VERSION ""

NS_ :

BS_:

BU_: Dummy_PHS EBOOST_OBD_PHS EOCM2cp_IMX6_PHS EOCM2cp_K1_PHS EPSb_PHS EBCM_PHS EPSa_PHS CMMb_PHS CGM3a_PHS CMMa_PHS ADIMb_PHS

BO_ 355 RedPriDynCtrlStat_PHS: 8 EBCM_PHS
 SG_ RdRghnsStatRed : 44|1@0+ (1,0) [0|1] ""  ADIMb_PHS
 SG_ RdRghnsIndctnRed : 39|5@0+ (3.2258,0) [0|100] "%"  ADIMb_PHS
 SG_ PriTCSStatRed : 17|2@0+ (1,0) [0|3] ""  ADIMb_PHS
 SG_ PriGrsHydLkDtctdRed : 43|1@0+ (1,0) [0|1] ""  ADIMb_PHS
 SG_ PriGrsHydCmpDtctdRed : 42|1@0+ (1,0) [0|1] ""  ADIMb_PHS
 SG_ PriGrsBrkIneffDtctdRed : 41|1@0+ (1,0) [0|1] ""  ADIMb_PHS
 SG_ PriESCStatRed : 25|2@0+ (1,0) [0|3] ""  ADIMb_PHS
 SG_ PriDynCtrlStatRedChksm : 50|11@0+ (1,0) [0|2047] ""  ADIMb_PHS
 SG_ PriDynCtrlStatRedARC : 52|2@0+ (1,0) [0|3] ""  ADIMb_PHS
 SG_ PriDRPStatRed : 1|2@0+ (1,0) [0|3] ""  ADIMb_PHS
 SG_ PriABSStatRed : 9|2@0+ (1,0) [0|3] ""  ADIMb_PHS
 SG_ EstBrkRtrTempStatRed : 40|1@0+ (1,0) [0|1] ""  ADIMb_PHS
 SG_ EstBrkRtrTempRRRed : 31|6@0+ (8.5714,-40) [-40|500] "deg C"  ADIMb_PHS
 SG_ EstBrkRtrTempRFRed : 15|6@0+ (8.5714,-40) [-40|500] "deg C"  ADIMb_PHS
 SG_ EstBrkRtrTempLRRed : 23|6@0+ (8.5714,-40) [-40|500] "deg C"  ADIMb_PHS
 SG_ EstBrkRtrTempLFRed : 7|6@0+ (8.5714,-40) [-40|500] "deg C"  ADIMb_PHS
 SG_ EPBStatRed : 34|2@0+ (1,0) [0|3] ""  ADIMb_PHS
 SG_ EPBApplStRed : 47|2@0+ (1,0) [0|3] ""  ADIMb_PHS
 SG_ BrkFldLvlIndStatRed : 45|1@0+ (1,0) [0|1] ""  ADIMb_PHS
 SG_ BrkFldLvILwFldDtctdRed : 32|1@0+ (1,0) [0|1] ""  ADIMb_PHS

BO_ 341 AutoSteeringStatus_PHS: 8 EPSb_PHS
 SG_ StgCmndTgtAng : 18|11@0- (1,0) [-1024|1023] "deg"  CMMb_PHS,CMMa_PHS,ADIMb_PHS,EOCM2cp_K1_PHS
 SG_ StrgCmndMsgStatV : 35|1@0+ (1,0) [0|1] ""  CMMb_PHS,CMMa_PHS,ADIMb_PHS,EOCM2cp_K1_PHS
 SG_ StrgCmndMsgStat : 5|2@0+ (1,0) [0|3] ""  CMMb_PHS,CMMa_PHS,ADIMb_PHS,EOCM2cp_K1_PHS
 SG_ StrgCmndMsgUtlzdV : 19|1@0+ (1,0) [0|1] ""  CMMb_PHS,CMMa_PHS,ADIMb_PHS,EOCM2cp_K1_PHS
 SG_ StrgCmndMsgUtlzd : 20|1@0+ (1,0) [0|1] ""  CMMb_PHS,CMMa_PHS,ADIMb_PHS,EOCM2cp_K1_PHS
 SG_ AutoStrgCmndStatV : 6|1@0+ (1,0) [0|1] ""  CMMb_PHS,CMMa_PHS,ADIMb_PHS,EOCM2cp_K1_PHS
 SG_ StgTtlEffTrqDlvd : 33|10@0- (0.25,0) [-128|127.75] ""  CMMb_PHS,CMMa_PHS,EBOOST_OBD_PHS,EBCM_PHS,ADIMb_PHS,EOCM2cp_K1_PHS
 SG_ StgTrqSnsrVStat : 39|1@0+ (1,0) [0|1] ""  CMMb_PHS,CMMa_PHS,EBOOST_OBD_PHS,EBCM_PHS,ADIMb_PHS,EOCM2cp_K1_PHS
 SG_ StgSysOtptStatV : 7|1@0+ (1,0) [0|1] ""  CMMb_PHS,CMMa_PHS,ADIMb_PHS,EOCM2cp_K1_PHS
 SG_ StgSysOtptStat : 3|2@0+ (1,0) [0|3] ""  CMMb_PHS,CMMa_PHS,ADIMb_PHS,EOCM2cp_K1_PHS
 SG_ StgOtptTempLmtgSte : 23|3@0+ (1,0) [0|7] ""  CMMb_PHS,CMMa_PHS,ADIMb_PHS,EOCM2cp_K1_PHS
 SG_ StgAngRtLmtV : 55|1@0+ (1,0) [0|1] ""  CMMb_PHS,CMMa_PHS,ADIMb_PHS,EOCM2cp_K1_PHS
 SG_ StgAngRtLmt : 1|10@0+ (1,0) [0|1023] "deg"  CMMb_PHS,CMMa_PHS,ADIMb_PHS,EOCM2cp_K1_PHS
 SG_ AutoStrgCmndStat : 38|3@0+ (1,0) [0|7] ""  CMMb_PHS,CMMa_PHS,ADIMb_PHS,EOCM2cp_K1_PHS
 SG_ AutoStgStatChksm : 50|11@0+ (1,0) [0|2047] ""  CMMb_PHS,CMMa_PHS,ADIMb_PHS,EOCM2cp_K1_PHS
 SG_ AutoStgStatARC : 52|2@0+ (1,0) [0|3] ""  CMMb_PHS,CMMa_PHS,ADIMb_PHS,EOCM2cp_K1_PHS
 SG_ StgOvrdDetn : 54|2@0+ (1,0) [0|3] ""  CMMb_PHS,CMMa_PHS,EOCM2cp_K1_PHS,ADIMb_PHS,EBOOST_OBD_PHS,EBCM_PHS

BO_ 313 Body_Information_4_PHS: 8 CGM3a_PHS
 SG_ LnchCtrlRelLnLockReqd : 15|1@0+ (1,0) [0|1] ""  EBCM_PHS
 SG_ DrvrDrOpenSwVDA : 14|1@0+ (1,0) [0|1] "" Vector__XXX
 SG_ DrDoorOpenSwActV : 12|1@0+ (1,0) [0|1] ""  EOCM2cp_IMX6_PHS
 SG_ DrDoorOpenSwAct : 11|1@0+ (1,0) [0|1] ""  EOCM2cp_IMX6_PHS
 SG_ LnchCtrlWhlSlpReq : 55|5@0+ (1,0) [0|31] ""  EOCM2cp_IMX6_PHS,EBCM_PHS
 SG_ LnchCtrlMdReq : 57|2@0+ (1,0) [0|3] ""  EOCM2cp_IMX6_PHS,EBCM_PHS
 SG_ LnchCtrlEngRPMReq : 63|6@0+ (1,0) [0|63] ""  EOCM2cp_IMX6_PHS,EBCM_PHS
 SG_ ExtHlStrAssCsStRq : 50|3@0+ (1,0) [0|7] ""  EOCM2cp_IMX6_PHS,EBCM_PHS
 SG_ DrvStyPerfMdCsStReq : 45|3@0+ (1,0) [0|7] ""  EOCM2cp_IMX6_PHS,EBCM_PHS
 SG_ PsngStPerfMdCsStReq : 42|3@0+ (1,0) [0|7] ""  EOCM2cp_IMX6_PHS,EBCM_PHS
 SG_ DrvrStPerfMdCsStReq : 31|3@0+ (1,0) [0|7] ""  EOCM2cp_IMX6_PHS,EBCM_PHS
 SG_ ACCPerfMdCsStReq : 28|3@0+ (1,0) [0|7] ""  EOCM2cp_IMX6_PHS,EBCM_PHS
 SG_ PrkAstAdvSysAct : 8|1@0+ (1,0) [0|1] ""  EOCM2cp_IMX6_PHS
 SG_ SndPerfMdCsStRq : 18|3@0+ (1,0) [0|7] ""  EBCM_PHS,EOCM2cp_IMX6_PHS
 SG_ ACCSettingType : 10|2@0+ (1,0) [0|3] ""  EOCM2cp_IMX6_PHS
 SG_ FCABrkPrflReq : 13|1@0+ (1,0) [0|1] ""  EOCM2cp_IMX6_PHS,EBCM_PHS
 SG_ ISA2CCC_ScndCdChr : 36|5@0+ (1,0) [0|31] ""  EOCM2cp_IMX6_PHS
 SG_ ISA2CCC_FrstCdChr : 25|5@0+ (1,0) [0|31] ""  EOCM2cp_IMX6_PHS
 SG_ DispPerfMdCsStRq : 21|3@0+ (1,0) [0|7] ""  EOCM2cp_IMX6_PHS,EBCM_PHS
 SG_ FwdClnAlrtCustStngReq : 5|3@0+ (1,0) [0|7] ""  EOCM2cp_IMX6_PHS
 SG_ GNCustStngReq : 7|2@0+ (1,0) [0|3] ""  EOCM2cp_IMX6_PHS

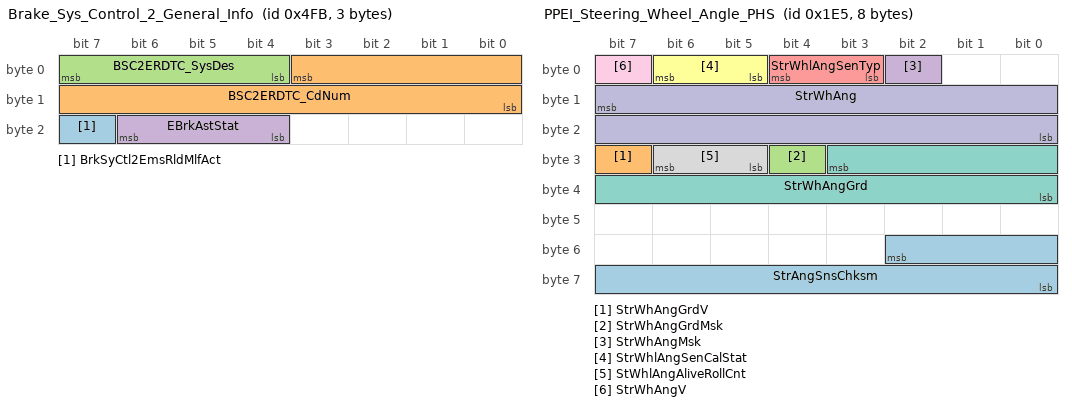
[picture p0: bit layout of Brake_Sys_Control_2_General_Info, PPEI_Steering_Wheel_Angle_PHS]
BO_ 1275 Brake_Sys_Control_2_General_Info: 3 EBOOST_OBD_PHS
 SG_ BrkSyCtl2EmsRldMlfAct : 23|1@0+ (1,0) [0|1] ""  CGM3a_PHS
 SG_ BSC2ERDTC_CdNum : 3|12@0+ (1,0) [0|4095] ""  CGM3a_PHS
 SG_ BSC2ERDTC_SysDes : 7|4@0+ (1,0) [0|15] ""  CGM3a_PHS
 SG_ EBrkAstStat : 22|3@0+ (1,0) [0|7] ""  EBCM_PHS,CGM3a_PHS

BO_ 381 Antilock_Brake_and_TC_Status_PHS: 8 EBCM_PHS
 SG_ HillDesCtrlRedVehSpIO : 39|1@0+ (1,0) [0|1] ""  CGM3a_PHS,EOCM2cp_IMX6_PHS
 SG_ EBDFailed : 23|1@0+ (1,0) [0|1] ""  CGM3a_PHS,EOCM2cp_IMX6_PHS
 SG_ StWhAnVDA : 17|1@0+ (1,0) [0|1] ""  CGM3a_PHS,EOCM2cp_IMX6_PHS
 SG_ TirePrsLowIO : 9|1@0+ (1,0) [0|1] ""  CGM3a_PHS,EOCM2cp_IMX6_PHS
 SG_ VaccBoostFailure : 16|1@0+ (1,0) [0|1] ""  CGM3a_PHS,EOCM2cp_IMX6_PHS
 SG_ VSESysPrs : 1|1@0+ (1,0) [0|1] ""  CGM3a_PHS,EOCM2cp_IMX6_PHS
 SG_ HalfSysFail : 18|1@0+ (1,0) [0|1] ""  CGM3a_PHS,EOCM2cp_IMX6_PHS
 SG_ ActVehAccel : 35|12@0- (0.01,0) [-20.48|20.47] "m/s^2"  CGM3a_PHS,EOCM2cp_IMX6_PHS
 SG_ ActVehAccelV : 20|1@0+ (1,0) [0|1] ""  CGM3a_PHS,EOCM2cp_IMX6_PHS
 SG_ BksOvht : 8|1@0+ (1,0) [0|1] ""  CGM3a_PHS,EOCM2cp_IMX6_PHS
 SG_ TCSysPr : 10|1@0+ (1,0) [0|1] ""  CGM3a_PHS,EOCM2cp_IMX6_PHS
 SG_ ABSPr : 22|1@0+ (1,0) [0|1] ""  CGM3a_PHS,EOCM2cp_IMX6_PHS
 SG_ TreInfMonSysRstPrfmd : 11|1@0+ (1,0) [0|1] ""  CGM3a_PHS,EOCM2cp_IMX6_PHS
 SG_ ABSIO : 12|1@0+ (1,0) [0|1] ""  CGM3a_PHS,EOCM2cp_IMX6_PHS
 SG_ BrkPadWrnIO : 0|1@0+ (1,0) [0|1] ""  CGM3a_PHS,EOCM2cp_IMX6_PHS
 SG_ VehStabEnhmntMd : 15|3@0+ (1,0) [0|7] ""  CGM3a_PHS,EOCM2cp_IMX6_PHS
 SG_ VehStabEnhmntStat : 4|3@0+ (1,0) [0|7] ""  CGM3a_PHS,EOCM2cp_IMX6_PHS
 SG_ TCSysOpMd : 7|3@0+ (1,0) [0|7] ""  CGM3a_PHS,EOCM2cp_IMX6_PHS
 SG_ TCSysOpStat : 38|3@0+ (1,0) [0|7] ""  CGM3a_PHS,EOCM2cp_IMX6_PHS
 SG_ BrkSysVTopSpdLimVal : 31|8@0+ (2,0) [0|510] "km / h"  CGM3a_PHS,EOCM2cp_IMX6_PHS
 SG_ BrkSysRedBrkTlltlReq : 19|1@0+ (1,0) [0|1] ""  CGM3a_PHS,EOCM2cp_IMX6_PHS
 SG_ BrkSysBrkLtsReqd : 21|1@0+ (1,0) [0|1] ""  CGM3a_PHS,EOCM2cp_IMX6_PHS

BO_ 485 PPEI_Steering_Wheel_Angle_PHS: 8 EPSb_PHS
 SG_ StrAngSnsChksm : 50|11@0+ (1,0) [0|2047] ""  CMMb_PHS,CMMa_PHS,ADIMb_PHS,EOCM2cp_K1_PHS,CGM3a_PHS
 SG_ StrWhAngGrdV : 31|1@0+ (1,0) [0|1] ""  CMMb_PHS,CMMa_PHS,ADIMb_PHS,EOCM2cp_K1_PHS,CGM3a_PHS
 SG_ StrWhAngGrdMsk : 28|1@0+ (1,0) [0|1] ""  CMMb_PHS,CMMa_PHS,ADIMb_PHS,EOCM2cp_K1_PHS,CGM3a_PHS
 SG_ StrWhAngMsk : 2|1@0+ (1,0) [0|1] ""  CMMb_PHS,CMMa_PHS,ADIMb_PHS,EOCM2cp_K1_PHS,CGM3a_PHS
 SG_ StrWhlAngSenTyp : 4|2@0+ (1,0) [0|3] ""  CMMb_PHS,CMMa_PHS,ADIMb_PHS,EOCM2cp_K1_PHS,CGM3a_PHS
 SG_ StrWhlAngSenCalStat : 6|2@0+ (1,0) [0|3] ""  CMMb_PHS,CMMa_PHS,ADIMb_PHS,EOCM2cp_K1_PHS,CGM3a_PHS
 SG_ StrWhAngGrd : 27|12@0- (1,0) [-2048|2047] "deg/sec"  CMMb_PHS,CMMa_PHS,ADIMb_PHS,EOCM2cp_K1_PHS,CGM3a_PHS
 SG_ StWhlAngAliveRollCnt : 30|2@0+ (1,0) [0|3] ""  CMMb_PHS,CMMa_PHS,ADIMb_PHS,EOCM2cp_K1_PHS,CGM3a_PHS
 SG_ StrWhAngV : 7|1@0+ (1,0) [0|1] ""  CMMb_PHS,CMMa_PHS,ADIMb_PHS,EOCM2cp_K1_PHS,CGM3a_PHS,EBCM_PHS
 SG_ StrWhAng : 15|16@0- (0.0625,0) [-2048|2047.9375] "deg"  CMMb_PHS,CMMa_PHS,ADIMb_PHS,EOCM2cp_K1_PHS,CGM3a_PHS,EBCM_PHS

BO_ 532 Brake_Pedal_Driver_Status_PHS: 6 EBCM_PHS
 SG_ RedntVSEActARC : 38|2@0+ (1,0) [0|3] ""  EOCM2cp_K1_PHS,CGM3a_PHS
 SG_ RedntVSEAct : 39|1@0+ (1,0) [0|1] ""  EOCM2cp_K1_PHS,CGM3a_PHS
 SG_ AutoBrkngActARC : 22|2@0+ (1,0) [0|3] ""  EOCM2cp_K1_PHS,CGM3a_PHS
 SG_ HilRlbkCtrlActIO : 19|1@0+ (1,0) [0|1] ""  EOCM2cp_K1_PHS,CGM3a_PHS
 SG_ VehHldDrvrDsblActvFlg : 36|1@0+ (1,0) [0|1] ""  EOCM2cp_K1_PHS,CGM3a_PHS
 SG_ ABSAutnmsBrkReqPVal : 41|2@0+ (1,0) [0|3] ""  EOCM2cp_K1_PHS,CGM3a_PHS
 SG_ AutoBrkngAvlbl : 17|1@0+ (1,0) [0|1] ""  EOCM2cp_K1_PHS,CGM3a_PHS
 SG_ ABSAutnmsBrkReqARC : 35|2@0+ (1,0) [0|3] ""  EOCM2cp_K1_PHS,CGM3a_PHS
 SG_ ABSAutnmsBrkReq : 33|1@0+ (1,0) [0|1] ""  EOCM2cp_K1_PHS,CGM3a_PHS
 SG_ ABSActvProtPVal : 43|2@0+ (1,0) [0|3] ""  EOCM2cp_K1_PHS,CGM3a_PHS
 SG_ ABSActvProtARC : 45|2@0+ (1,0) [0|3] ""  EOCM2cp_K1_PHS,CGM3a_PHS
 SG_ HlStrAssActIO : 20|1@0+ (1,0) [0|1] ""  EOCM2cp_K1_PHS,CGM3a_PHS
 SG_ BrkSysAutBrkFld : 5|1@0+ (1,0) [0|1] ""  EOCM2cp_K1_PHS,CGM3a_PHS
 SG_ IntBrkAssPreFilReq : 4|1@0+ (1,0) [0|1] "N/A"  EOCM2cp_K1_PHS,CGM3a_PHS
 SG_ BrkSysMalFuncIndOn : 3|1@0+ (1,0) [0|1] ""  EOCM2cp_K1_PHS,CGM3a_PHS
 SG_ BrkPdDrvAPrsStaPVal : 16|9@0+ (1,0) [0|511] ""  EOCM2cp_K1_PHS,CGM3a_PHS
 SG_ BPDAPS_BkPDrvApPV : 8|1@0+ (1,0) [0|1] ""  EOCM2cp_K1_PHS,CGM3a_PHS
 SG_ BPDAPS_BkPDrvApP : 0|8@0+ (75,0) [0|19125] "kPa"  EOCM2cp_K1_PHS,CGM3a_PHS
 SG_ BrkPdDrvAppPrsAlRC : 2|2@0+ (1,0) [0|3] ""  EOCM2cp_K1_PHS,CGM3a_PHS
 SG_ BrkFldLvlLwV : 7|1@0+ (1,0) [0|1] ""  EOCM2cp_K1_PHS,CGM3a_PHS
 SG_ AutoBrkngAct : 18|1@0+ (1,0) [0|1] ""  EOCM2cp_K1_PHS,CGM3a_PHS
 SG_ BrkFldLvlLw : 6|1@0+ (1,0) [0|1] ""  EOCM2cp_K1_PHS,CGM3a_PHS
 SG_ ABSActvProt : 46|1@0+ (1,0) [0|1] ""  CGM3a_PHS,EOCM2cp_K1_PHS

BO_ 489 PPEI_Chassis_Generl_Status_1_PHS: 8 EBCM_PHS
 SG_ EnhDrvMdSwChUseRq : 53|1@0+ (1,0) [0|1] ""  EOCM2cp_K1_PHS,CGM3a_PHS
 SG_ IMUDataMsk : 25|1@0+ (1,0) [0|1] ""  EOCM2cp_K1_PHS,CGM3a_PHS
 SG_ DrvIndpntBrkAppAct : 55|1@0+ (1,0) [0|1] ""  EOCM2cp_K1_PHS,CGM3a_PHS
 SG_ WhlSlpSt : 52|2@0+ (1,0) [0|3] ""  EOCM2cp_K1_PHS,CGM3a_PHS
 SG_ BSTGRReqdGear : 19|4@0+ (1,0) [0|15] ""  EOCM2cp_K1_PHS,CGM3a_PHS
 SG_ BSTGRReqType : 21|2@0+ (1,0) [0|3] ""  EOCM2cp_K1_PHS,CGM3a_PHS
 SG_ VehDynOvrUndrStr : 49|10@0- (0.5,0) [-256|255.5] "%"  EOCM2cp_K1_PHS,CGM3a_PHS
 SG_ VSELatAccV : 4|1@0+ (1,0) [0|1] ""  EPSb_PHS,EPSa_PHS,CGM3a_PHS,EOCM2cp_K1_PHS
 SG_ VSELatAcc : 3|12@0- (0.015625,0) [-32|31.984375] "m/s^2"  EPSb_PHS,EPSa_PHS,CGM3a_PHS,EOCM2cp_K1_PHS
 SG_ VSEAct : 24|1@0+ (1,0) [0|1] ""  EOCM2cp_K1_PHS,CGM3a_PHS
 SG_ VhDynCntlSysSt : 39|3@0+ (1,0) [0|7] ""  CGM3a_PHS,EOCM2cp_K1_PHS
 SG_ VehDynYawRateV : 36|1@0+ (1,0) [0|1] ""  CGM3a_PHS,EOCM2cp_K1_PHS
 SG_ VehDynYawRate : 35|12@0- (0.0625,0) [-128|127.9375] "deg/sec"  CGM3a_PHS,EOCM2cp_K1_PHS
 SG_ TrnsBrkSysCltchRelRqd : 5|1@0+ (1,0) [0|1] ""  EOCM2cp_K1_PHS,CGM3a_PHS
 SG_ TracCntrlSysDrIntnt : 26|1@0+ (1,0) [0|1] ""  EOCM2cp_K1_PHS,CGM3a_PHS
 SG_ VehDynOvrUndrStrV : 50|1@0+ (1,0) [0|1] ""  EOCM2cp_K1_PHS,CGM3a_PHS
 SG_ TCSysEnbld : 27|1@0+ (1,0) [0|1] ""  CGM3a_PHS,EOCM2cp_K1_PHS
 SG_ TCSysAtv : 28|1@0+ (1,0) [0|1] ""  CGM3a_PHS,EOCM2cp_K1_PHS
 SG_ BrkPdlDrvAppPrsDetcdV : 7|1@0+ (1,0) [0|1] ""  CGM3a_PHS,EOCM2cp_K1_PHS
 SG_ BrkPdlDrvAppPrsDetcd : 6|1@0+ (1,0) [0|1] ""  CGM3a_PHS,EOCM2cp_K1_PHS
 SG_ ACCBrkngAct : 31|1@0+ (1,0) [0|1] ""  EOCM2cp_K1_PHS,CGM3a_PHS
 SG_ ABSFld : 29|1@0+ (1,0) [0|1] ""  EOCM2cp_K1_PHS,CGM3a_PHS
 SG_ ABSAtv : 30|1@0+ (1,0) [0|1] ""  EOCM2cp_K1_PHS,CGM3a_PHS

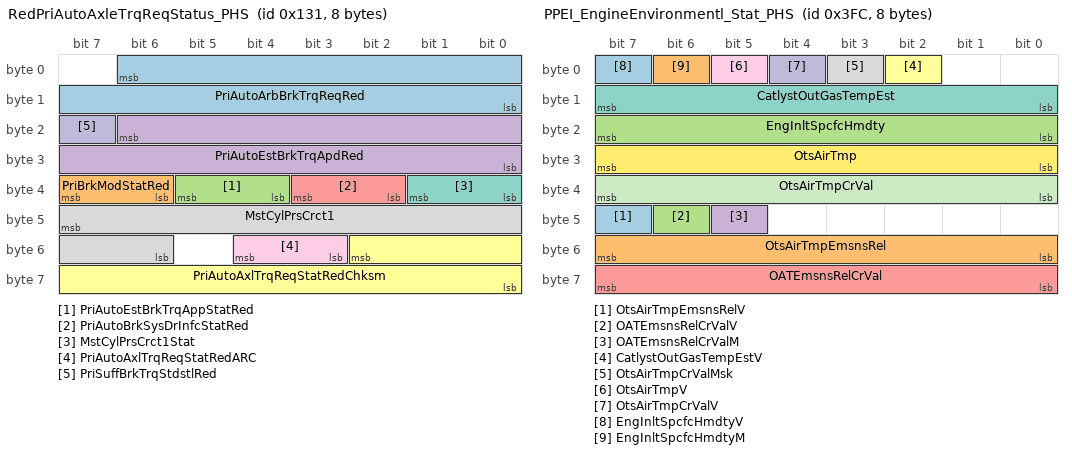
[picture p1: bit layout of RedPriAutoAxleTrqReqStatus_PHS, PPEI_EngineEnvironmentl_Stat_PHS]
BO_ 305 RedPriAutoAxleTrqReqStatus_PHS: 8 EBCM_PHS
 SG_ PriAutoArbBrkTrqReqRed : 6|15@0+ (2,-65534) [-65534|0] "Nm"  CGM3a_PHS,ADIMb_PHS
 SG_ PriBrkModStatRed : 39|2@0+ (1,0) [0|3] ""  CGM3a_PHS,ADIMb_PHS
 SG_ PriAutoEstBrkTrqAppStatRed : 37|2@0+ (1,0) [0|3] ""  CGM3a_PHS,ADIMb_PHS
 SG_ PriAutoEstBrkTrqApdRed : 22|15@0+ (2,-65534) [-65534|0] "Nm"  CGM3a_PHS,ADIMb_PHS
 SG_ PriAutoBrkSysDrInfcStatRed : 35|2@0+ (1,0) [0|3] ""  CGM3a_PHS,EBOOST_OBD_PHS,ADIMb_PHS
 SG_ PriAutoAxlTrqReqStatRedChksm : 50|11@0+ (1,0) [0|2047] ""  CGM3a_PHS,ADIMb_PHS
 SG_ MstCylPrsCrct1Stat : 33|2@0+ (1,0) [0|3] ""  CGM3a_PHS,ADIMb_PHS,EBOOST_OBD_PHS
 SG_ MstCylPrsCrct1 : 47|10@0+ (0.3,0) [0|276.6] "bar"  CGM3a_PHS,EBOOST_OBD_PHS,ADIMb_PHS
 SG_ PriAutoAxlTrqReqStatRedARC : 52|2@0+ (1,0) [0|3] ""  CGM3a_PHS,ADIMb_PHS
 SG_ PriSuffBrkTrqStdstlRed : 23|1@0+ (1,0) [0|1] ""  CGM3a_PHS,ADIMb_PHS

BO_ 1020 PPEI_EngineEnvironmentl_Stat_PHS: 8 CGM3a_PHS
 SG_ OtsAirTmpEmsnsRelV : 47|1@0+ (1,0) [0|1] "" Vector__XXX
 SG_ OtsAirTmpEmsnsRel : 55|8@0+ (0.5,-40) [-40|87.5] "deg C" Vector__XXX
 SG_ OATEmsnsRelCrValV : 46|1@0+ (1,0) [0|1] "" Vector__XXX
 SG_ OATEmsnsRelCrValM : 45|1@0+ (1,0) [0|1] "" Vector__XXX
 SG_ OATEmsnsRelCrVal : 63|8@0+ (0.5,-40) [-40|87.5] "deg C" Vector__XXX
 SG_ CatlystOutGasTempEstV : 2|1@0+ (1,0) [0|1] "" Vector__XXX
 SG_ CatlystOutGasTempEst : 15|8@0+ (5,-40) [-40|1235] "deg C" Vector__XXX
 SG_ OtsAirTmpCrValMsk : 3|1@0+ (1,0) [0|1] "" Vector__XXX
 SG_ OtsAirTmpV : 5|1@0+ (1,0) [0|1] "" Vector__XXX
 SG_ OtsAirTmpCrValV : 4|1@0+ (1,0) [0|1] "" Vector__XXX
 SG_ OtsAirTmpCrVal : 39|8@0+ (0.5,-40) [-40|87.5] "deg C" Vector__XXX
 SG_ OtsAirTmp : 31|8@0+ (0.5,-40) [-40|87.5] "deg C" Vector__XXX
 SG_ EngInltSpcfcHmdtyV : 7|1@0+ (1,0) [0|1] ""  EBCM_PHS
 SG_ EngInltSpcfcHmdtyM : 6|1@0+ (1,0) [0|1] ""  EBCM_PHS
 SG_ EngInltSpcfcHmdty : 23|8@0+ (0.0196078,0) [0|4.999989] "% water"  EBCM_PHS

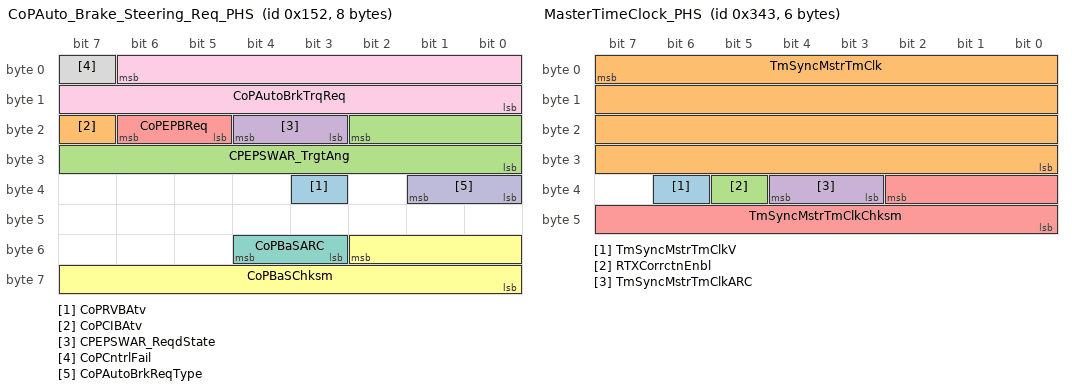
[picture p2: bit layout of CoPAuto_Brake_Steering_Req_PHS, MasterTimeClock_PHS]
BO_ 338 CoPAuto_Brake_Steering_Req_PHS: 8 EOCM2cp_K1_PHS
 SG_ CoPRVBAtv : 35|1@0+ (1,0) [0|1] ""  ADIMb_PHS,EBOOST_OBD_PHS,EBCM_PHS
 SG_ CoPCIBAtv : 23|1@0+ (1,0) [0|1] ""  ADIMb_PHS,EBOOST_OBD_PHS,EBCM_PHS
 SG_ CPEPSWAR_TrgtAng : 18|11@0- (1,0) [-1024|1023] "deg"  ADIMb_PHS,EBOOST_OBD_PHS,EBCM_PHS
 SG_ CPEPSWAR_ReqdState : 20|2@0+ (1,0) [0|3] ""  ADIMb_PHS,EBOOST_OBD_PHS,EBCM_PHS
 SG_ CoPEPBReq : 22|2@0+ (1,0) [0|3] ""  ADIMb_PHS,EBOOST_OBD_PHS,EBCM_PHS
 SG_ CoPBaSChksm : 50|11@0+ (1,0) [0|2047] ""  ADIMb_PHS,EBOOST_OBD_PHS,EBCM_PHS
 SG_ CoPBaSARC : 52|2@0+ (1,0) [0|3] ""  ADIMb_PHS,EBOOST_OBD_PHS,EBCM_PHS
 SG_ CoPCntrlFail : 7|1@0+ (1,0) [0|1] ""  ADIMb_PHS,EBOOST_OBD_PHS,EBCM_PHS
 SG_ CoPAutoBrkTrqReq : 6|15@0+ (2,-65534) [-65534|0] "Nm"  ADIMb_PHS,EBOOST_OBD_PHS,EBCM_PHS
 SG_ CoPAutoBrkReqType : 33|2@0+ (1,0) [0|3] ""  ADIMb_PHS,EBOOST_OBD_PHS,EBCM_PHS

BO_ 835 MasterTimeClock_PHS: 6 EOCM2cp_K1_PHS
 SG_ TmSyncMstrTmClkV : 38|1@0+ (1,0) [0|1] ""  CGM3a_PHS
 SG_ TmSyncMstrTmClk : 7|32@0+ (1,0) [0|4294967295] "ms"  CGM3a_PHS
 SG_ RTXCorrctnEnbl : 37|1@0+ (1,0) [0|1] ""  CGM3a_PHS
 SG_ TmSyncMstrTmClkARC : 36|2@0+ (1,0) [0|3] ""  CGM3a_PHS
 SG_ TmSyncMstrTmClkChksm : 34|11@0+ (1,0) [0|2047] ""  CGM3a_PHS

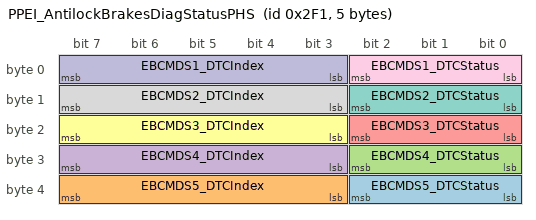
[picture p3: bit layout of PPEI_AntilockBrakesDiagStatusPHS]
BO_ 753 PPEI_AntilockBrakesDiagStatusPHS: 5 EBCM_PHS
 SG_ EBCMDS5_DTCStatus : 34|3@0+ (1,0) [0|7] ""  CGM3a_PHS
 SG_ EBCMDS5_DTCIndex : 39|5@0+ (1,0) [0|31] ""  CGM3a_PHS
 SG_ EBCMDS4_DTCStatus : 26|3@0+ (1,0) [0|7] ""  CGM3a_PHS
 SG_ EBCMDS4_DTCIndex : 31|5@0+ (1,0) [0|31] ""  CGM3a_PHS
 SG_ EBCMDS3_DTCStatus : 18|3@0+ (1,0) [0|7] ""  CGM3a_PHS
 SG_ EBCMDS3_DTCIndex : 23|5@0+ (1,0) [0|31] ""  CGM3a_PHS
 SG_ EBCMDS2_DTCStatus : 10|3@0+ (1,0) [0|7] ""  CGM3a_PHS
 SG_ EBCMDS2_DTCIndex : 15|5@0+ (1,0) [0|31] ""  CGM3a_PHS
 SG_ EBCMDS1_DTCStatus : 2|3@0+ (1,0) [0|7] ""  CGM3a_PHS
 SG_ EBCMDS1_DTCIndex : 7|5@0+ (1,0) [0|31] ""  CGM3a_PHS

BO_ 869 CPS_Collision_Preparation_IO_PHS: 4 EOCM2cp_K1_PHS
 SG_ TnDrvGapAdjUnbIO : 4|1@0+ (1,0) [0|1] ""  CGM3a_PHS
 SG_ CPSCA_Resrv3Avail : 25|1@0+ (1,0) [0|1] ""  CGM3a_PHS
 SG_ CPSCA_Resrv2Avail : 26|1@0+ (1,0) [0|1] ""  CGM3a_PHS
 SG_ CPSCA_Resrv1Avail : 27|1@0+ (1,0) [0|1] ""  CGM3a_PHS
 SG_ CPSCA_AlrtBrkStrAvail : 28|1@0+ (1,0) [0|1] ""  CGM3a_PHS
 SG_ CPSCA_AlrtBrkAvail : 29|1@0+ (1,0) [0|1] ""  CGM3a_PHS
 SG_ CPSCA_AlrtAvail : 30|1@0+ (1,0) [0|1] ""  CGM3a_PHS
 SG_ CPSCA_OffAvail : 31|1@0+ (1,0) [0|1] ""  CGM3a_PHS
 SG_ FwdClnMtgnBrkReqAct : 3|1@0+ (1,0) [0|1] ""  CGM3a_PHS
 SG_ FCACustStngAvlbl : 23|1@0+ (1,0) [0|1] ""  CGM3a_PHS
 SG_ FwdClnAlrtCustCrntSetngVal : 12|3@0+ (1,0) [0|7] ""  CGM3a_PHS
 SG_ GNCustSetngAvlbl : 9|1@0+ (1,0) [0|1] ""  CGM3a_PHS
 SG_ CPSUnblIO : 8|1@0+ (1,0) [0|1] ""  CGM3a_PHS
 SG_ ColPrSysStngAvl : 7|1@0+ (1,0) [0|1] ""  CGM3a_PHS
 SG_ CPSOffIO : 6|1@0+ (1,0) [0|1] ""  CGM3a_PHS
 SG_ CPSFldIO : 5|1@0+ (1,0) [0|1] ""  CGM3a_PHS
 SG_ ColPrSysCrntStng : 22|3@0+ (1,0) [0|7] ""  CGM3a_PHS
 SG_ CPSAlrtOnlIO : 2|1@0+ (1,0) [0|1] ""  CGM3a_PHS
 SG_ GNCustCrntStngVal : 15|3@0+ (1,0) [0|7] ""  CGM3a_PHS
 SG_ CoPilotWndShldWashReqAct : 24|1@0+ (1,0) [0|1] ""  CGM3a_PHS

BO_ 1217 PPEI_Engine_General_Status_4_PHS: 8 CGM3a_PHS
 SG_ LDMinEngCltTmpRchd : 43|1@0+ (1,0) [0|1] "" Vector__XXX
 SG_ LegPstDTCClrDrvCyCm : 40|1@0+ (1,0) [0|1] ""  EBCM_PHS,EBOOST_OBD_PHS
 SG_ LegDiagColdStCndMet : 47|1@0+ (1,0) [0|1] ""  EBCM_PHS
 SG_ LegDiagColdStCndFltPr : 46|1@0+ (1,0) [0|1] ""  EBCM_PHS
 SG_ EngEconMdCmnd : 44|1@0+ (1,0) [0|1] "" Vector__XXX
 SG_ DslExhFldRmngDstHRsV : 41|1@0+ (1,0) [0|1] "" Vector__XXX
 SG_ DslExhFldRmngDstHRs : 54|15@0+ (2,0) [0|65534] "km" Vector__XXX
 SG_ EngOilHotIO : 45|1@0+ (1,0) [0|1] "" Vector__XXX
 SG_ OAT_PT_EstV : 3|1@0+ (1,0) [0|1] ""  EBCM_PHS
 SG_ LegDiagStndCndMet : 2|1@0+ (1,0) [0|1] ""  EBCM_PHS
 SG_ LegDiagStndCndFltPr : 1|1@0+ (1,0) [0|1] ""  EBCM_PHS
 SG_ OAT_PT_EstM : 4|1@0+ (1,0) [0|1] ""  EBCM_PHS
 SG_ OAT_PT_Est : 39|8@0+ (0.5,-40) [-40|87.5] "deg C"  EBCM_PHS
 SG_ EngWrmUpAch : 0|1@0+ (1,0) [0|1] ""  EBOOST_OBD_PHS,EBCM_PHS
 SG_ EngIntAirTmpV : 5|1@0+ (1,0) [0|1] ""  EBCM_PHS
 SG_ EngIntAirTmp : 31|8@0+ (1,-40) [-40|215] "deg C"  EBCM_PHS
 SG_ EngCltTmpV : 6|1@0+ (1,0) [0|1] ""  EBCM_PHS,EPSb_PHS,EPSa_PHS
 SG_ EngCltTmp : 23|8@0+ (1,-40) [-40|215] "deg C"  EBCM_PHS,EPSb_PHS,EPSa_PHS
 SG_ BarPrsAbsV : 7|1@0+ (1,0) [0|1] ""  EBCM_PHS
 SG_ BarPrsAbs : 15|8@0+ (0.5,0) [0|127.5] "kPa"  EBCM_PHS

BO_ 328 Power_Steering_Information_PHS: 1 EPSa_PHS
 SG_ StrngAsstRdcdIO : 1|1@0+ (1,0) [0|1] ""  CGM3a_PHS
 SG_ PwrStrIO : 0|1@0+ (1,0) [0|1] ""  CGM3a_PHS

BO_ 309 Body_Information_2_PHS: 8 CGM3a_PHS
 SG_ PedFrndlyAlrtSndMnAct : 8|1@0+ (1,0) [0|1] "" Vector__XXX
 SG_ ColPrSysCustReq : 15|3@0+ (1,0) [0|7] ""  EOCM2cp_IMX6_PHS
 SG_ SecV : 62|1@0+ (1,0) [0|1] ""  EOCM2cp_IMX6_PHS
 SG_ Sec : 61|6@0+ (1,0) [0|63] "s"  EOCM2cp_IMX6_PHS
 SG_ CldrYr_154 : 55|8@0+ (1,2000) [2000|2255] "year"  EOCM2cp_IMX6_PHS
 SG_ CldrYr : 47|8@0+ (1,2000) [2000|2255] "year"  EBCM_PHS,EOCM2cp_IMX6_PHS
 SG_ CldrMth_154 : 39|4@0+ (1,0) [0|15] ""  EOCM2cp_IMX6_PHS
 SG_ CldrMth : 35|4@0+ (1,0) [0|15] ""  EBCM_PHS,EOCM2cp_IMX6_PHS
 SG_ CldrDay_154 : 30|5@0+ (1,0) [0|31] "days"  EOCM2cp_IMX6_PHS
 SG_ CldrDay : 20|5@0+ (1,0) [0|31] "days"  EBCM_PHS,EOCM2cp_IMX6_PHS
 SG_ AutoHiBmVDA : 25|1@0+ (1,0) [0|1] ""  EOCM2cp_IMX6_PHS
 SG_ CtLghtDet : 24|1@0+ (1,0) [0|1] ""  EOCM2cp_IMX6_PHS
 SG_ RrClosVDA : 11|1@0+ (1,0) [0|1] ""  EOCM2cp_IMX6_PHS
 SG_ TCSysDisSwAtv : 4|1@0+ (1,0) [0|1] ""  EBCM_PHS,EOCM2cp_IMX6_PHS
 SG_ VehMovState : 2|3@0+ (1,0) [0|7] ""  EOCM2cp_IMX6_PHS
 SG_ TCSysDisSwAtvV : 3|1@0+ (1,0) [0|1] ""  EBCM_PHS,EOCM2cp_IMX6_PHS
 SG_ HillDesCtrlMdSwActV : 10|1@0+ (1,0) [0|1] ""  EBCM_PHS,EOCM2cp_IMX6_PHS
 SG_ WSWshSwAtv : 5|1@0+ (1,0) [0|1] ""  EOCM2cp_IMX6_PHS
 SG_ HillDesCtrlMdSwAct : 9|1@0+ (1,0) [0|1] ""  EBCM_PHS,EOCM2cp_IMX6_PHS
 SG_ RrClosAjarSwAct : 12|1@0+ (1,0) [0|1] ""  EOCM2cp_IMX6_PHS
 SG_ WSWprAct : 6|1@0+ (1,0) [0|1] ""  EOCM2cp_IMX6_PHS,EBCM_PHS

BO_ 1622 USDT_Resp_From_CMMb_PHS: 8 CMMb_PHS
 SG_ DgnInf : 7|64@0+ (1,0) [0|1.84467440737096E+019] ""  CGM3a_PHS

BO_ 1905 DTC_Triggered_771_PHS: 7 EBOOST_OBD_PHS
 SG_ DTCI_DTCFaultType_771 : 55|8@0+ (1,0) [0|255] ""  CGM3a_PHS
 SG_ DTCI_CodeSupported_771 : 40|1@0+ (1,0) [0|1] ""  CGM3a_PHS
 SG_ DTCI_CurrentStatus_771 : 41|1@0+ (1,0) [0|1] ""  CGM3a_PHS
 SG_ DTCI_TstNPsdCdClrdSt_771 : 42|1@0+ (1,0) [0|1] ""  CGM3a_PHS
 SG_ DTCI_TstFldCdClrdStat_771 : 43|1@0+ (1,0) [0|1] ""  CGM3a_PHS
 SG_ DTCI_HistStat_771 : 44|1@0+ (1,0) [0|1] ""  CGM3a_PHS
 SG_ DTCI_TstNPsdPwrUpSt_771 : 45|1@0+ (1,0) [0|1] ""  CGM3a_PHS
 SG_ DTCI_TstFldPwrUpSt_771 : 46|1@0+ (1,0) [0|1] ""  CGM3a_PHS
 SG_ DTCI_WrnIndRqdSt_771 : 47|1@0+ (1,0) [0|1] ""  CGM3a_PHS
 SG_ DTCI_DTCFailType_771 : 39|8@0+ (1,0) [0|255] ""  CGM3a_PHS
 SG_ DTCI_DTCNumber_771 : 23|16@0+ (1,0) [0|65535] ""  CGM3a_PHS
 SG_ DTCI_DTCSource_771 : 15|8@0+ (1,0) [0|255] ""  CGM3a_PHS
 SG_ DTCI_DTCTriggered_771 : 0|1@0+ (1,0) [0|1] ""  CGM3a_PHS
 SG_ DTCIUnused7_771 : 1|1@0+ (1,0) [0|1] ""  CGM3a_PHS
 SG_ DTCIUnused6_771 : 2|1@0+ (1,0) [0|1] ""  CGM3a_PHS
 SG_ DTCIUnused5_771 : 3|1@0+ (1,0) [0|1] ""  CGM3a_PHS
 SG_ DTCIUnused4_771 : 4|1@0+ (1,0) [0|1] ""  CGM3a_PHS
 SG_ DTCIUnused3_771 : 5|1@0+ (1,0) [0|1] ""  CGM3a_PHS
 SG_ DTCIUnused2_771 : 6|1@0+ (1,0) [0|1] ""  CGM3a_PHS
 SG_ DTCIUnused1_771 : 7|1@0+ (1,0) [0|1] ""  CGM3a_PHS

BO_ 1930 DTC_Triggered_78A_PHS: 7 EOCM2cp_K1_PHS
 SG_ DTCI_CodeSupported_78A : 40|1@0+ (1,0) [0|1] ""  CGM3a_PHS
 SG_ DTCI_CurrentStatus_78A : 41|1@0+ (1,0) [0|1] ""  CGM3a_PHS
 SG_ DTCI_DTCFailType_78A : 39|8@0+ (1,0) [0|255] ""  CGM3a_PHS
 SG_ DTCI_DTCFaultType_78A : 55|8@0+ (1,0) [0|255] ""  CGM3a_PHS
 SG_ DTCI_DTCNumber_78A : 23|16@0+ (1,0) [0|65535] ""  CGM3a_PHS
 SG_ DTCI_DTCSource_78A : 15|8@0+ (1,0) [0|255] ""  CGM3a_PHS
 SG_ DTCI_DTCTriggered_78A : 0|1@0+ (1,0) [0|1] ""  CGM3a_PHS
 SG_ DTCI_HistStat_78A : 44|1@0+ (1,0) [0|1] ""  CGM3a_PHS
 SG_ DTCI_TstFldCdClrdStat_78A : 43|1@0+ (1,0) [0|1] ""  CGM3a_PHS
 SG_ DTCI_TstFldPwrUpSt_78A : 46|1@0+ (1,0) [0|1] ""  CGM3a_PHS
 SG_ DTCI_TstNPsdCdClrdSt_78A : 42|1@0+ (1,0) [0|1] ""  CGM3a_PHS
 SG_ DTCI_TstNPsdPwrUpSt_78A : 45|1@0+ (1,0) [0|1] ""  CGM3a_PHS
 SG_ DTCIUnused1_78A : 7|1@0+ (1,0) [0|1] ""  CGM3a_PHS
 SG_ DTCIUnused2_78A : 6|1@0+ (1,0) [0|1] ""  CGM3a_PHS
 SG_ DTCIUnused3_78A : 5|1@0+ (1,0) [0|1] ""  CGM3a_PHS
 SG_ DTCIUnused4_78A : 4|1@0+ (1,0) [0|1] ""  CGM3a_PHS
 SG_ DTCIUnused5_78A : 3|1@0+ (1,0) [0|1] ""  CGM3a_PHS
 SG_ DTCIUnused6_78A : 2|1@0+ (1,0) [0|1] ""  CGM3a_PHS
 SG_ DTCIUnused7_78A : 1|1@0+ (1,0) [0|1] ""  CGM3a_PHS
 SG_ DTCI_WrnIndRqdSt_78A : 47|1@0+ (1,0) [0|1] ""  CGM3a_PHS

CM_ SG_ 381 BrkSysRedBrkTlltlReq "Added acc to Björn 0410";
CM_ BO_ 485 "6443-Power Steering Indication On in this frame not used by GlobalA /JD";
CM_ SG_ 532 BrkSysAutBrkFld "BrakeSystemAutomaticBrakingFailed";
CM_ SG_ 532 IntBrkAssPreFilReq "IntelligentBrakeAssistPreFillRequest";
CM_ BO_ 489 "Changed for PPEI 3.6";
CM_ BO_ 869 "Note that the ACC and EBCM algorithm will transmit this message at a 50 ms periodic rate and the EOCM algorithm will transmit this message at a 40 ms periodic rate";
CM_ SG_ 1905 DTCI_DTCFaultType_771 "Based on Powertrain definition.  Not expected to be supported by all devices.";
CM_ SG_ 1905 DTCI_DTCFailType_771 "Assigned per GMW3110, Appendix E";
CM_ SG_ 1905 DTCI_DTCSource_771 "This shall be equal to the Diagnostic Address of the transmittting device.";
CM_ SG_ 1930 DTCI_DTCFailType_78A "Assigned per GMW3110, Appendix E";
CM_ SG_ 1930 DTCI_DTCFaultType_78A "Based on Powertrain definition.  Not expected to be supported by all devices.";
CM_ SG_ 1930 DTCI_DTCSource_78A "This shall be equal to the Diagnostic Address of the transmittting device.";
BA_DEF_ SG_  "VNSigSLHSSharedDiagnostic" ENUM  "No","Yes";
BA_DEF_ SG_  "SignalType" STRING ;
BA_DEF_ SG_  "PacketOrder" INT 0 65535;
BA_DEF_ SG_  "SignalLongName" STRING ;
BA_DEF_ SG_  "GenSigStartValue" INT 0 65535;
BA_DEF_ SG_  "VNSigAllNodes" ENUM  "No","Yes";
BA_DEF_ SG_  "GenSigSendType" ENUM  "not used","not used","not used","not used","not used","not used","not used","NoSigSendType","not used","not used","OnAnyChange","OnChangeIfActive","OnDelta";
BA_DEF_ SG_  "GenSigSendOnInit" ENUM  "Not Initialized","Application","Handler";
BA_DEF_ BO_  "AppGenMsgCycleTime" INT 0 0;
BA_DEF_ BO_  "GenMsgILSupport" ENUM  "No","Yes";
BA_DEF_ BO_  "TpApplType" STRING ;
BA_DEF_ BO_  "Prio" INT 0 7;
BA_DEF_ BO_  "MessageSubnet" ENUM  "LS","HS","CE","PE","HV","FO","LE","HE2","PHS","PCE","DLCLS","DLCHS","DLCCE","DLCFO";
BA_DEF_ BO_  "DiagState" ENUM  "No","Yes";
BA_DEF_ BO_  "GenMsgStartDelayTime" INT 0 100000;
BA_DEF_ BO_  "GenMsgDelayTime" INT 0 100000;
BA_DEF_ BO_  "GenMsgCycleTime" INT 0 100000;
BA_DEF_ BO_  "GenMsgSendType" ENUM  "cyclicX","spontanX","cyclicIfActiveX","spontanWithDelay","cyclicAndSpontanX","cyclicAndSpontanWithDelay","spontanWithRepitition","cyclicIfActiveAndSpontanWD";
BA_DEF_ BO_  "DiagResponse" ENUM  "No","Yes";
BA_DEF_ BO_  "DiagRequest" ENUM  "No","Yes";
BA_DEF_ BO_  "NmMessage" ENUM  "No","Yes";
BA_DEF_REL_ BU_SG_REL_  "GenSigSuprvRespComment" STRING ;
BA_DEF_REL_ BU_SG_REL_  "GenSigVBitResp" ENUM  "No","Yes";
BA_DEF_REL_ BU_SG_REL_  "GenSigVBitRespComment" STRING ;
BA_DEF_REL_ BU_SG_REL_  "GenSigVDAFailComment" STRING ;
BA_DEF_REL_ BU_SG_REL_  "GenSigVDAFailResp" ENUM  "No","Yes";
BA_DEF_REL_ BU_SG_REL_  "GenSigRxStartValue" STRING ;
BA_DEF_REL_ BU_SG_REL_  "GenSigSuprvResp" ENUM  "None","Notify App","Substitute Default";
BA_DEF_REL_ BU_SG_REL_  "GenSigTimeoutMsg" HEX 0 268435455;
BA_DEF_REL_ BU_SG_REL_  "GenSigTimeoutTime" INT 0 15000;
BA_DEF_DEF_  "VNSigSLHSSharedDiagnostic" "No";
BA_DEF_DEF_  "SignalType" "";
BA_DEF_DEF_  "PacketOrder" 0;
BA_DEF_DEF_  "SignalLongName" "";
BA_DEF_DEF_  "GenSigStartValue" 0;
BA_DEF_DEF_  "VNSigAllNodes" "No";
BA_DEF_DEF_  "GenSigSendType" "NoSigSendType";
BA_DEF_DEF_  "GenSigSendOnInit" "Not Initialized";
BA_DEF_DEF_  "AppGenMsgCycleTime" 0;
BA_DEF_DEF_  "GenMsgILSupport" "Yes";
BA_DEF_DEF_  "TpApplType" "";
BA_DEF_DEF_  "Prio" 4;
BA_DEF_DEF_  "MessageSubnet" "LS";
BA_DEF_DEF_  "DiagState" "No";
BA_DEF_DEF_  "GenMsgStartDelayTime" 0;
BA_DEF_DEF_  "GenMsgDelayTime" 0;
BA_DEF_DEF_  "GenMsgCycleTime" 0;
BA_DEF_DEF_  "GenMsgSendType" "spontanX";
BA_DEF_DEF_  "DiagResponse" "No";
BA_DEF_DEF_  "DiagRequest" "No";
BA_DEF_DEF_  "NmMessage" "No";
BA_DEF_DEF_REL_ "GenSigSuprvRespComment" "";
BA_DEF_DEF_REL_ "GenSigVBitResp" "No";
BA_DEF_DEF_REL_ "GenSigVBitRespComment" "";
BA_DEF_DEF_REL_ "GenSigVDAFailComment" "";
BA_DEF_DEF_REL_ "GenSigVDAFailResp" "No";
BA_DEF_DEF_REL_ "GenSigRxStartValue" "";
BA_DEF_DEF_REL_ "GenSigSuprvResp" "None";
BA_DEF_DEF_REL_ "GenSigTimeoutMsg" 0;
BA_DEF_DEF_REL_ "GenSigTimeoutTime" 0;
BA_ "MessageSubnet" BO_ 355 8;
BA_ "GenMsgCycleTime" BO_ 355 10;
BA_ "GenMsgSendType" BO_ 355 0;
BA_ "Prio" BO_ 341 0;
BA_ "MessageSubnet" BO_ 341 8;
BA_ "GenMsgCycleTime" BO_ 341 10;
BA_ "GenMsgSendType" BO_ 341 0;
BA_ "Prio" BO_ 313 0;
BA_ "MessageSubnet" BO_ 313 8;
BA_ "GenMsgStartDelayTime" BO_ 313 70;
BA_ "GenMsgCycleTime" BO_ 313 100;
BA_ "GenMsgSendType" BO_ 313 0;
BA_ "Prio" BO_ 1275 0;
BA_ "MessageSubnet" BO_ 1275 8;
BA_ "GenMsgCycleTime" BO_ 1275 500;
BA_ "GenMsgSendType" BO_ 1275 0;
BA_ "Prio" BO_ 381 0;
BA_ "MessageSubnet" BO_ 381 8;
BA_ "GenMsgCycleTime" BO_ 381 100;
BA_ "GenMsgSendType" BO_ 381 0;
BA_ "Prio" BO_ 485 0;
BA_ "MessageSubnet" BO_ 485 8;
BA_ "GenMsgCycleTime" BO_ 485 10;
BA_ "GenMsgSendType" BO_ 485 0;
BA_ "Prio" BO_ 532 0;
BA_ "MessageSubnet" BO_ 532 8;
BA_ "GenMsgCycleTime" BO_ 532 50;
BA_ "GenMsgSendType" BO_ 532 0;
BA_ "Prio" BO_ 489 0;
BA_ "MessageSubnet" BO_ 489 8;
BA_ "GenMsgCycleTime" BO_ 489 20;
BA_ "GenMsgSendType" BO_ 489 0;
BA_ "Prio" BO_ 305 0;
BA_ "MessageSubnet" BO_ 305 8;
BA_ "GenMsgCycleTime" BO_ 305 10;
BA_ "GenMsgSendType" BO_ 305 0;
BA_ "Prio" BO_ 1020 0;
BA_ "MessageSubnet" BO_ 1020 8;
BA_ "GenMsgCycleTime" BO_ 1020 250;
BA_ "GenMsgSendType" BO_ 1020 0;
BA_ "Prio" BO_ 338 0;
BA_ "MessageSubnet" BO_ 338 8;
BA_ "GenMsgCycleTime" BO_ 338 10;
BA_ "GenMsgSendType" BO_ 338 0;
BA_ "Prio" BO_ 835 0;
BA_ "MessageSubnet" BO_ 835 8;
BA_ "GenMsgCycleTime" BO_ 835 100;
BA_ "GenMsgSendType" BO_ 835 0;
BA_ "Prio" BO_ 753 0;
BA_ "MessageSubnet" BO_ 753 8;
BA_ "GenMsgCycleTime" BO_ 753 100;
BA_ "GenMsgSendType" BO_ 753 0;
BA_ "AppGenMsgCycleTime" BO_ 869 40;
BA_ "Prio" BO_ 869 0;
BA_ "MessageSubnet" BO_ 869 8;
BA_ "Prio" BO_ 1217 0;
BA_ "MessageSubnet" BO_ 1217 8;
BA_ "GenMsgCycleTime" BO_ 1217 500;
BA_ "GenMsgSendType" BO_ 1217 0;
BA_ "Prio" BO_ 328 0;
BA_ "MessageSubnet" BO_ 328 8;
BA_ "GenMsgDelayTime" BO_ 328 100;
BA_ "GenMsgCycleTime" BO_ 328 1000;
BA_ "GenMsgSendType" BO_ 328 0;
BA_ "Prio" BO_ 309 0;
BA_ "MessageSubnet" BO_ 309 8;
BA_ "GenMsgStartDelayTime" BO_ 309 50;
BA_ "GenMsgCycleTime" BO_ 309 100;
BA_ "GenMsgSendType" BO_ 309 0;
BA_ "Prio" BO_ 1622 0;
BA_ "MessageSubnet" BO_ 1622 8;
BA_ "DiagResponse" BO_ 1622 1;
BA_ "Prio" BO_ 1905 0;
BA_ "MessageSubnet" BO_ 1905 8;
BA_ "GenMsgCycleTime" BO_ 1905 1000;
BA_ "GenMsgSendType" BO_ 1905 0;
BA_ "Prio" BO_ 1930 0;
BA_ "MessageSubnet" BO_ 1930 8;
BA_ "GenMsgCycleTime" BO_ 1930 1000;
BA_ "GenMsgSendType" BO_ 1930 0;
BA_ "SignalType" SG_ 355 RdRghnsStatRed "ENM";
BA_ "SignalLongName" SG_ 355 RdRghnsStatRed "Road Roughness Status Redundant";
BA_ "VNSigAllNodes" SG_ 355 RdRghnsStatRed 1;
BA_ "SignalType" SG_ 355 RdRghnsIndctnRed "UNM";
BA_ "SignalLongName" SG_ 355 RdRghnsIndctnRed "Road Roughness Indication Redundant";
BA_ "VNSigAllNodes" SG_ 355 RdRghnsIndctnRed 1;
BA_ "SignalType" SG_ 355 PriTCSStatRed "ENM";
BA_ "SignalLongName" SG_ 355 PriTCSStatRed "Primary Traction Control System Status Redundant";
BA_ "VNSigAllNodes" SG_ 355 PriTCSStatRed 1;
BA_ "SignalType" SG_ 355 PriGrsHydLkDtctdRed "BLN";
BA_ "SignalLongName" SG_ 355 PriGrsHydLkDtctdRed "Primary Gross Hydraulic Leak Detected Redundant";
BA_ "VNSigAllNodes" SG_ 355 PriGrsHydLkDtctdRed 1;
BA_ "SignalType" SG_ 355 PriGrsHydCmpDtctdRed "BLN";
BA_ "SignalLongName" SG_ 355 PriGrsHydCmpDtctdRed "Primary Gross Hydraulic Compliance Detected Redundant";
BA_ "VNSigAllNodes" SG_ 355 PriGrsHydCmpDtctdRed 1;
BA_ "SignalType" SG_ 355 PriGrsBrkIneffDtctdRed "BLN";
BA_ "SignalLongName" SG_ 355 PriGrsBrkIneffDtctdRed "Primary Gross Brake Ineffectiveness Detected Redundant";
BA_ "VNSigAllNodes" SG_ 355 PriGrsBrkIneffDtctdRed 1;
BA_ "SignalType" SG_ 355 PriESCStatRed "ENM";
BA_ "SignalLongName" SG_ 355 PriESCStatRed "Primary Electronic Stability Control System Status Redundant";
BA_ "VNSigAllNodes" SG_ 355 PriESCStatRed 1;
BA_ "SignalType" SG_ 355 PriDynCtrlStatRedChksm "UNM";
BA_ "SignalLongName" SG_ 355 PriDynCtrlStatRedChksm "Primary Dynamic Control Status Redundant Checksum";
BA_ "VNSigAllNodes" SG_ 355 PriDynCtrlStatRedChksm 1;
BA_ "SignalType" SG_ 355 PriDynCtrlStatRedARC "UNM";
BA_ "SignalLongName" SG_ 355 PriDynCtrlStatRedARC "Primary Dynamic Control Status Redundant Alive Rolling Count";
BA_ "VNSigAllNodes" SG_ 355 PriDynCtrlStatRedARC 1;
BA_ "SignalType" SG_ 355 PriDRPStatRed "ENM";
BA_ "SignalLongName" SG_ 355 PriDRPStatRed "Primary Dynamic Rear Proportioning Status Redundant";
BA_ "VNSigAllNodes" SG_ 355 PriDRPStatRed 1;
BA_ "SignalType" SG_ 355 PriABSStatRed "ENM";
BA_ "SignalLongName" SG_ 355 PriABSStatRed "Primary Antilock Brake System Status Redundant";
BA_ "VNSigAllNodes" SG_ 355 PriABSStatRed 1;
BA_ "SignalType" SG_ 355 EstBrkRtrTempStatRed "ENM";
BA_ "SignalLongName" SG_ 355 EstBrkRtrTempStatRed "Estimated Brake Rotor Temperature Status Redundant";
BA_ "VNSigAllNodes" SG_ 355 EstBrkRtrTempStatRed 1;
BA_ "SignalType" SG_ 355 EstBrkRtrTempRRRed "UNM";
BA_ "SignalLongName" SG_ 355 EstBrkRtrTempRRRed "Estimated Brake Rotor Temperature Right Rear Redundant";
BA_ "GenSigStartValue" SG_ 355 EstBrkRtrTempRRRed 5;
BA_ "VNSigAllNodes" SG_ 355 EstBrkRtrTempRRRed 1;
BA_ "SignalType" SG_ 355 EstBrkRtrTempRFRed "UNM";
BA_ "SignalLongName" SG_ 355 EstBrkRtrTempRFRed "Estimated Brake Rotor Temperature Right Front Redundant";
BA_ "GenSigStartValue" SG_ 355 EstBrkRtrTempRFRed 5;
BA_ "VNSigAllNodes" SG_ 355 EstBrkRtrTempRFRed 1;
BA_ "SignalType" SG_ 355 EstBrkRtrTempLRRed "UNM";
BA_ "SignalLongName" SG_ 355 EstBrkRtrTempLRRed "Estimated Brake Rotor Temperature Left Rear Redundant";
BA_ "GenSigStartValue" SG_ 355 EstBrkRtrTempLRRed 5;
BA_ "VNSigAllNodes" SG_ 355 EstBrkRtrTempLRRed 1;
BA_ "SignalType" SG_ 355 EstBrkRtrTempLFRed "UNM";
BA_ "SignalLongName" SG_ 355 EstBrkRtrTempLFRed "Estimated Brake Rotor Temperature Left Front Redundant";
BA_ "GenSigStartValue" SG_ 355 EstBrkRtrTempLFRed 5;
BA_ "VNSigAllNodes" SG_ 355 EstBrkRtrTempLFRed 1;
BA_ "SignalType" SG_ 355 EPBStatRed "ENM";
BA_ "SignalLongName" SG_ 355 EPBStatRed "Electric Park Brake Status Redundant";
BA_ "VNSigAllNodes" SG_ 355 EPBStatRed 1;
BA_ "SignalType" SG_ 355 EPBApplStRed "ENM";
BA_ "SignalLongName" SG_ 355 EPBApplStRed "Electric Park Brake Application State Redundant";
BA_ "VNSigAllNodes" SG_ 355 EPBApplStRed 1;
BA_ "SignalType" SG_ 355 BrkFldLvlIndStatRed "ENM";
BA_ "SignalLongName" SG_ 355 BrkFldLvlIndStatRed "Brake Fluid Level Indicator Status Redundant";
BA_ "VNSigAllNodes" SG_ 355 BrkFldLvlIndStatRed 1;
BA_ "SignalType" SG_ 355 BrkFldLvILwFldDtctdRed "BLN";
BA_ "SignalLongName" SG_ 355 BrkFldLvILwFldDtctdRed "Brake Fluid Level Low Fluid Detected Redundant";
BA_ "VNSigAllNodes" SG_ 355 BrkFldLvILwFldDtctdRed 1;
BA_ "SignalType" SG_ 341 StgCmndTgtAng "SNM";
BA_ "SignalLongName" SG_ 341 StgCmndTgtAng "Steering Command Target Angle";
BA_ "VNSigAllNodes" SG_ 341 StgCmndTgtAng 1;
BA_ "SignalType" SG_ 341 StrgCmndMsgStatV "ENM";
BA_ "SignalLongName" SG_ 341 StrgCmndMsgStatV "Steering Command Message Status Validity";
BA_ "VNSigAllNodes" SG_ 341 StrgCmndMsgStatV 1;
BA_ "SignalType" SG_ 341 StrgCmndMsgStat "ENM";
BA_ "SignalLongName" SG_ 341 StrgCmndMsgStat "Steering Command Message Status";
BA_ "VNSigAllNodes" SG_ 341 StrgCmndMsgStat 1;
BA_ "SignalType" SG_ 341 StrgCmndMsgUtlzdV "ENM";
BA_ "SignalLongName" SG_ 341 StrgCmndMsgUtlzdV "Steering Command Message Utilized Validity";
BA_ "VNSigAllNodes" SG_ 341 StrgCmndMsgUtlzdV 1;
BA_ "SignalType" SG_ 341 StrgCmndMsgUtlzd "ENM";
BA_ "SignalLongName" SG_ 341 StrgCmndMsgUtlzd "Steering Command Message Utilized";
BA_ "VNSigAllNodes" SG_ 341 StrgCmndMsgUtlzd 1;
BA_ "SignalType" SG_ 341 AutoStrgCmndStatV "ENM";
BA_ "SignalLongName" SG_ 341 AutoStrgCmndStatV "Autonomous Steering Command Status Validity";
BA_ "VNSigAllNodes" SG_ 341 AutoStrgCmndStatV 1;
BA_ "SignalType" SG_ 341 StgTtlEffTrqDlvd "SNM";
BA_ "SignalLongName" SG_ 341 StgTtlEffTrqDlvd "Steering Total Effective Torque Delivered";
BA_ "VNSigAllNodes" SG_ 341 StgTtlEffTrqDlvd 1;
BA_ "SignalType" SG_ 341 StgTrqSnsrVStat "ENM";
BA_ "SignalLongName" SG_ 341 StgTrqSnsrVStat "Steering Torque Sensor Validity Status";
BA_ "VNSigAllNodes" SG_ 341 StgTrqSnsrVStat 1;
BA_ "SignalType" SG_ 341 StgSysOtptStatV "ENM";
BA_ "SignalLongName" SG_ 341 StgSysOtptStatV "Steering System Output Status Validity";
BA_ "VNSigAllNodes" SG_ 341 StgSysOtptStatV 1;
BA_ "SignalType" SG_ 341 StgSysOtptStat "ENM";
BA_ "SignalLongName" SG_ 341 StgSysOtptStat "Steering System Output Status";
BA_ "VNSigAllNodes" SG_ 341 StgSysOtptStat 1;
BA_ "SignalType" SG_ 341 StgOtptTempLmtgSte "ENM";
BA_ "SignalLongName" SG_ 341 StgOtptTempLmtgSte "Steering Output Temporarily Limiting State";
BA_ "VNSigAllNodes" SG_ 341 StgOtptTempLmtgSte 1;
BA_ "SignalType" SG_ 341 StgAngRtLmtV "ENM";
BA_ "SignalLongName" SG_ 341 StgAngRtLmtV "Steering Angle Rate Limit Validity";
BA_ "VNSigAllNodes" SG_ 341 StgAngRtLmtV 1;
BA_ "SignalType" SG_ 341 StgAngRtLmt "UNM";
BA_ "SignalLongName" SG_ 341 StgAngRtLmt "Steering Angle Rate Limit";
BA_ "VNSigAllNodes" SG_ 341 StgAngRtLmt 1;
BA_ "SignalType" SG_ 341 AutoStrgCmndStat "ENM";
BA_ "SignalLongName" SG_ 341 AutoStrgCmndStat "Autonomous Steering Command Status";
BA_ "VNSigAllNodes" SG_ 341 AutoStrgCmndStat 1;
BA_ "SignalType" SG_ 341 AutoStgStatChksm "UNM";
BA_ "SignalLongName" SG_ 341 AutoStgStatChksm "Autonomous Steering Status Checksum";
BA_ "VNSigAllNodes" SG_ 341 AutoStgStatChksm 1;
BA_ "SignalType" SG_ 341 AutoStgStatARC "UNM";
BA_ "SignalLongName" SG_ 341 AutoStgStatARC "Autonomous Steering Status Alive Rolling Count";
BA_ "VNSigAllNodes" SG_ 341 AutoStgStatARC 1;
BA_ "SignalType" SG_ 341 StgOvrdDetn "ENM";
BA_ "SignalLongName" SG_ 341 StgOvrdDetn "Steering Override Detection";
BA_ "VNSigAllNodes" SG_ 341 StgOvrdDetn 1;
BA_ "SignalType" SG_ 313 LnchCtrlRelLnLockReqd "BLN";
BA_ "SignalLongName" SG_ 313 LnchCtrlRelLnLockReqd "Launch Control Release Line Lock Requested";
BA_ "VNSigAllNodes" SG_ 313 LnchCtrlRelLnLockReqd 1;
BA_ "SignalType" SG_ 313 DrvrDrOpenSwVDA "ENM";
BA_ "SignalLongName" SG_ 313 DrvrDrOpenSwVDA "Driver Door Open Switch Virtual Device Availability";
BA_ "VNSigAllNodes" SG_ 313 DrvrDrOpenSwVDA 1;
BA_ "SignalType" SG_ 313 DrDoorOpenSwActV "ENM";
BA_ "SignalLongName" SG_ 313 DrDoorOpenSwActV "Driver Door Open Switch Active Validity";
BA_ "VNSigAllNodes" SG_ 313 DrDoorOpenSwActV 1;
BA_ "SignalType" SG_ 313 DrDoorOpenSwAct "BLN";
BA_ "SignalLongName" SG_ 313 DrDoorOpenSwAct "Driver Door Open Switch Active";
BA_ "VNSigAllNodes" SG_ 313 DrDoorOpenSwAct 1;
BA_ "SignalType" SG_ 313 LnchCtrlWhlSlpReq "ENM";
BA_ "SignalLongName" SG_ 313 LnchCtrlWhlSlpReq "Launch Control Wheel Slip Request";
BA_ "VNSigAllNodes" SG_ 313 LnchCtrlWhlSlpReq 1;
BA_ "SignalType" SG_ 313 LnchCtrlMdReq "ENM";
BA_ "SignalLongName" SG_ 313 LnchCtrlMdReq "Launch Control Mode Request";
BA_ "VNSigAllNodes" SG_ 313 LnchCtrlMdReq 1;
BA_ "SignalType" SG_ 313 LnchCtrlEngRPMReq "ENM";
BA_ "SignalLongName" SG_ 313 LnchCtrlEngRPMReq "Launch Control Engine RPM Request";
BA_ "VNSigAllNodes" SG_ 313 LnchCtrlEngRPMReq 1;
BA_ "SignalType" SG_ 313 ExtHlStrAssCsStRq "ENM";
BA_ "SignalLongName" SG_ 313 ExtHlStrAssCsStRq "Extended Hill Start Assist Customization Setting Request";
BA_ "VNSigAllNodes" SG_ 313 ExtHlStrAssCsStRq 1;
BA_ "SignalType" SG_ 313 DrvStyPerfMdCsStReq "ENM";
BA_ "SignalLongName" SG_ 313 DrvStyPerfMdCsStReq "Driving Style Performance Mode Customization Setting Request";
BA_ "VNSigAllNodes" SG_ 313 DrvStyPerfMdCsStReq 1;
BA_ "SignalType" SG_ 313 PsngStPerfMdCsStReq "ENM";
BA_ "SignalLongName" SG_ 313 PsngStPerfMdCsStReq "Passenger Seat Performance Mode Customization Setting Request";
BA_ "VNSigAllNodes" SG_ 313 PsngStPerfMdCsStReq 1;
BA_ "SignalType" SG_ 313 DrvrStPerfMdCsStReq "ENM";
BA_ "SignalLongName" SG_ 313 DrvrStPerfMdCsStReq "Driver Seat Performance Mode Customization Setting Request";
BA_ "VNSigAllNodes" SG_ 313 DrvrStPerfMdCsStReq 1;
BA_ "SignalType" SG_ 313 ACCPerfMdCsStReq "ENM";
BA_ "SignalLongName" SG_ 313 ACCPerfMdCsStReq "Adaptive Cruise Control Performance Mode Customization Setting Request";
BA_ "VNSigAllNodes" SG_ 313 ACCPerfMdCsStReq 1;
BA_ "SignalType" SG_ 313 PrkAstAdvSysAct "BLN";
BA_ "SignalLongName" SG_ 313 PrkAstAdvSysAct "Parking Assistance Advanced  System Active";
BA_ "VNSigAllNodes" SG_ 313 PrkAstAdvSysAct 1;
BA_ "SignalType" SG_ 313 SndPerfMdCsStRq "ENM";
BA_ "SignalLongName" SG_ 313 SndPerfMdCsStRq "Sound Performance Mode Customization Setting Request";
BA_ "VNSigAllNodes" SG_ 313 SndPerfMdCsStRq 1;
BA_ "SignalType" SG_ 313 ACCSettingType "ENM";
BA_ "SignalLongName" SG_ 313 ACCSettingType "Adaptive Cruise Control Setting Type";
BA_ "VNSigAllNodes" SG_ 313 ACCSettingType 1;
BA_ "SignalType" SG_ 313 FCABrkPrflReq "BLN";
BA_ "SignalLongName" SG_ 313 FCABrkPrflReq "Forward Collision Alert Brake Prefill Request";
BA_ "VNSigAllNodes" SG_ 313 FCABrkPrflReq 1;
BA_ "SignalType" SG_ 313 ISA2CCC_ScndCdChr "ENM";
BA_ "PacketOrder" SG_ 313 ISA2CCC_ScndCdChr 2;
BA_ "SignalLongName" SG_ 313 ISA2CCC_ScndCdChr "International Standard Alpha 2 Coded Country Code : Second Code Character";
BA_ "VNSigAllNodes" SG_ 313 ISA2CCC_ScndCdChr 1;
BA_ "SignalType" SG_ 313 ISA2CCC_FrstCdChr "ENM";
BA_ "PacketOrder" SG_ 313 ISA2CCC_FrstCdChr 1;
BA_ "SignalLongName" SG_ 313 ISA2CCC_FrstCdChr "International Standard Alpha 2 Coded Country Code : First Code Character";
BA_ "VNSigAllNodes" SG_ 313 ISA2CCC_FrstCdChr 1;
BA_ "SignalType" SG_ 313 DispPerfMdCsStRq "ENM";
BA_ "SignalLongName" SG_ 313 DispPerfMdCsStRq "Display Performance Mode Customization Setting Request";
BA_ "VNSigAllNodes" SG_ 313 DispPerfMdCsStRq 1;
BA_ "SignalType" SG_ 313 FwdClnAlrtCustStngReq "ENM";
BA_ "SignalLongName" SG_ 313 FwdClnAlrtCustStngReq "Forward Collision Alert Customization Setting Request";
BA_ "VNSigAllNodes" SG_ 313 FwdClnAlrtCustStngReq 1;
BA_ "SignalType" SG_ 313 GNCustStngReq "ENM";
BA_ "SignalLongName" SG_ 313 GNCustStngReq "Go Notifier Customization Setting Request";
BA_ "VNSigAllNodes" SG_ 313 GNCustStngReq 1;
BA_ "SignalType" SG_ 1275 BrkSyCtl2EmsRldMlfAct "BLN";
BA_ "SignalLongName" SG_ 1275 BrkSyCtl2EmsRldMlfAct "Brake System Control 2 Emissions Related Malfunction Active";
BA_ "VNSigAllNodes" SG_ 1275 BrkSyCtl2EmsRldMlfAct 1;
BA_ "PacketOrder" SG_ 1275 BSC2ERDTC_CdNum 2;
BA_ "SignalType" SG_ 1275 BSC2ERDTC_CdNum "UNM";
BA_ "SignalLongName" SG_ 1275 BSC2ERDTC_CdNum "Brake System Control 2 Emissions Related DTC : Code Number";
BA_ "VNSigAllNodes" SG_ 1275 BSC2ERDTC_CdNum 1;
BA_ "PacketOrder" SG_ 1275 BSC2ERDTC_SysDes 1;
BA_ "SignalType" SG_ 1275 BSC2ERDTC_SysDes "ENM";
BA_ "SignalLongName" SG_ 1275 BSC2ERDTC_SysDes "Brake System Control 2 Related DTC : System Designator";
BA_ "VNSigAllNodes" SG_ 1275 BSC2ERDTC_SysDes 1;
BA_ "SignalType" SG_ 1275 EBrkAstStat "ENM";
BA_ "SignalLongName" SG_ 1275 EBrkAstStat "EBrakeAssist Status";
BA_ "VNSigAllNodes" SG_ 1275 EBrkAstStat 1;
BA_ "SignalType" SG_ 381 HillDesCtrlRedVehSpIO "BLN";
BA_ "SignalLongName" SG_ 381 HillDesCtrlRedVehSpIO "Hill Descent Control Reduce Vehicle Speed Indication On";
BA_ "VNSigAllNodes" SG_ 381 HillDesCtrlRedVehSpIO 1;
BA_ "SignalType" SG_ 381 EBDFailed "BLN";
BA_ "SignalLongName" SG_ 381 EBDFailed "Electronic Brake Distribution Failed";
BA_ "VNSigAllNodes" SG_ 381 EBDFailed 1;
BA_ "SignalType" SG_ 381 StWhAnVDA "ENM";
BA_ "SignalLongName" SG_ 381 StWhAnVDA "Steering Wheel Angle Virtual Device Availability";
BA_ "GenSigStartValue" SG_ 381 StWhAnVDA 1;
BA_ "VNSigAllNodes" SG_ 381 StWhAnVDA 1;
BA_ "SignalType" SG_ 381 TirePrsLowIO "BLN";
BA_ "SignalLongName" SG_ 381 TirePrsLowIO "Tire Pressure Low Indication On";
BA_ "VNSigAllNodes" SG_ 381 TirePrsLowIO 1;
BA_ "SignalType" SG_ 381 VaccBoostFailure "BLN";
BA_ "SignalLongName" SG_ 381 VaccBoostFailure "Vaccum Boost Failure";
BA_ "VNSigAllNodes" SG_ 381 VaccBoostFailure 1;
BA_ "SignalType" SG_ 381 VSESysPrs "BLN";
BA_ "SignalLongName" SG_ 381 VSESysPrs "Vehicle Stability Enhancement System Present";
BA_ "VNSigAllNodes" SG_ 381 VSESysPrs 1;
BA_ "SignalType" SG_ 381 HalfSysFail "BLN";
BA_ "SignalLongName" SG_ 381 HalfSysFail "Half System Failure";
BA_ "VNSigAllNodes" SG_ 381 HalfSysFail 1;
BA_ "SignalType" SG_ 381 ActVehAccel "SNM";
BA_ "SignalLongName" SG_ 381 ActVehAccel "Actual Vehicle Acceleration";
BA_ "VNSigAllNodes" SG_ 381 ActVehAccel 1;
BA_ "SignalType" SG_ 381 ActVehAccelV "ENM";
BA_ "SignalLongName" SG_ 381 ActVehAccelV "Actual Vehicle Acceleration Validity";
BA_ "VNSigAllNodes" SG_ 381 ActVehAccelV 1;
BA_ "SignalType" SG_ 381 BksOvht "BLN";
BA_ "SignalLongName" SG_ 381 BksOvht "Brakes Overheated";
BA_ "VNSigAllNodes" SG_ 381 BksOvht 1;
BA_ "SignalType" SG_ 381 TCSysPr "BLN";
BA_ "SignalLongName" SG_ 381 TCSysPr "Traction Control System Present";
BA_ "VNSigAllNodes" SG_ 381 TCSysPr 1;
BA_ "SignalType" SG_ 381 ABSPr "BLN";
BA_ "SignalLongName" SG_ 381 ABSPr "Antilock Brake System Present";
BA_ "VNSigAllNodes" SG_ 381 ABSPr 1;
BA_ "SignalType" SG_ 381 TreInfMonSysRstPrfmd "BLN";
BA_ "SignalLongName" SG_ 381 TreInfMonSysRstPrfmd "Tire Inflation Monitoring System Reset Performed";
BA_ "VNSigAllNodes" SG_ 381 TreInfMonSysRstPrfmd 1;
BA_ "SignalType" SG_ 381 ABSIO "BLN";
BA_ "SignalLongName" SG_ 381 ABSIO "Antilock Brake System Indication On";
BA_ "VNSigAllNodes" SG_ 381 ABSIO 1;
BA_ "SignalType" SG_ 381 BrkPadWrnIO "BLN";
BA_ "SignalLongName" SG_ 381 BrkPadWrnIO "Brake Pad Worn Indication On";
BA_ "VNSigAllNodes" SG_ 381 BrkPadWrnIO 1;
BA_ "SignalType" SG_ 381 VehStabEnhmntMd "ENM";
BA_ "SignalLongName" SG_ 381 VehStabEnhmntMd "Vehicle Stability Enhancement Mode";
BA_ "VNSigAllNodes" SG_ 381 VehStabEnhmntMd 1;
BA_ "SignalType" SG_ 381 VehStabEnhmntStat "ENM";
BA_ "SignalLongName" SG_ 381 VehStabEnhmntStat "Vehicle Stability Enhancement Status";
BA_ "VNSigAllNodes" SG_ 381 VehStabEnhmntStat 1;
BA_ "SignalType" SG_ 381 TCSysOpMd "ENM";
BA_ "SignalLongName" SG_ 381 TCSysOpMd "Traction Control System Operating Mode";
BA_ "VNSigAllNodes" SG_ 381 TCSysOpMd 1;
BA_ "SignalType" SG_ 381 TCSysOpStat "ENM";
BA_ "SignalLongName" SG_ 381 TCSysOpStat "Traction Control System Operating Status";
BA_ "VNSigAllNodes" SG_ 381 TCSysOpStat 1;
BA_ "SignalType" SG_ 381 BrkSysVTopSpdLimVal "UNM";
BA_ "SignalLongName" SG_ 381 BrkSysVTopSpdLimVal "Braking System Vehicle Top Speed Limit Value";
BA_ "GenSigStartValue" SG_ 381 BrkSysVTopSpdLimVal 255;
BA_ "VNSigAllNodes" SG_ 381 BrkSysVTopSpdLimVal 1;
BA_ "SignalType" SG_ 381 BrkSysRedBrkTlltlReq "BLN";
BA_ "SignalLongName" SG_ 381 BrkSysRedBrkTlltlReq "Brake System Red Brake Telltale Request";
BA_ "VNSigAllNodes" SG_ 381 BrkSysRedBrkTlltlReq 1;
BA_ "SignalType" SG_ 381 BrkSysBrkLtsReqd "BLN";
BA_ "SignalLongName" SG_ 381 BrkSysBrkLtsReqd "Brake System Brake Lights Requested";
BA_ "VNSigAllNodes" SG_ 381 BrkSysBrkLtsReqd 1;
BA_ "SignalType" SG_ 485 StrAngSnsChksm "UNM";
BA_ "SignalLongName" SG_ 485 StrAngSnsChksm "Steering Angle Sensor Checksum";
BA_ "VNSigAllNodes" SG_ 485 StrAngSnsChksm 1;
BA_ "SignalType" SG_ 485 StrWhAngGrdV "ENM";
BA_ "SignalLongName" SG_ 485 StrWhAngGrdV "Steering Wheel Angle Gradient Validity";
BA_ "VNSigAllNodes" SG_ 485 StrWhAngGrdV 1;
BA_ "SignalType" SG_ 485 StrWhAngGrdMsk "ENM";
BA_ "SignalLongName" SG_ 485 StrWhAngGrdMsk "Steering Wheel Angle Gradient Mask";
BA_ "VNSigAllNodes" SG_ 485 StrWhAngGrdMsk 1;
BA_ "SignalType" SG_ 485 StrWhAngMsk "ENM";
BA_ "SignalLongName" SG_ 485 StrWhAngMsk "Steering Wheel Angle Mask";
BA_ "VNSigAllNodes" SG_ 485 StrWhAngMsk 1;
BA_ "SignalType" SG_ 485 StrWhlAngSenTyp "ENM";
BA_ "SignalLongName" SG_ 485 StrWhlAngSenTyp "Steering Wheel Angle Sensor Type";
BA_ "VNSigAllNodes" SG_ 485 StrWhlAngSenTyp 1;
BA_ "SignalType" SG_ 485 StrWhlAngSenCalStat "ENM";
BA_ "SignalLongName" SG_ 485 StrWhlAngSenCalStat "Steering Wheel Angle Sensor Calibration Status";
BA_ "VNSigAllNodes" SG_ 485 StrWhlAngSenCalStat 1;
BA_ "SignalType" SG_ 485 StrWhAngGrd "SNM";
BA_ "SignalLongName" SG_ 485 StrWhAngGrd "Steering Wheel Angle Gradient";
BA_ "VNSigAllNodes" SG_ 485 StrWhAngGrd 1;
BA_ "SignalType" SG_ 485 StWhlAngAliveRollCnt "UNM";
BA_ "SignalLongName" SG_ 485 StWhlAngAliveRollCnt "Steering Wheel Angle Alive Rolling Count";
BA_ "VNSigAllNodes" SG_ 485 StWhlAngAliveRollCnt 1;
BA_ "SignalType" SG_ 485 StrWhAngV "ENM";
BA_ "SignalLongName" SG_ 485 StrWhAngV "Steering Wheel Angle Validity";
BA_ "VNSigAllNodes" SG_ 485 StrWhAngV 1;
BA_ "SignalType" SG_ 485 StrWhAng "SNM";
BA_ "SignalLongName" SG_ 485 StrWhAng "Steering Wheel Angle";
BA_ "VNSigAllNodes" SG_ 485 StrWhAng 1;
BA_ "SignalType" SG_ 532 RedntVSEActARC "UNM";
BA_ "SignalLongName" SG_ 532 RedntVSEActARC "Redundant Vehicle Stability Enhancement System Active Alive Rolling Count";
BA_ "VNSigAllNodes" SG_ 532 RedntVSEActARC 1;
BA_ "SignalType" SG_ 532 RedntVSEAct "BLN";
BA_ "SignalLongName" SG_ 532 RedntVSEAct "Redundant Vehicle Stability Enhancement System Active";
BA_ "VNSigAllNodes" SG_ 532 RedntVSEAct 1;
BA_ "SignalType" SG_ 532 AutoBrkngActARC "UNM";
BA_ "SignalLongName" SG_ 532 AutoBrkngActARC "Automatic Braking Active Alive Rolling Count";
BA_ "VNSigAllNodes" SG_ 532 AutoBrkngActARC 1;
BA_ "SignalType" SG_ 532 HilRlbkCtrlActIO "BLN";
BA_ "SignalLongName" SG_ 532 HilRlbkCtrlActIO "Hill Rollback Control Active Indiction On";
BA_ "VNSigAllNodes" SG_ 532 HilRlbkCtrlActIO 1;
BA_ "SignalType" SG_ 532 VehHldDrvrDsblActvFlg "BLN";
BA_ "SignalLongName" SG_ 532 VehHldDrvrDsblActvFlg "Vehicle Hold Driver Disable Active Flag";
BA_ "VNSigAllNodes" SG_ 532 VehHldDrvrDsblActvFlg 1;
BA_ "SignalType" SG_ 532 ABSAutnmsBrkReqPVal "UNM";
BA_ "SignalLongName" SG_ 532 ABSAutnmsBrkReqPVal "Antilock Brake System Autonomous Braking Request Protection Value";
BA_ "VNSigAllNodes" SG_ 532 ABSAutnmsBrkReqPVal 1;
BA_ "SignalType" SG_ 532 AutoBrkngAvlbl "BLN";
BA_ "SignalLongName" SG_ 532 AutoBrkngAvlbl "Automatic Braking Available";
BA_ "VNSigAllNodes" SG_ 532 AutoBrkngAvlbl 1;
BA_ "SignalType" SG_ 532 ABSAutnmsBrkReqARC "UNM";
BA_ "SignalLongName" SG_ 532 ABSAutnmsBrkReqARC "Antilock Brake System Autonomous Braking Request Alive Rolling Count";
BA_ "VNSigAllNodes" SG_ 532 ABSAutnmsBrkReqARC 1;
BA_ "SignalType" SG_ 532 ABSAutnmsBrkReq "BLN";
BA_ "SignalLongName" SG_ 532 ABSAutnmsBrkReq "Antilock Brake System Autonomous Braking Request";
BA_ "VNSigAllNodes" SG_ 532 ABSAutnmsBrkReq 1;
BA_ "SignalType" SG_ 532 ABSActvProtPVal "UNM";
BA_ "SignalLongName" SG_ 532 ABSActvProtPVal "Antilock Brake System Active Protected Protection Value";
BA_ "VNSigAllNodes" SG_ 532 ABSActvProtPVal 1;
BA_ "SignalType" SG_ 532 ABSActvProtARC "UNM";
BA_ "SignalLongName" SG_ 532 ABSActvProtARC "Antilock Brake System Active Protected Alive Rolling Count";
BA_ "VNSigAllNodes" SG_ 532 ABSActvProtARC 1;
BA_ "SignalType" SG_ 532 HlStrAssActIO "BLN";
BA_ "SignalLongName" SG_ 532 HlStrAssActIO "Hill Start Assist Active Indication On";
BA_ "VNSigAllNodes" SG_ 532 HlStrAssActIO 1;
BA_ "SignalType" SG_ 532 BrkSysAutBrkFld "BLN";
BA_ "SignalLongName" SG_ 532 BrkSysAutBrkFld "Brake System Automatic Braking Failed";
BA_ "VNSigAllNodes" SG_ 532 BrkSysAutBrkFld 1;
BA_ "SignalType" SG_ 532 IntBrkAssPreFilReq "BLN";
BA_ "SignalLongName" SG_ 532 IntBrkAssPreFilReq "Inteligent Brake Assist Pre-Fil Request";
BA_ "VNSigAllNodes" SG_ 532 IntBrkAssPreFilReq 1;
BA_ "SignalType" SG_ 532 BrkSysMalFuncIndOn "BLN";
BA_ "SignalLongName" SG_ 532 BrkSysMalFuncIndOn "Brake System Malfunction Indication On";
BA_ "VNSigAllNodes" SG_ 532 BrkSysMalFuncIndOn 1;
BA_ "SignalType" SG_ 532 BrkPdDrvAPrsStaPVal "UNM";
BA_ "SignalLongName" SG_ 532 BrkPdDrvAPrsStaPVal "Brake Pedal Driver Applied Pressure Status Protection Value";
BA_ "VNSigAllNodes" SG_ 532 BrkPdDrvAPrsStaPVal 1;
BA_ "SignalType" SG_ 532 BPDAPS_BkPDrvApPV "ENM";
BA_ "PacketOrder" SG_ 532 BPDAPS_BkPDrvApPV 2;
BA_ "SignalLongName" SG_ 532 BPDAPS_BkPDrvApPV "Brake Pedal Driver Applied Pressure Status : Brake Pedal Driver Applied Pressure Validity";
BA_ "VNSigAllNodes" SG_ 532 BPDAPS_BkPDrvApPV 1;
BA_ "SignalType" SG_ 532 BPDAPS_BkPDrvApP "UNM";
BA_ "PacketOrder" SG_ 532 BPDAPS_BkPDrvApP 1;
BA_ "SignalLongName" SG_ 532 BPDAPS_BkPDrvApP "Brake Pedal Driver Applied Pressure Status : Brake Pedal Driver Applied Pressure";
BA_ "VNSigAllNodes" SG_ 532 BPDAPS_BkPDrvApP 1;
BA_ "SignalType" SG_ 532 BrkPdDrvAppPrsAlRC "UNM";
BA_ "SignalLongName" SG_ 532 BrkPdDrvAppPrsAlRC "Brake Pedal Driver Applied Pressure Alive Rolling Count";
BA_ "VNSigAllNodes" SG_ 532 BrkPdDrvAppPrsAlRC 1;
BA_ "SignalType" SG_ 532 BrkFldLvlLwV "ENM";
BA_ "SignalLongName" SG_ 532 BrkFldLvlLwV "Brake Fluid Level Low Validity";
BA_ "VNSigAllNodes" SG_ 532 BrkFldLvlLwV 1;
BA_ "SignalType" SG_ 532 AutoBrkngAct "BLN";
BA_ "SignalLongName" SG_ 532 AutoBrkngAct "Automatic Braking Active";
BA_ "VNSigAllNodes" SG_ 532 AutoBrkngAct 1;
BA_ "SignalType" SG_ 532 BrkFldLvlLw "BLN";
BA_ "SignalLongName" SG_ 532 BrkFldLvlLw "Brake Fluid Level Low";
BA_ "VNSigAllNodes" SG_ 532 BrkFldLvlLw 1;
BA_ "SignalType" SG_ 532 ABSActvProt "BLN";
BA_ "SignalLongName" SG_ 532 ABSActvProt "Antilock Brake System Active Protected";
BA_ "VNSigAllNodes" SG_ 532 ABSActvProt 1;
BA_ "SignalType" SG_ 489 EnhDrvMdSwChUseRq "BLN";
BA_ "SignalLongName" SG_ 489 EnhDrvMdSwChUseRq "Enhanced Driver Selected Mode Switch Chassis Use Requested";
BA_ "VNSigAllNodes" SG_ 489 EnhDrvMdSwChUseRq 1;
BA_ "SignalType" SG_ 489 IMUDataMsk "BLN";
BA_ "SignalLongName" SG_ 489 IMUDataMsk "Inertial Measurement Unit Data Mask";
BA_ "VNSigAllNodes" SG_ 489 IMUDataMsk 1;
BA_ "SignalType" SG_ 489 DrvIndpntBrkAppAct "BLN";
BA_ "SignalLongName" SG_ 489 DrvIndpntBrkAppAct "Driver Independent Brake Apply Active";
BA_ "VNSigAllNodes" SG_ 489 DrvIndpntBrkAppAct 1;
BA_ "SignalType" SG_ 489 WhlSlpSt "ENM";
BA_ "SignalLongName" SG_ 489 WhlSlpSt "Wheel Slip Status";
BA_ "VNSigAllNodes" SG_ 489 WhlSlpSt 1;
BA_ "SignalType" SG_ 489 BSTGRReqdGear "ENM";
BA_ "PacketOrder" SG_ 489 BSTGRReqdGear 2;
BA_ "SignalLongName" SG_ 489 BSTGRReqdGear "Brake System Transmission Gear Request : Requested Gear";
BA_ "VNSigAllNodes" SG_ 489 BSTGRReqdGear 1;
BA_ "SignalType" SG_ 489 BSTGRReqType "ENM";
BA_ "PacketOrder" SG_ 489 BSTGRReqType 1;
BA_ "SignalLongName" SG_ 489 BSTGRReqType "Brake System Transmission Gear Request : Request Type";
BA_ "VNSigAllNodes" SG_ 489 BSTGRReqType 1;
BA_ "SignalType" SG_ 489 VehDynOvrUndrStr "SNM";
BA_ "SignalLongName" SG_ 489 VehDynOvrUndrStr "Vehicle Dynamics Over Under Steer";
BA_ "VNSigAllNodes" SG_ 489 VehDynOvrUndrStr 1;
BA_ "SignalType" SG_ 489 VSELatAccV "ENM";
BA_ "SignalLongName" SG_ 489 VSELatAccV "Vehicle Stability Enhancement Lateral Acceleration Validity";
BA_ "VNSigAllNodes" SG_ 489 VSELatAccV 1;
BA_ "SignalType" SG_ 489 VSELatAcc "SNM";
BA_ "SignalLongName" SG_ 489 VSELatAcc "Vehicle Stability Enhancement Lateral Acceleration";
BA_ "VNSigAllNodes" SG_ 489 VSELatAcc 1;
BA_ "SignalType" SG_ 489 VSEAct "BLN";
BA_ "SignalLongName" SG_ 489 VSEAct "Vehicle Stability Enhancement System Active";
BA_ "VNSigAllNodes" SG_ 489 VSEAct 1;
BA_ "SignalType" SG_ 489 VhDynCntlSysSt "ENM";
BA_ "SignalLongName" SG_ 489 VhDynCntlSysSt "Vehicle Dynamics Control System Status";
BA_ "VNSigAllNodes" SG_ 489 VhDynCntlSysSt 1;
BA_ "SignalType" SG_ 489 VehDynYawRateV "ENM";
BA_ "SignalLongName" SG_ 489 VehDynYawRateV "Vehicle Dynamics Yaw Rate Validity";
BA_ "VNSigAllNodes" SG_ 489 VehDynYawRateV 1;
BA_ "SignalType" SG_ 489 VehDynYawRate "SNM";
BA_ "SignalLongName" SG_ 489 VehDynYawRate "Vehicle Dynamics Yaw Rate";
BA_ "VNSigAllNodes" SG_ 489 VehDynYawRate 1;
BA_ "SignalType" SG_ 489 TrnsBrkSysCltchRelRqd "BLN";
BA_ "SignalLongName" SG_ 489 TrnsBrkSysCltchRelRqd "Transmission Brake System Clutch Release Requested";
BA_ "VNSigAllNodes" SG_ 489 TrnsBrkSysCltchRelRqd 1;
BA_ "SignalType" SG_ 489 TracCntrlSysDrIntnt "ENM";
BA_ "SignalLongName" SG_ 489 TracCntrlSysDrIntnt "Traction Control System Driver Intent";
BA_ "VNSigAllNodes" SG_ 489 TracCntrlSysDrIntnt 1;
BA_ "SignalType" SG_ 489 VehDynOvrUndrStrV "ENM";
BA_ "SignalLongName" SG_ 489 VehDynOvrUndrStrV "Vehicle Dynamics Over Under Steer Validity";
BA_ "VNSigAllNodes" SG_ 489 VehDynOvrUndrStrV 1;
BA_ "SignalType" SG_ 489 TCSysEnbld "BLN";
BA_ "SignalLongName" SG_ 489 TCSysEnbld "Traction Control System Enabled";
BA_ "VNSigAllNodes" SG_ 489 TCSysEnbld 1;
BA_ "SignalType" SG_ 489 TCSysAtv "BLN";
BA_ "SignalLongName" SG_ 489 TCSysAtv "Traction Control System Active";
BA_ "VNSigAllNodes" SG_ 489 TCSysAtv 1;
BA_ "SignalType" SG_ 489 BrkPdlDrvAppPrsDetcdV "ENM";
BA_ "SignalLongName" SG_ 489 BrkPdlDrvAppPrsDetcdV "Brake Pedal Driver Applied Pressure Detected Validity";
BA_ "VNSigAllNodes" SG_ 489 BrkPdlDrvAppPrsDetcdV 1;
BA_ "SignalType" SG_ 489 BrkPdlDrvAppPrsDetcd "BLN";
BA_ "SignalLongName" SG_ 489 BrkPdlDrvAppPrsDetcd "Brake Pedal Driver Applied Pressure Detected";
BA_ "GenSigStartValue" SG_ 489 BrkPdlDrvAppPrsDetcd 1;
BA_ "VNSigAllNodes" SG_ 489 BrkPdlDrvAppPrsDetcd 1;
BA_ "SignalType" SG_ 489 ACCBrkngAct "BLN";
BA_ "SignalLongName" SG_ 489 ACCBrkngAct "Adaptive Cruise Control Braking Active";
BA_ "VNSigAllNodes" SG_ 489 ACCBrkngAct 1;
BA_ "SignalType" SG_ 489 ABSFld "BLN";
BA_ "SignalLongName" SG_ 489 ABSFld "Antilock Brake System Failed";
BA_ "VNSigAllNodes" SG_ 489 ABSFld 1;
BA_ "SignalType" SG_ 489 ABSAtv "BLN";
BA_ "SignalLongName" SG_ 489 ABSAtv "Antilock Brake System Active";
BA_ "VNSigAllNodes" SG_ 489 ABSAtv 1;
BA_ "SignalType" SG_ 305 PriAutoArbBrkTrqReqRed "UNM";
BA_ "SignalLongName" SG_ 305 PriAutoArbBrkTrqReqRed "Primary Autonomous Arbitrated Brake Torque Request Redundant";
BA_ "GenSigStartValue" SG_ 305 PriAutoArbBrkTrqReqRed 32767;
BA_ "VNSigAllNodes" SG_ 305 PriAutoArbBrkTrqReqRed 1;
BA_ "SignalType" SG_ 305 PriBrkModStatRed "ENM";
BA_ "SignalLongName" SG_ 305 PriBrkModStatRed "Primary Brake Module Status Redundant";
BA_ "VNSigAllNodes" SG_ 305 PriBrkModStatRed 1;
BA_ "SignalType" SG_ 305 PriAutoEstBrkTrqAppStatRed "ENM";
BA_ "SignalLongName" SG_ 305 PriAutoEstBrkTrqAppStatRed "Primary Autonomous Estimated Brake Torque Applied Status Redundant";
BA_ "VNSigAllNodes" SG_ 305 PriAutoEstBrkTrqAppStatRed 1;
BA_ "SignalType" SG_ 305 PriAutoEstBrkTrqApdRed "UNM";
BA_ "SignalLongName" SG_ 305 PriAutoEstBrkTrqApdRed "Primary Autonomous Estimated Brake Torque Applied Redundant";
BA_ "GenSigStartValue" SG_ 305 PriAutoEstBrkTrqApdRed 32767;
BA_ "VNSigAllNodes" SG_ 305 PriAutoEstBrkTrqApdRed 1;
BA_ "SignalType" SG_ 305 PriAutoBrkSysDrInfcStatRed "ENM";
BA_ "SignalLongName" SG_ 305 PriAutoBrkSysDrInfcStatRed "Primary Autonomous Brake System Driver Interference Detected Status Redundant";
BA_ "VNSigAllNodes" SG_ 305 PriAutoBrkSysDrInfcStatRed 1;
BA_ "SignalType" SG_ 305 PriAutoAxlTrqReqStatRedChksm "UNM";
BA_ "SignalLongName" SG_ 305 PriAutoAxlTrqReqStatRedChksm "Primary Autonomous Axle Torque Request Status Redundant Checksum";
BA_ "VNSigAllNodes" SG_ 305 PriAutoAxlTrqReqStatRedChksm 1;
BA_ "SignalType" SG_ 305 MstCylPrsCrct1Stat "ENM";
BA_ "SignalLongName" SG_ 305 MstCylPrsCrct1Stat "Master Cylinder Pressure Circuit 1 Status";
BA_ "VNSigAllNodes" SG_ 305 MstCylPrsCrct1Stat 1;
BA_ "SignalType" SG_ 305 MstCylPrsCrct1 "UNM";
BA_ "SignalLongName" SG_ 305 MstCylPrsCrct1 "Master Cylinder Pressure Circuit 1";
BA_ "VNSigAllNodes" SG_ 305 MstCylPrsCrct1 1;
BA_ "SignalType" SG_ 305 PriAutoAxlTrqReqStatRedARC "UNM";
BA_ "SignalLongName" SG_ 305 PriAutoAxlTrqReqStatRedARC "Primary Autonomous Axle Torque Request Status Redundant Alive Rolling Count";
BA_ "VNSigAllNodes" SG_ 305 PriAutoAxlTrqReqStatRedARC 1;
BA_ "SignalType" SG_ 305 PriSuffBrkTrqStdstlRed "BLN";
BA_ "SignalLongName" SG_ 305 PriSuffBrkTrqStdstlRed "Primary Sufficient Brake Torque for Standstill Redundant";
BA_ "VNSigAllNodes" SG_ 305 PriSuffBrkTrqStdstlRed 1;
BA_ "SignalType" SG_ 1020 OtsAirTmpEmsnsRelV "ENM";
BA_ "SignalLongName" SG_ 1020 OtsAirTmpEmsnsRelV "Outside Air Temperature Emissions Related Validity";
BA_ "VNSigAllNodes" SG_ 1020 OtsAirTmpEmsnsRelV 1;
BA_ "SignalType" SG_ 1020 OtsAirTmpEmsnsRel "UNM";
BA_ "SignalLongName" SG_ 1020 OtsAirTmpEmsnsRel "Outside Air Temperature Emissions Related";
BA_ "VNSigAllNodes" SG_ 1020 OtsAirTmpEmsnsRel 1;
BA_ "SignalType" SG_ 1020 OATEmsnsRelCrValV "ENM";
BA_ "SignalLongName" SG_ 1020 OATEmsnsRelCrValV "Outside Air Temperature Emissions Related Corrected Value Validity";
BA_ "VNSigAllNodes" SG_ 1020 OATEmsnsRelCrValV 1;
BA_ "SignalType" SG_ 1020 OATEmsnsRelCrValM "ENM";
BA_ "SignalLongName" SG_ 1020 OATEmsnsRelCrValM "Outside Air Temperature Emissions Related Corrected Value Mask";
BA_ "VNSigAllNodes" SG_ 1020 OATEmsnsRelCrValM 1;
BA_ "SignalType" SG_ 1020 OATEmsnsRelCrVal "UNM";
BA_ "SignalLongName" SG_ 1020 OATEmsnsRelCrVal "Outside Air Temperature Emissions Related Corrected Value";
BA_ "VNSigAllNodes" SG_ 1020 OATEmsnsRelCrVal 1;
BA_ "SignalType" SG_ 1020 CatlystOutGasTempEstV "ENM";
BA_ "SignalLongName" SG_ 1020 CatlystOutGasTempEstV "Catalyst Outlet Gas Temperature Estimate Validity";
BA_ "VNSigAllNodes" SG_ 1020 CatlystOutGasTempEstV 1;
BA_ "SignalType" SG_ 1020 CatlystOutGasTempEst "UNM";
BA_ "SignalLongName" SG_ 1020 CatlystOutGasTempEst "Catalyst Outlet Gas Temperature Estimate";
BA_ "VNSigAllNodes" SG_ 1020 CatlystOutGasTempEst 1;
BA_ "SignalType" SG_ 1020 OtsAirTmpCrValMsk "ENM";
BA_ "SignalLongName" SG_ 1020 OtsAirTmpCrValMsk "Outside Air Temperature Corrected Value Mask";
BA_ "VNSigAllNodes" SG_ 1020 OtsAirTmpCrValMsk 1;
BA_ "SignalType" SG_ 1020 OtsAirTmpV "ENM";
BA_ "SignalLongName" SG_ 1020 OtsAirTmpV "Outside Air Temperature Validity";
BA_ "VNSigAllNodes" SG_ 1020 OtsAirTmpV 1;
BA_ "SignalType" SG_ 1020 OtsAirTmpCrValV "ENM";
BA_ "SignalLongName" SG_ 1020 OtsAirTmpCrValV "Outside Air Temperature Corrected Value Validity";
BA_ "VNSigAllNodes" SG_ 1020 OtsAirTmpCrValV 1;
BA_ "SignalType" SG_ 1020 OtsAirTmpCrVal "UNM";
BA_ "SignalLongName" SG_ 1020 OtsAirTmpCrVal "Outside Air Temperature Corrected Value";
BA_ "VNSigAllNodes" SG_ 1020 OtsAirTmpCrVal 1;
BA_ "SignalType" SG_ 1020 OtsAirTmp "UNM";
BA_ "SignalLongName" SG_ 1020 OtsAirTmp "Outside Air Temperature";
BA_ "VNSigAllNodes" SG_ 1020 OtsAirTmp 1;
BA_ "SignalType" SG_ 1020 EngInltSpcfcHmdtyV "ENM";
BA_ "SignalLongName" SG_ 1020 EngInltSpcfcHmdtyV "Engine Inlet Specific Humidity Validity";
BA_ "VNSigAllNodes" SG_ 1020 EngInltSpcfcHmdtyV 1;
BA_ "SignalType" SG_ 1020 EngInltSpcfcHmdtyM "ENM";
BA_ "SignalLongName" SG_ 1020 EngInltSpcfcHmdtyM "Engine Inlet Specific Humidity Mask";
BA_ "VNSigAllNodes" SG_ 1020 EngInltSpcfcHmdtyM 1;
BA_ "SignalType" SG_ 1020 EngInltSpcfcHmdty "UNM";
BA_ "SignalLongName" SG_ 1020 EngInltSpcfcHmdty "Engine Inlet Specific Humidity";
BA_ "VNSigAllNodes" SG_ 1020 EngInltSpcfcHmdty 1;
BA_ "SignalType" SG_ 338 CoPRVBAtv "BLN";
BA_ "SignalLongName" SG_ 338 CoPRVBAtv "CoPilot Rear Virtual Bumper Active";
BA_ "VNSigAllNodes" SG_ 338 CoPRVBAtv 1;
BA_ "SignalType" SG_ 338 CoPCIBAtv "BLN";
BA_ "SignalLongName" SG_ 338 CoPCIBAtv "CoPilot Collision Imminent Braking Active";
BA_ "VNSigAllNodes" SG_ 338 CoPCIBAtv 1;
BA_ "SignalType" SG_ 338 CPEPSWAR_TrgtAng "SNM";
BA_ "SignalLongName" SG_ 338 CPEPSWAR_TrgtAng "CoPilot Electric Power Steering Wheel Angle Request: Target Angle";
BA_ "VNSigAllNodes" SG_ 338 CPEPSWAR_TrgtAng 1;
BA_ "SignalType" SG_ 338 CPEPSWAR_ReqdState "ENM";
BA_ "SignalLongName" SG_ 338 CPEPSWAR_ReqdState "CoPilot Electric Power Steering Wheel Angle Request: Requested State";
BA_ "VNSigAllNodes" SG_ 338 CPEPSWAR_ReqdState 1;
BA_ "SignalType" SG_ 338 CoPEPBReq "ENM";
BA_ "SignalLongName" SG_ 338 CoPEPBReq "CoPilot Electric Park Brake Request";
BA_ "VNSigAllNodes" SG_ 338 CoPEPBReq 1;
BA_ "SignalType" SG_ 338 CoPBaSChksm "UNM";
BA_ "SignalLongName" SG_ 338 CoPBaSChksm "CoPilot Brake and Steering Checksum";
BA_ "VNSigAllNodes" SG_ 338 CoPBaSChksm 1;
BA_ "SignalType" SG_ 338 CoPBaSARC "UNM";
BA_ "SignalLongName" SG_ 338 CoPBaSARC "CoPilot Brake and Steering Alive Rolling Count";
BA_ "VNSigAllNodes" SG_ 338 CoPBaSARC 1;
BA_ "SignalType" SG_ 338 CoPCntrlFail "BLN";
BA_ "SignalLongName" SG_ 338 CoPCntrlFail "CoPilot Controller Failure";
BA_ "VNSigAllNodes" SG_ 338 CoPCntrlFail 1;
BA_ "SignalType" SG_ 338 CoPAutoBrkTrqReq "UNM";
BA_ "SignalLongName" SG_ 338 CoPAutoBrkTrqReq "CoPilot Autonomous Brake Torque Request";
BA_ "GenSigStartValue" SG_ 338 CoPAutoBrkTrqReq 32767;
BA_ "VNSigAllNodes" SG_ 338 CoPAutoBrkTrqReq 1;
BA_ "SignalType" SG_ 338 CoPAutoBrkReqType "ENM";
BA_ "SignalLongName" SG_ 338 CoPAutoBrkReqType "CoPilot Autonomous Brake Request Type";
BA_ "VNSigAllNodes" SG_ 338 CoPAutoBrkReqType 1;
BA_ "SignalType" SG_ 835 TmSyncMstrTmClkV "ENM";
BA_ "SignalLongName" SG_ 835 TmSyncMstrTmClkV "Time Sync Master Time Clock Validity";
BA_ "VNSigAllNodes" SG_ 835 TmSyncMstrTmClkV 1;
BA_ "SignalType" SG_ 835 TmSyncMstrTmClk "UNM";
BA_ "SignalLongName" SG_ 835 TmSyncMstrTmClk "Time Sync Master Time Clock";
BA_ "VNSigAllNodes" SG_ 835 TmSyncMstrTmClk 1;
BA_ "SignalType" SG_ 835 RTXCorrctnEnbl "ENM";
BA_ "SignalLongName" SG_ 835 RTXCorrctnEnbl "RTX Corrections Enable";
BA_ "VNSigAllNodes" SG_ 835 RTXCorrctnEnbl 1;
BA_ "SignalType" SG_ 835 TmSyncMstrTmClkARC "UNM";
BA_ "SignalLongName" SG_ 835 TmSyncMstrTmClkARC "Time Sync Master Time Clock Alive Rolling Count";
BA_ "VNSigAllNodes" SG_ 835 TmSyncMstrTmClkARC 1;
BA_ "SignalType" SG_ 835 TmSyncMstrTmClkChksm "UNM";
BA_ "SignalLongName" SG_ 835 TmSyncMstrTmClkChksm "Time Sync Master Time Clock Checksum";
BA_ "VNSigAllNodes" SG_ 835 TmSyncMstrTmClkChksm 1;
BA_ "SignalType" SG_ 753 EBCMDS5_DTCStatus "ENM";
BA_ "PacketOrder" SG_ 753 EBCMDS5_DTCStatus 2;
BA_ "SignalLongName" SG_ 753 EBCMDS5_DTCStatus "Electronic Brake Control Module Diagnostic Status 5 : Diagnostic Trouble Code Status";
BA_ "VNSigAllNodes" SG_ 753 EBCMDS5_DTCStatus 1;
BA_ "SignalType" SG_ 753 EBCMDS5_DTCIndex "UNM";
BA_ "PacketOrder" SG_ 753 EBCMDS5_DTCIndex 1;
BA_ "SignalLongName" SG_ 753 EBCMDS5_DTCIndex "Electronic Brake Control Module Diagnostic Status 5 : Diagnostic Trouble Code Index";
BA_ "VNSigAllNodes" SG_ 753 EBCMDS5_DTCIndex 1;
BA_ "SignalType" SG_ 753 EBCMDS4_DTCStatus "ENM";
BA_ "PacketOrder" SG_ 753 EBCMDS4_DTCStatus 2;
BA_ "SignalLongName" SG_ 753 EBCMDS4_DTCStatus "Electronic Brake Control Module Diagnostic Status 4 : Diagnostic Trouble Code Status";
BA_ "VNSigAllNodes" SG_ 753 EBCMDS4_DTCStatus 1;
BA_ "SignalType" SG_ 753 EBCMDS4_DTCIndex "UNM";
BA_ "PacketOrder" SG_ 753 EBCMDS4_DTCIndex 1;
BA_ "SignalLongName" SG_ 753 EBCMDS4_DTCIndex "Electronic Brake Control Module Diagnostic Status 4 : Diagnostic Trouble Code Index";
BA_ "VNSigAllNodes" SG_ 753 EBCMDS4_DTCIndex 1;
BA_ "SignalType" SG_ 753 EBCMDS3_DTCStatus "ENM";
BA_ "PacketOrder" SG_ 753 EBCMDS3_DTCStatus 2;
BA_ "SignalLongName" SG_ 753 EBCMDS3_DTCStatus "Electronic Brake Control Module Diagnostic Status 3 : Diagnostic Trouble Code Status";
BA_ "VNSigAllNodes" SG_ 753 EBCMDS3_DTCStatus 1;
BA_ "SignalType" SG_ 753 EBCMDS3_DTCIndex "UNM";
BA_ "PacketOrder" SG_ 753 EBCMDS3_DTCIndex 1;
BA_ "SignalLongName" SG_ 753 EBCMDS3_DTCIndex "Electronic Brake Control Module Diagnostic Status 3 : Diagnostic Trouble Code Index";
BA_ "VNSigAllNodes" SG_ 753 EBCMDS3_DTCIndex 1;
BA_ "SignalType" SG_ 753 EBCMDS2_DTCStatus "ENM";
BA_ "PacketOrder" SG_ 753 EBCMDS2_DTCStatus 2;
BA_ "SignalLongName" SG_ 753 EBCMDS2_DTCStatus "Electronic Brake Control Module Diagnostic Status 2 : Diagnostic Trouble Code Status";
BA_ "VNSigAllNodes" SG_ 753 EBCMDS2_DTCStatus 1;
BA_ "SignalType" SG_ 753 EBCMDS2_DTCIndex "UNM";
BA_ "PacketOrder" SG_ 753 EBCMDS2_DTCIndex 1;
BA_ "SignalLongName" SG_ 753 EBCMDS2_DTCIndex "Electronic Brake Control Module Diagnostic Status 2 : Diagnostic Trouble Code Index";
BA_ "VNSigAllNodes" SG_ 753 EBCMDS2_DTCIndex 1;
BA_ "SignalType" SG_ 753 EBCMDS1_DTCStatus "ENM";
BA_ "PacketOrder" SG_ 753 EBCMDS1_DTCStatus 2;
BA_ "SignalLongName" SG_ 753 EBCMDS1_DTCStatus "Electronic Brake Control Module Diagnostic Status 1 : Diagnostic Trouble Code Status";
BA_ "VNSigAllNodes" SG_ 753 EBCMDS1_DTCStatus 1;
BA_ "SignalType" SG_ 753 EBCMDS1_DTCIndex "UNM";
BA_ "PacketOrder" SG_ 753 EBCMDS1_DTCIndex 1;
BA_ "SignalLongName" SG_ 753 EBCMDS1_DTCIndex "Electronic Brake Control Module Diagnostic Status 1 : Diagnostic Trouble Code Index";
BA_ "VNSigAllNodes" SG_ 753 EBCMDS1_DTCIndex 1;
BA_ "SignalType" SG_ 869 TnDrvGapAdjUnbIO "BLN";
BA_ "SignalLongName" SG_ 869 TnDrvGapAdjUnbIO "Teen Driver Gap Adjust Unavailable Indication On";
BA_ "VNSigAllNodes" SG_ 869 TnDrvGapAdjUnbIO 1;
BA_ "PacketOrder" SG_ 869 CPSCA_Resrv3Avail 7;
BA_ "SignalType" SG_ 869 CPSCA_Resrv3Avail "BLN";
BA_ "SignalLongName" SG_ 869 CPSCA_Resrv3Avail "Collision Preparation System Customization Available : Reserved3 Available";
BA_ "VNSigAllNodes" SG_ 869 CPSCA_Resrv3Avail 1;
BA_ "PacketOrder" SG_ 869 CPSCA_Resrv2Avail 6;
BA_ "SignalType" SG_ 869 CPSCA_Resrv2Avail "BLN";
BA_ "SignalLongName" SG_ 869 CPSCA_Resrv2Avail "Collision Preparation System Customization Available : Reserved2 Available";
BA_ "VNSigAllNodes" SG_ 869 CPSCA_Resrv2Avail 1;
BA_ "PacketOrder" SG_ 869 CPSCA_Resrv1Avail 5;
BA_ "SignalType" SG_ 869 CPSCA_Resrv1Avail "BLN";
BA_ "SignalLongName" SG_ 869 CPSCA_Resrv1Avail "Collision Preparation System Customization Available : Reserved1 Available";
BA_ "VNSigAllNodes" SG_ 869 CPSCA_Resrv1Avail 1;
BA_ "PacketOrder" SG_ 869 CPSCA_AlrtBrkStrAvail 4;
BA_ "SignalType" SG_ 869 CPSCA_AlrtBrkStrAvail "BLN";
BA_ "SignalLongName" SG_ 869 CPSCA_AlrtBrkStrAvail "Collision Preparation System Customization Available : Alert and Brake and Steer Available";
BA_ "VNSigAllNodes" SG_ 869 CPSCA_AlrtBrkStrAvail 1;
BA_ "PacketOrder" SG_ 869 CPSCA_AlrtBrkAvail 3;
BA_ "GenSigStartValue" SG_ 869 CPSCA_AlrtBrkAvail 1;
BA_ "SignalType" SG_ 869 CPSCA_AlrtBrkAvail "BLN";
BA_ "SignalLongName" SG_ 869 CPSCA_AlrtBrkAvail "Collision Preparation System Customization Available : Alert and Brake Available";
BA_ "VNSigAllNodes" SG_ 869 CPSCA_AlrtBrkAvail 1;
BA_ "PacketOrder" SG_ 869 CPSCA_AlrtAvail 2;
BA_ "GenSigStartValue" SG_ 869 CPSCA_AlrtAvail 1;
BA_ "SignalType" SG_ 869 CPSCA_AlrtAvail "BLN";
BA_ "SignalLongName" SG_ 869 CPSCA_AlrtAvail "Collision Preparation System Customization Available : Alert Available";
BA_ "VNSigAllNodes" SG_ 869 CPSCA_AlrtAvail 1;
BA_ "PacketOrder" SG_ 869 CPSCA_OffAvail 1;
BA_ "GenSigStartValue" SG_ 869 CPSCA_OffAvail 1;
BA_ "SignalType" SG_ 869 CPSCA_OffAvail "BLN";
BA_ "SignalLongName" SG_ 869 CPSCA_OffAvail "Collision Preparation System Customization Available : Off Available";
BA_ "VNSigAllNodes" SG_ 869 CPSCA_OffAvail 1;
BA_ "SignalType" SG_ 869 FwdClnMtgnBrkReqAct "BLN";
BA_ "SignalLongName" SG_ 869 FwdClnMtgnBrkReqAct "Forward Collision Mitigation Braking Request Active";
BA_ "VNSigAllNodes" SG_ 869 FwdClnMtgnBrkReqAct 1;
BA_ "SignalType" SG_ 869 FCACustStngAvlbl "BLN";
BA_ "SignalLongName" SG_ 869 FCACustStngAvlbl "Forward Collision Alert Customization Setting Available";
BA_ "VNSigAllNodes" SG_ 869 FCACustStngAvlbl 1;
BA_ "SignalType" SG_ 869 FwdClnAlrtCustCrntSetngVal "ENM";
BA_ "SignalLongName" SG_ 869 FwdClnAlrtCustCrntSetngVal "Forward Collision Alert Customization Current Setting Value";
BA_ "VNSigAllNodes" SG_ 869 FwdClnAlrtCustCrntSetngVal 1;
BA_ "SignalType" SG_ 869 GNCustSetngAvlbl "BLN";
BA_ "SignalLongName" SG_ 869 GNCustSetngAvlbl "Go Notifier Customization Setting Available";
BA_ "VNSigAllNodes" SG_ 869 GNCustSetngAvlbl 1;
BA_ "SignalType" SG_ 869 CPSUnblIO "BLN";
BA_ "SignalLongName" SG_ 869 CPSUnblIO "Collision Preparation System Unavailable Indication On";
BA_ "VNSigAllNodes" SG_ 869 CPSUnblIO 1;
BA_ "SignalType" SG_ 869 ColPrSysStngAvl "BLN";
BA_ "SignalLongName" SG_ 869 ColPrSysStngAvl "Collision Preparation System Setting Available";
BA_ "VNSigAllNodes" SG_ 869 ColPrSysStngAvl 1;
BA_ "SignalType" SG_ 869 CPSOffIO "BLN";
BA_ "SignalLongName" SG_ 869 CPSOffIO "Collision Preparation System Off Indication On";
BA_ "VNSigAllNodes" SG_ 869 CPSOffIO 1;
BA_ "SignalType" SG_ 869 CPSFldIO "BLN";
BA_ "SignalLongName" SG_ 869 CPSFldIO "Collision Preparation System Failed Indication On";
BA_ "VNSigAllNodes" SG_ 869 CPSFldIO 1;
BA_ "SignalType" SG_ 869 ColPrSysCrntStng "ENM";
BA_ "SignalLongName" SG_ 869 ColPrSysCrntStng "Collision Preparation System Current Setting Value";
BA_ "VNSigAllNodes" SG_ 869 ColPrSysCrntStng 1;
BA_ "SignalType" SG_ 869 CPSAlrtOnlIO "BLN";
BA_ "SignalLongName" SG_ 869 CPSAlrtOnlIO "Collision Preparation System Alert Only Indication On";
BA_ "VNSigAllNodes" SG_ 869 CPSAlrtOnlIO 1;
BA_ "SignalType" SG_ 869 GNCustCrntStngVal "ENM";
BA_ "SignalLongName" SG_ 869 GNCustCrntStngVal "Go Notifier Customization Current Setting Value";
BA_ "VNSigAllNodes" SG_ 869 GNCustCrntStngVal 1;
BA_ "SignalType" SG_ 869 CoPilotWndShldWashReqAct "BLN";
BA_ "SignalLongName" SG_ 869 CoPilotWndShldWashReqAct "Safety Co-Pilot windshield Wash Request Active";
BA_ "VNSigAllNodes" SG_ 869 CoPilotWndShldWashReqAct 1;
BA_ "SignalType" SG_ 1217 LDMinEngCltTmpRchd "BLN";
BA_ "SignalLongName" SG_ 1217 LDMinEngCltTmpRchd "Legislated Diagnostics Minimum Engine Coolant Temperature Reached";
BA_ "VNSigAllNodes" SG_ 1217 LDMinEngCltTmpRchd 1;
BA_ "SignalType" SG_ 1217 LegPstDTCClrDrvCyCm "BLN";
BA_ "SignalLongName" SG_ 1217 LegPstDTCClrDrvCyCm "Legislated Post DTC Clear Drive Cycle Complete";
BA_ "VNSigAllNodes" SG_ 1217 LegPstDTCClrDrvCyCm 1;
BA_ "SignalType" SG_ 1217 LegDiagColdStCndMet "BLN";
BA_ "SignalLongName" SG_ 1217 LegDiagColdStCndMet "Legislated Diagnostics Cold Start Conditions Met";
BA_ "VNSigAllNodes" SG_ 1217 LegDiagColdStCndMet 1;
BA_ "SignalType" SG_ 1217 LegDiagColdStCndFltPr "BLN";
BA_ "SignalLongName" SG_ 1217 LegDiagColdStCndFltPr "Legislated Diagnostics Cold Start Conditions Fault Present";
BA_ "VNSigAllNodes" SG_ 1217 LegDiagColdStCndFltPr 1;
BA_ "SignalType" SG_ 1217 EngEconMdCmnd "BLN";
BA_ "SignalLongName" SG_ 1217 EngEconMdCmnd "Engine Economy Mode Commanded";
BA_ "VNSigAllNodes" SG_ 1217 EngEconMdCmnd 1;
BA_ "SignalType" SG_ 1217 DslExhFldRmngDstHRsV "ENM";
BA_ "SignalLongName" SG_ 1217 DslExhFldRmngDstHRsV "Diesel Exhaust Fluid Remaining Distance High Resolution Validity";
BA_ "VNSigAllNodes" SG_ 1217 DslExhFldRmngDstHRsV 1;
BA_ "SignalType" SG_ 1217 DslExhFldRmngDstHRs "UNM";
BA_ "SignalLongName" SG_ 1217 DslExhFldRmngDstHRs "Diesel Exhaust Fluid Remaining Distance High Resolution";
BA_ "VNSigAllNodes" SG_ 1217 DslExhFldRmngDstHRs 1;
BA_ "SignalType" SG_ 1217 EngOilHotIO "BLN";
BA_ "SignalLongName" SG_ 1217 EngOilHotIO "Engine Oil Hot Indication On";
BA_ "VNSigAllNodes" SG_ 1217 EngOilHotIO 1;
BA_ "SignalType" SG_ 1217 OAT_PT_EstV "ENM";
BA_ "SignalLongName" SG_ 1217 OAT_PT_EstV "Outside Air Temperature Powertrain Estimated Validity";
BA_ "VNSigAllNodes" SG_ 1217 OAT_PT_EstV 1;
BA_ "SignalType" SG_ 1217 LegDiagStndCndMet "BLN";
BA_ "SignalLongName" SG_ 1217 LegDiagStndCndMet "Legislated Diagnostics Standard Conditions Met";
BA_ "VNSigAllNodes" SG_ 1217 LegDiagStndCndMet 1;
BA_ "SignalType" SG_ 1217 LegDiagStndCndFltPr "BLN";
BA_ "SignalLongName" SG_ 1217 LegDiagStndCndFltPr "Legislated Diagnostics Standard Conditions Fault Present";
BA_ "VNSigAllNodes" SG_ 1217 LegDiagStndCndFltPr 1;
BA_ "SignalType" SG_ 1217 OAT_PT_EstM "ENM";
BA_ "SignalLongName" SG_ 1217 OAT_PT_EstM "Outside Air Temperature Powertrain Estimated Mask";
BA_ "VNSigAllNodes" SG_ 1217 OAT_PT_EstM 1;
BA_ "SignalType" SG_ 1217 OAT_PT_Est "UNM";
BA_ "SignalLongName" SG_ 1217 OAT_PT_Est "Outside Air Temperature Powertrain Estimated";
BA_ "VNSigAllNodes" SG_ 1217 OAT_PT_Est 1;
BA_ "SignalType" SG_ 1217 EngWrmUpAch "BLN";
BA_ "SignalLongName" SG_ 1217 EngWrmUpAch "Engine Warm Up Cycle Achieved";
BA_ "VNSigAllNodes" SG_ 1217 EngWrmUpAch 1;
BA_ "SignalType" SG_ 1217 EngIntAirTmpV "ENM";
BA_ "SignalLongName" SG_ 1217 EngIntAirTmpV "Engine Intake Air Temperature Validity";
BA_ "VNSigAllNodes" SG_ 1217 EngIntAirTmpV 1;
BA_ "SignalType" SG_ 1217 EngIntAirTmp "UNM";
BA_ "SignalLongName" SG_ 1217 EngIntAirTmp "Engine Intake Air Temperature";
BA_ "VNSigAllNodes" SG_ 1217 EngIntAirTmp 1;
BA_ "SignalType" SG_ 1217 EngCltTmpV "ENM";
BA_ "SignalLongName" SG_ 1217 EngCltTmpV "Engine Coolant Temperature Validity";
BA_ "VNSigAllNodes" SG_ 1217 EngCltTmpV 1;
BA_ "SignalType" SG_ 1217 EngCltTmp "UNM";
BA_ "SignalLongName" SG_ 1217 EngCltTmp "Engine Coolant Temperature";
BA_ "VNSigAllNodes" SG_ 1217 EngCltTmp 1;
BA_ "SignalType" SG_ 1217 BarPrsAbsV "ENM";
BA_ "SignalLongName" SG_ 1217 BarPrsAbsV "Barometric Pressure Absolute Validity";
BA_ "VNSigAllNodes" SG_ 1217 BarPrsAbsV 1;
BA_ "SignalType" SG_ 1217 BarPrsAbs "UNM";
BA_ "SignalLongName" SG_ 1217 BarPrsAbs "Barometric Pressure Absolute";
BA_ "VNSigAllNodes" SG_ 1217 BarPrsAbs 1;
BA_ "SignalType" SG_ 328 StrngAsstRdcdIO "BLN";
BA_ "SignalLongName" SG_ 328 StrngAsstRdcdIO "Steering Assist Reduced Indication On";
BA_ "VNSigAllNodes" SG_ 328 StrngAsstRdcdIO 1;
BA_ "SignalType" SG_ 328 PwrStrIO "BLN";
BA_ "SignalLongName" SG_ 328 PwrStrIO "Power Steering Indication On";
BA_ "VNSigAllNodes" SG_ 328 PwrStrIO 1;
BA_ "SignalType" SG_ 309 PedFrndlyAlrtSndMnAct "BLN";
BA_ "SignalLongName" SG_ 309 PedFrndlyAlrtSndMnAct "Pedestrian Friendly Alert Sound Manual Activation";
BA_ "VNSigAllNodes" SG_ 309 PedFrndlyAlrtSndMnAct 1;
BA_ "SignalType" SG_ 309 ColPrSysCustReq "ENM";
BA_ "SignalLongName" SG_ 309 ColPrSysCustReq "Collision Preparation System Customization Setting Request";
BA_ "VNSigAllNodes" SG_ 309 ColPrSysCustReq 1;
BA_ "SignalType" SG_ 309 SecV "ENM";
BA_ "SignalLongName" SG_ 309 SecV "Seconds Validity";
BA_ "VNSigAllNodes" SG_ 309 SecV 1;
BA_ "SignalType" SG_ 309 Sec "UNM";
BA_ "SignalLongName" SG_ 309 Sec "Seconds";
BA_ "VNSigAllNodes" SG_ 309 Sec 1;
BA_ "SignalType" SG_ 309 CldrYr_154 "UNM";
BA_ "SignalLongName" SG_ 309 CldrYr_154 "Calendar Year";
BA_ "VNSigAllNodes" SG_ 309 CldrYr_154 1;
BA_ "SignalType" SG_ 309 CldrYr "UNM";
BA_ "SignalLongName" SG_ 309 CldrYr "Calendar Year";
BA_ "VNSigAllNodes" SG_ 309 CldrYr 1;
BA_ "SignalType" SG_ 309 CldrMth_154 "ENM";
BA_ "SignalLongName" SG_ 309 CldrMth_154 "Calendar Month";
BA_ "VNSigAllNodes" SG_ 309 CldrMth_154 1;
BA_ "SignalType" SG_ 309 CldrMth "ENM";
BA_ "SignalLongName" SG_ 309 CldrMth "Calendar Month";
BA_ "VNSigAllNodes" SG_ 309 CldrMth 1;
BA_ "SignalType" SG_ 309 CldrDay_154 "UNM";
BA_ "SignalLongName" SG_ 309 CldrDay_154 "Calendar Day";
BA_ "VNSigAllNodes" SG_ 309 CldrDay_154 1;
BA_ "SignalType" SG_ 309 CldrDay "UNM";
BA_ "SignalLongName" SG_ 309 CldrDay "Calendar Day";
BA_ "VNSigAllNodes" SG_ 309 CldrDay 1;
BA_ "SignalType" SG_ 309 AutoHiBmVDA "ENM";
BA_ "SignalLongName" SG_ 309 AutoHiBmVDA "Automatic High Beam Virtual Device Availability";
BA_ "GenSigStartValue" SG_ 309 AutoHiBmVDA 1;
BA_ "VNSigAllNodes" SG_ 309 AutoHiBmVDA 1;
BA_ "SignalType" SG_ 309 CtLghtDet "BLN";
BA_ "SignalLongName" SG_ 309 CtLghtDet "City Light Detected";
BA_ "VNSigAllNodes" SG_ 309 CtLghtDet 1;
BA_ "SignalType" SG_ 309 RrClosVDA "ENM";
BA_ "SignalLongName" SG_ 309 RrClosVDA "Rear Closure Virtual Device Availability";
BA_ "GenSigStartValue" SG_ 309 RrClosVDA 1;
BA_ "VNSigAllNodes" SG_ 309 RrClosVDA 1;
BA_ "SignalType" SG_ 309 TCSysDisSwAtv "BLN";
BA_ "SignalLongName" SG_ 309 TCSysDisSwAtv "Traction Control System Disable Switch Active";
BA_ "VNSigAllNodes" SG_ 309 TCSysDisSwAtv 1;
BA_ "SignalType" SG_ 309 VehMovState "ENM";
BA_ "SignalLongName" SG_ 309 VehMovState "Vehicle Movement State";
BA_ "VNSigAllNodes" SG_ 309 VehMovState 1;
BA_ "SignalType" SG_ 309 TCSysDisSwAtvV "ENM";
BA_ "SignalLongName" SG_ 309 TCSysDisSwAtvV "Traction Control System Disable Switch Active Validity";
BA_ "VNSigAllNodes" SG_ 309 TCSysDisSwAtvV 1;
BA_ "SignalType" SG_ 309 HillDesCtrlMdSwActV "ENM";
BA_ "SignalLongName" SG_ 309 HillDesCtrlMdSwActV "Hill Descent Control Mode Switch Active Validity";
BA_ "VNSigAllNodes" SG_ 309 HillDesCtrlMdSwActV 1;
BA_ "SignalType" SG_ 309 WSWshSwAtv "BLN";
BA_ "SignalLongName" SG_ 309 WSWshSwAtv "Windshield Washer Switch Active";
BA_ "VNSigAllNodes" SG_ 309 WSWshSwAtv 1;
BA_ "SignalType" SG_ 309 HillDesCtrlMdSwAct "BLN";
BA_ "SignalLongName" SG_ 309 HillDesCtrlMdSwAct "Hill Descent Control Mode Switch Active";
BA_ "VNSigAllNodes" SG_ 309 HillDesCtrlMdSwAct 1;
BA_ "SignalType" SG_ 309 RrClosAjarSwAct "BLN";
BA_ "SignalLongName" SG_ 309 RrClosAjarSwAct "Rear Closure Ajar Switch Active";
BA_ "VNSigAllNodes" SG_ 309 RrClosAjarSwAct 1;
BA_ "SignalType" SG_ 309 WSWprAct "BLN";
BA_ "SignalLongName" SG_ 309 WSWprAct "Windshield Wiper Active";
BA_ "VNSigAllNodes" SG_ 309 WSWprAct 1;
BA_ "VNSigSLHSSharedDiagnostic" SG_ 1622 DgnInf 1;
BA_ "SignalType" SG_ 1622 DgnInf "UNM";
BA_ "SignalLongName" SG_ 1622 DgnInf "Diagnostic Information";
BA_ "VNSigAllNodes" SG_ 1622 DgnInf 1;
BA_ "SignalType" SG_ 1905 DTCI_DTCFaultType_771 "ENM";
BA_ "PacketOrder" SG_ 1905 DTCI_DTCFaultType_771 20;
BA_ "SignalLongName" SG_ 1905 DTCI_DTCFaultType_771 "Diagnostic Trouble Code Information Extended : Diagnostic Trouble Code Fault Type";
BA_ "VNSigAllNodes" SG_ 1905 DTCI_DTCFaultType_771 1;
BA_ "SignalType" SG_ 1905 DTCI_CodeSupported_771 "BLN";
BA_ "PacketOrder" SG_ 1905 DTCI_CodeSupported_771 19;
BA_ "SignalLongName" SG_ 1905 DTCI_CodeSupported_771 "Diagnostic Trouble Code Information Extended : Code Supported";
BA_ "VNSigAllNodes" SG_ 1905 DTCI_CodeSupported_771 1;
BA_ "SignalType" SG_ 1905 DTCI_CurrentStatus_771 "BLN";
BA_ "PacketOrder" SG_ 1905 DTCI_CurrentStatus_771 18;
BA_ "SignalLongName" SG_ 1905 DTCI_CurrentStatus_771 "Diagnostic Trouble Code Information Extended : Current Status";
BA_ "VNSigAllNodes" SG_ 1905 DTCI_CurrentStatus_771 1;
BA_ "SignalType" SG_ 1905 DTCI_TstNPsdCdClrdSt_771 "BLN";
BA_ "PacketOrder" SG_ 1905 DTCI_TstNPsdCdClrdSt_771 17;
BA_ "SignalLongName" SG_ 1905 DTCI_TstNPsdCdClrdSt_771 "Diagnostic Trouble Code Information Extended : Test Not Passed Since Code Cleared Status";
BA_ "VNSigAllNodes" SG_ 1905 DTCI_TstNPsdCdClrdSt_771 1;
BA_ "SignalType" SG_ 1905 DTCI_TstFldCdClrdStat_771 "BLN";
BA_ "PacketOrder" SG_ 1905 DTCI_TstFldCdClrdStat_771 16;
BA_ "SignalLongName" SG_ 1905 DTCI_TstFldCdClrdStat_771 "Diagnostic Trouble Code Information Extended : Test Failed Since Code Cleared Status";
BA_ "VNSigAllNodes" SG_ 1905 DTCI_TstFldCdClrdStat_771 1;
BA_ "SignalType" SG_ 1905 DTCI_HistStat_771 "BLN";
BA_ "PacketOrder" SG_ 1905 DTCI_HistStat_771 15;
BA_ "SignalLongName" SG_ 1905 DTCI_HistStat_771 "Diagnostic Trouble Code Information Extended : History Status";
BA_ "VNSigAllNodes" SG_ 1905 DTCI_HistStat_771 1;
BA_ "SignalType" SG_ 1905 DTCI_TstNPsdPwrUpSt_771 "BLN";
BA_ "PacketOrder" SG_ 1905 DTCI_TstNPsdPwrUpSt_771 14;
BA_ "SignalLongName" SG_ 1905 DTCI_TstNPsdPwrUpSt_771 "Diagnostic Trouble Code Information Extended : Test Not Passed Since Power Up Status";
BA_ "VNSigAllNodes" SG_ 1905 DTCI_TstNPsdPwrUpSt_771 1;
BA_ "SignalType" SG_ 1905 DTCI_TstFldPwrUpSt_771 "BLN";
BA_ "PacketOrder" SG_ 1905 DTCI_TstFldPwrUpSt_771 13;
BA_ "SignalLongName" SG_ 1905 DTCI_TstFldPwrUpSt_771 "Diagnostic Trouble Code Information Extended : Test Failed Since Power Up Status";
BA_ "VNSigAllNodes" SG_ 1905 DTCI_TstFldPwrUpSt_771 1;
BA_ "SignalType" SG_ 1905 DTCI_WrnIndRqdSt_771 "BLN";
BA_ "PacketOrder" SG_ 1905 DTCI_WrnIndRqdSt_771 12;
BA_ "SignalLongName" SG_ 1905 DTCI_WrnIndRqdSt_771 "Diagnostic Trouble Code Information Extended : Warning Indicator Requested Status";
BA_ "VNSigAllNodes" SG_ 1905 DTCI_WrnIndRqdSt_771 1;
BA_ "SignalType" SG_ 1905 DTCI_DTCFailType_771 "UNM";
BA_ "PacketOrder" SG_ 1905 DTCI_DTCFailType_771 11;
BA_ "SignalLongName" SG_ 1905 DTCI_DTCFailType_771 "Diagnostic Trouble Code Information Extended : Diagnostic Trouble Code Failure Type";
BA_ "VNSigAllNodes" SG_ 1905 DTCI_DTCFailType_771 1;
BA_ "SignalType" SG_ 1905 DTCI_DTCNumber_771 "UNM";
BA_ "PacketOrder" SG_ 1905 DTCI_DTCNumber_771 10;
BA_ "SignalLongName" SG_ 1905 DTCI_DTCNumber_771 "Diagnostic Trouble Code Information Extended : Diagnostic Trouble Code Number";
BA_ "VNSigAllNodes" SG_ 1905 DTCI_DTCNumber_771 1;
BA_ "SignalType" SG_ 1905 DTCI_DTCSource_771 "UNM";
BA_ "PacketOrder" SG_ 1905 DTCI_DTCSource_771 9;
BA_ "SignalLongName" SG_ 1905 DTCI_DTCSource_771 "Diagnostic Trouble Code Information Extended : Diagnostic Trouble Code Source";
BA_ "VNSigAllNodes" SG_ 1905 DTCI_DTCSource_771 1;
BA_ "SignalType" SG_ 1905 DTCI_DTCTriggered_771 "BLN";
BA_ "PacketOrder" SG_ 1905 DTCI_DTCTriggered_771 8;
BA_ "SignalLongName" SG_ 1905 DTCI_DTCTriggered_771 "Diagnostic Trouble Code Information Extended : Diagnostic Trouble Code Triggered";
BA_ "VNSigAllNodes" SG_ 1905 DTCI_DTCTriggered_771 1;
BA_ "SignalType" SG_ 1905 DTCIUnused7_771 "BLN";
BA_ "PacketOrder" SG_ 1905 DTCIUnused7_771 7;
BA_ "SignalLongName" SG_ 1905 DTCIUnused7_771 "Diagnostic Trouble Code Information Extended : Unused 7";
BA_ "VNSigAllNodes" SG_ 1905 DTCIUnused7_771 1;
BA_ "SignalType" SG_ 1905 DTCIUnused6_771 "BLN";
BA_ "PacketOrder" SG_ 1905 DTCIUnused6_771 6;
BA_ "SignalLongName" SG_ 1905 DTCIUnused6_771 "Diagnostic Trouble Code Information Extended : Unused 6";
BA_ "VNSigAllNodes" SG_ 1905 DTCIUnused6_771 1;
BA_ "SignalType" SG_ 1905 DTCIUnused5_771 "BLN";
BA_ "PacketOrder" SG_ 1905 DTCIUnused5_771 5;
BA_ "SignalLongName" SG_ 1905 DTCIUnused5_771 "Diagnostic Trouble Code Information Extended : Unused 5";
BA_ "VNSigAllNodes" SG_ 1905 DTCIUnused5_771 1;
BA_ "SignalType" SG_ 1905 DTCIUnused4_771 "BLN";
BA_ "PacketOrder" SG_ 1905 DTCIUnused4_771 4;
BA_ "SignalLongName" SG_ 1905 DTCIUnused4_771 "Diagnostic Trouble Code Information Extended : Unused 4";
BA_ "VNSigAllNodes" SG_ 1905 DTCIUnused4_771 1;
BA_ "SignalType" SG_ 1905 DTCIUnused3_771 "BLN";
BA_ "PacketOrder" SG_ 1905 DTCIUnused3_771 3;
BA_ "SignalLongName" SG_ 1905 DTCIUnused3_771 "Diagnostic Trouble Code Information Extended : Unused 3";
BA_ "VNSigAllNodes" SG_ 1905 DTCIUnused3_771 1;
BA_ "SignalType" SG_ 1905 DTCIUnused2_771 "BLN";
BA_ "PacketOrder" SG_ 1905 DTCIUnused2_771 2;
BA_ "SignalLongName" SG_ 1905 DTCIUnused2_771 "Diagnostic Trouble Code Information Extended : Unused 2";
BA_ "VNSigAllNodes" SG_ 1905 DTCIUnused2_771 1;
BA_ "SignalType" SG_ 1905 DTCIUnused1_771 "BLN";
BA_ "PacketOrder" SG_ 1905 DTCIUnused1_771 1;
BA_ "SignalLongName" SG_ 1905 DTCIUnused1_771 "Diagnostic Trouble Code Information Extended : Unused 1";
BA_ "VNSigAllNodes" SG_ 1905 DTCIUnused1_771 1;
BA_ "SignalType" SG_ 1930 DTCI_CodeSupported_78A "BLN";
BA_ "PacketOrder" SG_ 1930 DTCI_CodeSupported_78A 19;
BA_ "SignalLongName" SG_ 1930 DTCI_CodeSupported_78A "Diagnostic Trouble Code Information Extended 78A : Code Supported";
BA_ "VNSigAllNodes" SG_ 1930 DTCI_CodeSupported_78A 1;
BA_ "SignalType" SG_ 1930 DTCI_CurrentStatus_78A "BLN";
BA_ "PacketOrder" SG_ 1930 DTCI_CurrentStatus_78A 18;
BA_ "SignalLongName" SG_ 1930 DTCI_CurrentStatus_78A "Diagnostic Trouble Code Information Extended 78A : Current Status";
BA_ "VNSigAllNodes" SG_ 1930 DTCI_CurrentStatus_78A 1;
BA_ "SignalType" SG_ 1930 DTCI_DTCFailType_78A "UNM";
BA_ "PacketOrder" SG_ 1930 DTCI_DTCFailType_78A 11;
BA_ "SignalLongName" SG_ 1930 DTCI_DTCFailType_78A "Diagnostic Trouble Code Information Extended 78A : Diagnostic Trouble Code Failure Type";
BA_ "VNSigAllNodes" SG_ 1930 DTCI_DTCFailType_78A 1;
BA_ "SignalType" SG_ 1930 DTCI_DTCFaultType_78A "ENM";
BA_ "PacketOrder" SG_ 1930 DTCI_DTCFaultType_78A 20;
BA_ "SignalLongName" SG_ 1930 DTCI_DTCFaultType_78A "Diagnostic Trouble Code Information Extended 78A : Diagnostic Trouble Code Fault Type";
BA_ "VNSigAllNodes" SG_ 1930 DTCI_DTCFaultType_78A 1;
BA_ "SignalType" SG_ 1930 DTCI_DTCNumber_78A "UNM";
BA_ "PacketOrder" SG_ 1930 DTCI_DTCNumber_78A 10;
BA_ "SignalLongName" SG_ 1930 DTCI_DTCNumber_78A "Diagnostic Trouble Code Information Extended 78A : Diagnostic Trouble Code Number";
BA_ "VNSigAllNodes" SG_ 1930 DTCI_DTCNumber_78A 1;
BA_ "SignalType" SG_ 1930 DTCI_DTCSource_78A "UNM";
BA_ "PacketOrder" SG_ 1930 DTCI_DTCSource_78A 9;
BA_ "SignalLongName" SG_ 1930 DTCI_DTCSource_78A "Diagnostic Trouble Code Information Extended 78A : Diagnostic Trouble Code Source";
BA_ "VNSigAllNodes" SG_ 1930 DTCI_DTCSource_78A 1;
BA_ "SignalType" SG_ 1930 DTCI_DTCTriggered_78A "BLN";
BA_ "PacketOrder" SG_ 1930 DTCI_DTCTriggered_78A 8;
BA_ "SignalLongName" SG_ 1930 DTCI_DTCTriggered_78A "Diagnostic Trouble Code Information Extended 78A : Diagnostic Trouble Code Triggered";
BA_ "VNSigAllNodes" SG_ 1930 DTCI_DTCTriggered_78A 1;
BA_ "SignalType" SG_ 1930 DTCI_HistStat_78A "BLN";
BA_ "PacketOrder" SG_ 1930 DTCI_HistStat_78A 15;
BA_ "SignalLongName" SG_ 1930 DTCI_HistStat_78A "Diagnostic Trouble Code Information Extended 78A : History Status";
BA_ "VNSigAllNodes" SG_ 1930 DTCI_HistStat_78A 1;
BA_ "SignalType" SG_ 1930 DTCI_TstFldCdClrdStat_78A "BLN";
BA_ "PacketOrder" SG_ 1930 DTCI_TstFldCdClrdStat_78A 16;
BA_ "SignalLongName" SG_ 1930 DTCI_TstFldCdClrdStat_78A "Diagnostic Trouble Code Information Extended 78A : Test Failed Since Code Cleared Status";
BA_ "VNSigAllNodes" SG_ 1930 DTCI_TstFldCdClrdStat_78A 1;
BA_ "SignalType" SG_ 1930 DTCI_TstFldPwrUpSt_78A "BLN";
BA_ "PacketOrder" SG_ 1930 DTCI_TstFldPwrUpSt_78A 13;
BA_ "SignalLongName" SG_ 1930 DTCI_TstFldPwrUpSt_78A "Diagnostic Trouble Code Information Extended 78A : Test Failed Since Power Up Status";
BA_ "VNSigAllNodes" SG_ 1930 DTCI_TstFldPwrUpSt_78A 1;
BA_ "SignalType" SG_ 1930 DTCI_TstNPsdCdClrdSt_78A "BLN";
BA_ "PacketOrder" SG_ 1930 DTCI_TstNPsdCdClrdSt_78A 17;
BA_ "SignalLongName" SG_ 1930 DTCI_TstNPsdCdClrdSt_78A "Diagnostic Trouble Code Information Extended 78A : Test Not Passed Since Code Cleared Status";
BA_ "VNSigAllNodes" SG_ 1930 DTCI_TstNPsdCdClrdSt_78A 1;
BA_ "SignalType" SG_ 1930 DTCI_TstNPsdPwrUpSt_78A "BLN";
BA_ "PacketOrder" SG_ 1930 DTCI_TstNPsdPwrUpSt_78A 14;
BA_ "SignalLongName" SG_ 1930 DTCI_TstNPsdPwrUpSt_78A "Diagnostic Trouble Code Information Extended 78A : Test Not Passed Since Power Up Status";
BA_ "VNSigAllNodes" SG_ 1930 DTCI_TstNPsdPwrUpSt_78A 1;
BA_ "SignalType" SG_ 1930 DTCIUnused1_78A "BLN";
BA_ "PacketOrder" SG_ 1930 DTCIUnused1_78A 1;
BA_ "SignalLongName" SG_ 1930 DTCIUnused1_78A "Diagnostic Trouble Code Information Extended 78A : Unused 1";
BA_ "VNSigAllNodes" SG_ 1930 DTCIUnused1_78A 1;
BA_ "SignalType" SG_ 1930 DTCIUnused2_78A "BLN";
BA_ "PacketOrder" SG_ 1930 DTCIUnused2_78A 2;
BA_ "SignalLongName" SG_ 1930 DTCIUnused2_78A "Diagnostic Trouble Code Information Extended 78A : Unused 2";
BA_ "VNSigAllNodes" SG_ 1930 DTCIUnused2_78A 1;
BA_ "SignalType" SG_ 1930 DTCIUnused3_78A "BLN";
BA_ "PacketOrder" SG_ 1930 DTCIUnused3_78A 3;
BA_ "SignalLongName" SG_ 1930 DTCIUnused3_78A "Diagnostic Trouble Code Information Extended 78A : Unused 3";
BA_ "VNSigAllNodes" SG_ 1930 DTCIUnused3_78A 1;
BA_ "SignalType" SG_ 1930 DTCIUnused4_78A "BLN";
BA_ "PacketOrder" SG_ 1930 DTCIUnused4_78A 4;
BA_ "SignalLongName" SG_ 1930 DTCIUnused4_78A "Diagnostic Trouble Code Information Extended 78A : Unused 4";
BA_ "VNSigAllNodes" SG_ 1930 DTCIUnused4_78A 1;
BA_ "SignalType" SG_ 1930 DTCIUnused5_78A "BLN";
BA_ "PacketOrder" SG_ 1930 DTCIUnused5_78A 5;
BA_ "SignalLongName" SG_ 1930 DTCIUnused5_78A "Diagnostic Trouble Code Information Extended 78A : Unused 5";
BA_ "VNSigAllNodes" SG_ 1930 DTCIUnused5_78A 1;
BA_ "SignalType" SG_ 1930 DTCIUnused6_78A "BLN";
BA_ "PacketOrder" SG_ 1930 DTCIUnused6_78A 6;
BA_ "SignalLongName" SG_ 1930 DTCIUnused6_78A "Diagnostic Trouble Code Information Extended 78A : Unused 6";
BA_ "VNSigAllNodes" SG_ 1930 DTCIUnused6_78A 1;
BA_ "SignalType" SG_ 1930 DTCIUnused7_78A "BLN";
BA_ "PacketOrder" SG_ 1930 DTCIUnused7_78A 7;
BA_ "SignalLongName" SG_ 1930 DTCIUnused7_78A "Diagnostic Trouble Code Information Extended 78A : Unused 7";
BA_ "VNSigAllNodes" SG_ 1930 DTCIUnused7_78A 1;
BA_ "SignalType" SG_ 1930 DTCI_WrnIndRqdSt_78A "BLN";
BA_ "PacketOrder" SG_ 1930 DTCI_WrnIndRqdSt_78A 12;
BA_ "SignalLongName" SG_ 1930 DTCI_WrnIndRqdSt_78A "Diagnostic Trouble Code Information Extended 78A : Warning Indicator Requested Status";
BA_ "VNSigAllNodes" SG_ 1930 DTCI_WrnIndRqdSt_78A 1;
BA_REL_ "GenSigRxStartValue" BU_SG_REL_ ADIMb_PHS SG_ 355 RdRghnsStatRed "Normal";
BA_REL_ "GenSigSuprvResp" BU_SG_REL_ ADIMb_PHS SG_ 355 RdRghnsStatRed 1;
BA_REL_ "GenSigTimeoutMsg" BU_SG_REL_ ADIMb_PHS SG_ 355 RdRghnsStatRed 355;
BA_REL_ "GenSigTimeoutTime" BU_SG_REL_ ADIMb_PHS SG_ 355 RdRghnsStatRed 50;
BA_REL_ "GenSigRxStartValue" BU_SG_REL_ ADIMb_PHS SG_ 355 RdRghnsIndctnRed "0";
BA_REL_ "GenSigSuprvResp" BU_SG_REL_ ADIMb_PHS SG_ 355 RdRghnsIndctnRed 1;
BA_REL_ "GenSigTimeoutMsg" BU_SG_REL_ ADIMb_PHS SG_ 355 RdRghnsIndctnRed 355;
BA_REL_ "GenSigTimeoutTime" BU_SG_REL_ ADIMb_PHS SG_ 355 RdRghnsIndctnRed 50;
BA_REL_ "GenSigRxStartValue" BU_SG_REL_ ADIMb_PHS SG_ 355 PriTCSStatRed "Unknown";
BA_REL_ "GenSigSuprvResp" BU_SG_REL_ ADIMb_PHS SG_ 355 PriTCSStatRed 1;
BA_REL_ "GenSigTimeoutMsg" BU_SG_REL_ ADIMb_PHS SG_ 355 PriTCSStatRed 355;
BA_REL_ "GenSigTimeoutTime" BU_SG_REL_ ADIMb_PHS SG_ 355 PriTCSStatRed 50;
BA_REL_ "GenSigRxStartValue" BU_SG_REL_ ADIMb_PHS SG_ 355 PriGrsHydLkDtctdRed "False";
BA_REL_ "GenSigSuprvResp" BU_SG_REL_ ADIMb_PHS SG_ 355 PriGrsHydLkDtctdRed 1;
BA_REL_ "GenSigTimeoutMsg" BU_SG_REL_ ADIMb_PHS SG_ 355 PriGrsHydLkDtctdRed 355;
BA_REL_ "GenSigTimeoutTime" BU_SG_REL_ ADIMb_PHS SG_ 355 PriGrsHydLkDtctdRed 50;
BA_REL_ "GenSigRxStartValue" BU_SG_REL_ ADIMb_PHS SG_ 355 PriGrsHydCmpDtctdRed "False";
BA_REL_ "GenSigSuprvResp" BU_SG_REL_ ADIMb_PHS SG_ 355 PriGrsHydCmpDtctdRed 1;
BA_REL_ "GenSigTimeoutMsg" BU_SG_REL_ ADIMb_PHS SG_ 355 PriGrsHydCmpDtctdRed 355;
BA_REL_ "GenSigTimeoutTime" BU_SG_REL_ ADIMb_PHS SG_ 355 PriGrsHydCmpDtctdRed 50;
BA_REL_ "GenSigRxStartValue" BU_SG_REL_ ADIMb_PHS SG_ 355 PriGrsBrkIneffDtctdRed "False";
BA_REL_ "GenSigSuprvResp" BU_SG_REL_ ADIMb_PHS SG_ 355 PriGrsBrkIneffDtctdRed 1;
BA_REL_ "GenSigTimeoutMsg" BU_SG_REL_ ADIMb_PHS SG_ 355 PriGrsBrkIneffDtctdRed 355;
BA_REL_ "GenSigTimeoutTime" BU_SG_REL_ ADIMb_PHS SG_ 355 PriGrsBrkIneffDtctdRed 50;
BA_REL_ "GenSigRxStartValue" BU_SG_REL_ ADIMb_PHS SG_ 355 PriESCStatRed "Unknown";
BA_REL_ "GenSigSuprvResp" BU_SG_REL_ ADIMb_PHS SG_ 355 PriESCStatRed 1;
BA_REL_ "GenSigTimeoutMsg" BU_SG_REL_ ADIMb_PHS SG_ 355 PriESCStatRed 355;
BA_REL_ "GenSigTimeoutTime" BU_SG_REL_ ADIMb_PHS SG_ 355 PriESCStatRed 50;
BA_REL_ "GenSigRxStartValue" BU_SG_REL_ ADIMb_PHS SG_ 355 PriDynCtrlStatRedChksm "0";
BA_REL_ "GenSigRxStartValue" BU_SG_REL_ ADIMb_PHS SG_ 355 PriDynCtrlStatRedARC "0";
BA_REL_ "GenSigRxStartValue" BU_SG_REL_ ADIMb_PHS SG_ 355 PriDRPStatRed "Unknown";
BA_REL_ "GenSigSuprvResp" BU_SG_REL_ ADIMb_PHS SG_ 355 PriDRPStatRed 1;
BA_REL_ "GenSigTimeoutMsg" BU_SG_REL_ ADIMb_PHS SG_ 355 PriDRPStatRed 355;
BA_REL_ "GenSigTimeoutTime" BU_SG_REL_ ADIMb_PHS SG_ 355 PriDRPStatRed 50;
BA_REL_ "GenSigRxStartValue" BU_SG_REL_ ADIMb_PHS SG_ 355 PriABSStatRed "Unknown";
BA_REL_ "GenSigSuprvResp" BU_SG_REL_ ADIMb_PHS SG_ 355 PriABSStatRed 1;
BA_REL_ "GenSigTimeoutMsg" BU_SG_REL_ ADIMb_PHS SG_ 355 PriABSStatRed 355;
BA_REL_ "GenSigTimeoutTime" BU_SG_REL_ ADIMb_PHS SG_ 355 PriABSStatRed 50;
BA_REL_ "GenSigRxStartValue" BU_SG_REL_ ADIMb_PHS SG_ 355 EstBrkRtrTempStatRed "Normal";
BA_REL_ "GenSigSuprvResp" BU_SG_REL_ ADIMb_PHS SG_ 355 EstBrkRtrTempStatRed 1;
BA_REL_ "GenSigTimeoutMsg" BU_SG_REL_ ADIMb_PHS SG_ 355 EstBrkRtrTempStatRed 355;
BA_REL_ "GenSigTimeoutTime" BU_SG_REL_ ADIMb_PHS SG_ 355 EstBrkRtrTempStatRed 50;
BA_REL_ "GenSigRxStartValue" BU_SG_REL_ ADIMb_PHS SG_ 355 EstBrkRtrTempRRRed "2.857";
BA_REL_ "GenSigSuprvResp" BU_SG_REL_ ADIMb_PHS SG_ 355 EstBrkRtrTempRRRed 1;
BA_REL_ "GenSigTimeoutMsg" BU_SG_REL_ ADIMb_PHS SG_ 355 EstBrkRtrTempRRRed 355;
BA_REL_ "GenSigTimeoutTime" BU_SG_REL_ ADIMb_PHS SG_ 355 EstBrkRtrTempRRRed 50;
BA_REL_ "GenSigRxStartValue" BU_SG_REL_ ADIMb_PHS SG_ 355 EstBrkRtrTempRFRed "2.857";
BA_REL_ "GenSigSuprvResp" BU_SG_REL_ ADIMb_PHS SG_ 355 EstBrkRtrTempRFRed 1;
BA_REL_ "GenSigTimeoutMsg" BU_SG_REL_ ADIMb_PHS SG_ 355 EstBrkRtrTempRFRed 355;
BA_REL_ "GenSigTimeoutTime" BU_SG_REL_ ADIMb_PHS SG_ 355 EstBrkRtrTempRFRed 50;
BA_REL_ "GenSigRxStartValue" BU_SG_REL_ ADIMb_PHS SG_ 355 EstBrkRtrTempLRRed "2.857";
BA_REL_ "GenSigSuprvResp" BU_SG_REL_ ADIMb_PHS SG_ 355 EstBrkRtrTempLRRed 1;
BA_REL_ "GenSigTimeoutMsg" BU_SG_REL_ ADIMb_PHS SG_ 355 EstBrkRtrTempLRRed 355;
BA_REL_ "GenSigTimeoutTime" BU_SG_REL_ ADIMb_PHS SG_ 355 EstBrkRtrTempLRRed 50;
BA_REL_ "GenSigRxStartValue" BU_SG_REL_ ADIMb_PHS SG_ 355 EstBrkRtrTempLFRed "2.857";
BA_REL_ "GenSigSuprvResp" BU_SG_REL_ ADIMb_PHS SG_ 355 EstBrkRtrTempLFRed 1;
BA_REL_ "GenSigTimeoutMsg" BU_SG_REL_ ADIMb_PHS SG_ 355 EstBrkRtrTempLFRed 355;
BA_REL_ "GenSigTimeoutTime" BU_SG_REL_ ADIMb_PHS SG_ 355 EstBrkRtrTempLFRed 50;
BA_REL_ "GenSigRxStartValue" BU_SG_REL_ ADIMb_PHS SG_ 355 EPBStatRed "Unknown";
BA_REL_ "GenSigSuprvResp" BU_SG_REL_ ADIMb_PHS SG_ 355 EPBStatRed 1;
BA_REL_ "GenSigTimeoutMsg" BU_SG_REL_ ADIMb_PHS SG_ 355 EPBStatRed 355;
BA_REL_ "GenSigTimeoutTime" BU_SG_REL_ ADIMb_PHS SG_ 355 EPBStatRed 50;
BA_REL_ "GenSigRxStartValue" BU_SG_REL_ ADIMb_PHS SG_ 355 EPBApplStRed "Unknown";
BA_REL_ "GenSigSuprvResp" BU_SG_REL_ ADIMb_PHS SG_ 355 EPBApplStRed 1;
BA_REL_ "GenSigTimeoutMsg" BU_SG_REL_ ADIMb_PHS SG_ 355 EPBApplStRed 355;
BA_REL_ "GenSigTimeoutTime" BU_SG_REL_ ADIMb_PHS SG_ 355 EPBApplStRed 50;
BA_REL_ "GenSigRxStartValue" BU_SG_REL_ ADIMb_PHS SG_ 355 BrkFldLvlIndStatRed "Normal";
BA_REL_ "GenSigSuprvResp" BU_SG_REL_ ADIMb_PHS SG_ 355 BrkFldLvlIndStatRed 1;
BA_REL_ "GenSigTimeoutMsg" BU_SG_REL_ ADIMb_PHS SG_ 355 BrkFldLvlIndStatRed 355;
BA_REL_ "GenSigTimeoutTime" BU_SG_REL_ ADIMb_PHS SG_ 355 BrkFldLvlIndStatRed 50;
BA_REL_ "GenSigRxStartValue" BU_SG_REL_ ADIMb_PHS SG_ 355 BrkFldLvILwFldDtctdRed "False";
BA_REL_ "GenSigSuprvResp" BU_SG_REL_ ADIMb_PHS SG_ 355 BrkFldLvILwFldDtctdRed 1;
BA_REL_ "GenSigTimeoutMsg" BU_SG_REL_ ADIMb_PHS SG_ 355 BrkFldLvILwFldDtctdRed 355;
BA_REL_ "GenSigTimeoutTime" BU_SG_REL_ ADIMb_PHS SG_ 355 BrkFldLvILwFldDtctdRed 50;
BA_REL_ "GenSigRxStartValue" BU_SG_REL_ CMMb_PHS SG_ 341 StgCmndTgtAng "0";
BA_REL_ "GenSigSuprvResp" BU_SG_REL_ CMMb_PHS SG_ 341 StgCmndTgtAng 1;
BA_REL_ "GenSigTimeoutMsg" BU_SG_REL_ CMMb_PHS SG_ 341 StgCmndTgtAng 341;
BA_REL_ "GenSigTimeoutTime" BU_SG_REL_ CMMb_PHS SG_ 341 StgCmndTgtAng 30;
BA_REL_ "GenSigRxStartValue" BU_SG_REL_ CMMa_PHS SG_ 341 StgCmndTgtAng "0";
BA_REL_ "GenSigSuprvResp" BU_SG_REL_ CMMa_PHS SG_ 341 StgCmndTgtAng 1;
BA_REL_ "GenSigTimeoutMsg" BU_SG_REL_ CMMa_PHS SG_ 341 StgCmndTgtAng 341;
BA_REL_ "GenSigTimeoutTime" BU_SG_REL_ CMMa_PHS SG_ 341 StgCmndTgtAng 30;
BA_REL_ "GenSigRxStartValue" BU_SG_REL_ ADIMb_PHS SG_ 341 StgCmndTgtAng "0";
BA_REL_ "GenSigSuprvResp" BU_SG_REL_ ADIMb_PHS SG_ 341 StgCmndTgtAng 1;
BA_REL_ "GenSigTimeoutMsg" BU_SG_REL_ ADIMb_PHS SG_ 341 StgCmndTgtAng 341;
BA_REL_ "GenSigTimeoutTime" BU_SG_REL_ ADIMb_PHS SG_ 341 StgCmndTgtAng 25;
BA_REL_ "GenSigRxStartValue" BU_SG_REL_ EOCM2cp_K1_PHS SG_ 341 StgCmndTgtAng "0";
BA_REL_ "GenSigSuprvResp" BU_SG_REL_ EOCM2cp_K1_PHS SG_ 341 StgCmndTgtAng 1;
BA_REL_ "GenSigTimeoutMsg" BU_SG_REL_ EOCM2cp_K1_PHS SG_ 341 StgCmndTgtAng 341;
BA_REL_ "GenSigTimeoutTime" BU_SG_REL_ EOCM2cp_K1_PHS SG_ 341 StgCmndTgtAng 25;
BA_REL_ "GenSigRxStartValue" BU_SG_REL_ CMMb_PHS SG_ 341 StrgCmndMsgStatV "Valid";
BA_REL_ "GenSigRxStartValue" BU_SG_REL_ CMMa_PHS SG_ 341 StrgCmndMsgStatV "Valid";
BA_REL_ "GenSigRxStartValue" BU_SG_REL_ ADIMb_PHS SG_ 341 StrgCmndMsgStatV "Valid";
BA_REL_ "GenSigSuprvResp" BU_SG_REL_ ADIMb_PHS SG_ 341 StrgCmndMsgStatV 1;
BA_REL_ "GenSigTimeoutMsg" BU_SG_REL_ ADIMb_PHS SG_ 341 StrgCmndMsgStatV 341;
BA_REL_ "GenSigTimeoutTime" BU_SG_REL_ ADIMb_PHS SG_ 341 StrgCmndMsgStatV 25;
BA_REL_ "GenSigRxStartValue" BU_SG_REL_ EOCM2cp_K1_PHS SG_ 341 StrgCmndMsgStatV "Valid";
BA_REL_ "GenSigSuprvResp" BU_SG_REL_ EOCM2cp_K1_PHS SG_ 341 StrgCmndMsgStatV 1;
BA_REL_ "GenSigTimeoutMsg" BU_SG_REL_ EOCM2cp_K1_PHS SG_ 341 StrgCmndMsgStatV 341;
BA_REL_ "GenSigTimeoutTime" BU_SG_REL_ EOCM2cp_K1_PHS SG_ 341 StrgCmndMsgStatV 25;
BA_REL_ "GenSigRxStartValue" BU_SG_REL_ CMMb_PHS SG_ 341 StrgCmndMsgStat "Communication Normal";
BA_REL_ "GenSigSuprvResp" BU_SG_REL_ CMMb_PHS SG_ 341 StrgCmndMsgStat 1;
BA_REL_ "GenSigTimeoutMsg" BU_SG_REL_ CMMb_PHS SG_ 341 StrgCmndMsgStat 341;
BA_REL_ "GenSigTimeoutTime" BU_SG_REL_ CMMb_PHS SG_ 341 StrgCmndMsgStat 30;
BA_REL_ "GenSigRxStartValue" BU_SG_REL_ CMMa_PHS SG_ 341 StrgCmndMsgStat "Communication Normal";
BA_REL_ "GenSigSuprvResp" BU_SG_REL_ CMMa_PHS SG_ 341 StrgCmndMsgStat 1;
BA_REL_ "GenSigTimeoutMsg" BU_SG_REL_ CMMa_PHS SG_ 341 StrgCmndMsgStat 341;
BA_REL_ "GenSigTimeoutTime" BU_SG_REL_ CMMa_PHS SG_ 341 StrgCmndMsgStat 30;
BA_REL_ "GenSigRxStartValue" BU_SG_REL_ ADIMb_PHS SG_ 341 StrgCmndMsgStat "0";
BA_REL_ "GenSigSuprvResp" BU_SG_REL_ ADIMb_PHS SG_ 341 StrgCmndMsgStat 1;
BA_REL_ "GenSigTimeoutMsg" BU_SG_REL_ ADIMb_PHS SG_ 341 StrgCmndMsgStat 341;
BA_REL_ "GenSigTimeoutTime" BU_SG_REL_ ADIMb_PHS SG_ 341 StrgCmndMsgStat 25;
BA_REL_ "GenSigVBitResp" BU_SG_REL_ EOCM2cp_K1_PHS SG_ 341 StrgCmndMsgStat 1;
BA_REL_ "GenSigRxStartValue" BU_SG_REL_ EOCM2cp_K1_PHS SG_ 341 StrgCmndMsgStat "0";
BA_REL_ "GenSigSuprvResp" BU_SG_REL_ EOCM2cp_K1_PHS SG_ 341 StrgCmndMsgStat 1;
BA_REL_ "GenSigTimeoutMsg" BU_SG_REL_ EOCM2cp_K1_PHS SG_ 341 StrgCmndMsgStat 341;
BA_REL_ "GenSigTimeoutTime" BU_SG_REL_ EOCM2cp_K1_PHS SG_ 341 StrgCmndMsgStat 25;
BA_REL_ "GenSigRxStartValue" BU_SG_REL_ CMMb_PHS SG_ 341 StrgCmndMsgUtlzdV "Valid";
BA_REL_ "GenSigRxStartValue" BU_SG_REL_ CMMa_PHS SG_ 341 StrgCmndMsgUtlzdV "Valid";
BA_REL_ "GenSigRxStartValue" BU_SG_REL_ ADIMb_PHS SG_ 341 StrgCmndMsgUtlzdV "Valid";
BA_REL_ "GenSigSuprvResp" BU_SG_REL_ ADIMb_PHS SG_ 341 StrgCmndMsgUtlzdV 1;
BA_REL_ "GenSigTimeoutMsg" BU_SG_REL_ ADIMb_PHS SG_ 341 StrgCmndMsgUtlzdV 341;
BA_REL_ "GenSigTimeoutTime" BU_SG_REL_ ADIMb_PHS SG_ 341 StrgCmndMsgUtlzdV 25;
BA_REL_ "GenSigRxStartValue" BU_SG_REL_ EOCM2cp_K1_PHS SG_ 341 StrgCmndMsgUtlzdV "Valid";
BA_REL_ "GenSigSuprvResp" BU_SG_REL_ EOCM2cp_K1_PHS SG_ 341 StrgCmndMsgUtlzdV 1;
BA_REL_ "GenSigTimeoutMsg" BU_SG_REL_ EOCM2cp_K1_PHS SG_ 341 StrgCmndMsgUtlzdV 341;
BA_REL_ "GenSigTimeoutTime" BU_SG_REL_ EOCM2cp_K1_PHS SG_ 341 StrgCmndMsgUtlzdV 25;
BA_REL_ "GenSigRxStartValue" BU_SG_REL_ CMMb_PHS SG_ 341 StrgCmndMsgUtlzd "Primary Controller";
BA_REL_ "GenSigSuprvResp" BU_SG_REL_ CMMb_PHS SG_ 341 StrgCmndMsgUtlzd 1;
BA_REL_ "GenSigTimeoutMsg" BU_SG_REL_ CMMb_PHS SG_ 341 StrgCmndMsgUtlzd 341;
BA_REL_ "GenSigTimeoutTime" BU_SG_REL_ CMMb_PHS SG_ 341 StrgCmndMsgUtlzd 30;
BA_REL_ "GenSigRxStartValue" BU_SG_REL_ CMMa_PHS SG_ 341 StrgCmndMsgUtlzd "Primary Controller";
BA_REL_ "GenSigSuprvResp" BU_SG_REL_ CMMa_PHS SG_ 341 StrgCmndMsgUtlzd 1;
BA_REL_ "GenSigTimeoutMsg" BU_SG_REL_ CMMa_PHS SG_ 341 StrgCmndMsgUtlzd 341;
BA_REL_ "GenSigTimeoutTime" BU_SG_REL_ CMMa_PHS SG_ 341 StrgCmndMsgUtlzd 30;
BA_REL_ "GenSigRxStartValue" BU_SG_REL_ ADIMb_PHS SG_ 341 StrgCmndMsgUtlzd "0";
BA_REL_ "GenSigSuprvResp" BU_SG_REL_ ADIMb_PHS SG_ 341 StrgCmndMsgUtlzd 1;
BA_REL_ "GenSigTimeoutMsg" BU_SG_REL_ ADIMb_PHS SG_ 341 StrgCmndMsgUtlzd 341;
BA_REL_ "GenSigTimeoutTime" BU_SG_REL_ ADIMb_PHS SG_ 341 StrgCmndMsgUtlzd 25;
BA_REL_ "GenSigVBitResp" BU_SG_REL_ EOCM2cp_K1_PHS SG_ 341 StrgCmndMsgUtlzd 1;
BA_REL_ "GenSigRxStartValue" BU_SG_REL_ EOCM2cp_K1_PHS SG_ 341 StrgCmndMsgUtlzd "0";
BA_REL_ "GenSigSuprvResp" BU_SG_REL_ EOCM2cp_K1_PHS SG_ 341 StrgCmndMsgUtlzd 1;
BA_REL_ "GenSigTimeoutMsg" BU_SG_REL_ EOCM2cp_K1_PHS SG_ 341 StrgCmndMsgUtlzd 341;
BA_REL_ "GenSigTimeoutTime" BU_SG_REL_ EOCM2cp_K1_PHS SG_ 341 StrgCmndMsgUtlzd 25;
BA_REL_ "GenSigRxStartValue" BU_SG_REL_ CMMb_PHS SG_ 341 AutoStrgCmndStatV "Valid";
BA_REL_ "GenSigRxStartValue" BU_SG_REL_ CMMa_PHS SG_ 341 AutoStrgCmndStatV "Valid";
BA_REL_ "GenSigRxStartValue" BU_SG_REL_ ADIMb_PHS SG_ 341 AutoStrgCmndStatV "Valid";
BA_REL_ "GenSigSuprvResp" BU_SG_REL_ ADIMb_PHS SG_ 341 AutoStrgCmndStatV 1;
BA_REL_ "GenSigTimeoutMsg" BU_SG_REL_ ADIMb_PHS SG_ 341 AutoStrgCmndStatV 341;
BA_REL_ "GenSigTimeoutTime" BU_SG_REL_ ADIMb_PHS SG_ 341 AutoStrgCmndStatV 25;
BA_REL_ "GenSigRxStartValue" BU_SG_REL_ EOCM2cp_K1_PHS SG_ 341 AutoStrgCmndStatV "Valid";
BA_REL_ "GenSigSuprvResp" BU_SG_REL_ EOCM2cp_K1_PHS SG_ 341 AutoStrgCmndStatV 1;
BA_REL_ "GenSigTimeoutMsg" BU_SG_REL_ EOCM2cp_K1_PHS SG_ 341 AutoStrgCmndStatV 341;
BA_REL_ "GenSigTimeoutTime" BU_SG_REL_ EOCM2cp_K1_PHS SG_ 341 AutoStrgCmndStatV 25;
BA_REL_ "GenSigRxStartValue" BU_SG_REL_ CMMb_PHS SG_ 341 StgTtlEffTrqDlvd "0";
BA_REL_ "GenSigSuprvResp" BU_SG_REL_ CMMb_PHS SG_ 341 StgTtlEffTrqDlvd 1;
BA_REL_ "GenSigTimeoutMsg" BU_SG_REL_ CMMb_PHS SG_ 341 StgTtlEffTrqDlvd 341;
BA_REL_ "GenSigTimeoutTime" BU_SG_REL_ CMMb_PHS SG_ 341 StgTtlEffTrqDlvd 30;
BA_REL_ "GenSigRxStartValue" BU_SG_REL_ CMMa_PHS SG_ 341 StgTtlEffTrqDlvd "0";
BA_REL_ "GenSigSuprvResp" BU_SG_REL_ CMMa_PHS SG_ 341 StgTtlEffTrqDlvd 1;
BA_REL_ "GenSigTimeoutMsg" BU_SG_REL_ CMMa_PHS SG_ 341 StgTtlEffTrqDlvd 341;
BA_REL_ "GenSigTimeoutTime" BU_SG_REL_ CMMa_PHS SG_ 341 StgTtlEffTrqDlvd 30;
BA_REL_ "GenSigRxStartValue" BU_SG_REL_ EBOOST_OBD_PHS SG_ 341 StgTtlEffTrqDlvd "0";
BA_REL_ "GenSigSuprvResp" BU_SG_REL_ EBOOST_OBD_PHS SG_ 341 StgTtlEffTrqDlvd 1;
BA_REL_ "GenSigTimeoutMsg" BU_SG_REL_ EBOOST_OBD_PHS SG_ 341 StgTtlEffTrqDlvd 341;
BA_REL_ "GenSigTimeoutTime" BU_SG_REL_ EBOOST_OBD_PHS SG_ 341 StgTtlEffTrqDlvd 25;
BA_REL_ "GenSigRxStartValue" BU_SG_REL_ EBCM_PHS SG_ 341 StgTtlEffTrqDlvd "0";
BA_REL_ "GenSigSuprvResp" BU_SG_REL_ EBCM_PHS SG_ 341 StgTtlEffTrqDlvd 1;
BA_REL_ "GenSigTimeoutMsg" BU_SG_REL_ EBCM_PHS SG_ 341 StgTtlEffTrqDlvd 341;
BA_REL_ "GenSigTimeoutTime" BU_SG_REL_ EBCM_PHS SG_ 341 StgTtlEffTrqDlvd 25;
BA_REL_ "GenSigRxStartValue" BU_SG_REL_ ADIMb_PHS SG_ 341 StgTtlEffTrqDlvd "0";
BA_REL_ "GenSigSuprvResp" BU_SG_REL_ ADIMb_PHS SG_ 341 StgTtlEffTrqDlvd 1;
BA_REL_ "GenSigTimeoutMsg" BU_SG_REL_ ADIMb_PHS SG_ 341 StgTtlEffTrqDlvd 341;
BA_REL_ "GenSigTimeoutTime" BU_SG_REL_ ADIMb_PHS SG_ 341 StgTtlEffTrqDlvd 25;
BA_REL_ "GenSigRxStartValue" BU_SG_REL_ EOCM2cp_K1_PHS SG_ 341 StgTtlEffTrqDlvd "0";
BA_REL_ "GenSigSuprvResp" BU_SG_REL_ EOCM2cp_K1_PHS SG_ 341 StgTtlEffTrqDlvd 1;
BA_REL_ "GenSigTimeoutMsg" BU_SG_REL_ EOCM2cp_K1_PHS SG_ 341 StgTtlEffTrqDlvd 341;
BA_REL_ "GenSigTimeoutTime" BU_SG_REL_ EOCM2cp_K1_PHS SG_ 341 StgTtlEffTrqDlvd 25;
BA_REL_ "GenSigRxStartValue" BU_SG_REL_ CMMb_PHS SG_ 341 StgTrqSnsrVStat "Valid";
BA_REL_ "GenSigRxStartValue" BU_SG_REL_ CMMa_PHS SG_ 341 StgTrqSnsrVStat "Valid";
BA_REL_ "GenSigRxStartValue" BU_SG_REL_ EBOOST_OBD_PHS SG_ 341 StgTrqSnsrVStat "Valid";
BA_REL_ "GenSigSuprvResp" BU_SG_REL_ EBOOST_OBD_PHS SG_ 341 StgTrqSnsrVStat 1;
BA_REL_ "GenSigTimeoutMsg" BU_SG_REL_ EBOOST_OBD_PHS SG_ 341 StgTrqSnsrVStat 341;
BA_REL_ "GenSigTimeoutTime" BU_SG_REL_ EBOOST_OBD_PHS SG_ 341 StgTrqSnsrVStat 25;
BA_REL_ "GenSigRxStartValue" BU_SG_REL_ EBCM_PHS SG_ 341 StgTrqSnsrVStat "Valid";
BA_REL_ "GenSigSuprvResp" BU_SG_REL_ EBCM_PHS SG_ 341 StgTrqSnsrVStat 1;
BA_REL_ "GenSigTimeoutMsg" BU_SG_REL_ EBCM_PHS SG_ 341 StgTrqSnsrVStat 341;
BA_REL_ "GenSigTimeoutTime" BU_SG_REL_ EBCM_PHS SG_ 341 StgTrqSnsrVStat 25;
BA_REL_ "GenSigRxStartValue" BU_SG_REL_ ADIMb_PHS SG_ 341 StgTrqSnsrVStat "Valid";
BA_REL_ "GenSigSuprvResp" BU_SG_REL_ ADIMb_PHS SG_ 341 StgTrqSnsrVStat 1;
BA_REL_ "GenSigTimeoutMsg" BU_SG_REL_ ADIMb_PHS SG_ 341 StgTrqSnsrVStat 341;
BA_REL_ "GenSigTimeoutTime" BU_SG_REL_ ADIMb_PHS SG_ 341 StgTrqSnsrVStat 25;
BA_REL_ "GenSigRxStartValue" BU_SG_REL_ EOCM2cp_K1_PHS SG_ 341 StgTrqSnsrVStat "Valid";
BA_REL_ "GenSigSuprvResp" BU_SG_REL_ EOCM2cp_K1_PHS SG_ 341 StgTrqSnsrVStat 1;
BA_REL_ "GenSigTimeoutMsg" BU_SG_REL_ EOCM2cp_K1_PHS SG_ 341 StgTrqSnsrVStat 341;
BA_REL_ "GenSigTimeoutTime" BU_SG_REL_ EOCM2cp_K1_PHS SG_ 341 StgTrqSnsrVStat 25;
BA_REL_ "GenSigRxStartValue" BU_SG_REL_ CMMb_PHS SG_ 341 StgSysOtptStatV "Valid";
BA_REL_ "GenSigRxStartValue" BU_SG_REL_ CMMa_PHS SG_ 341 StgSysOtptStatV "Valid";
BA_REL_ "GenSigRxStartValue" BU_SG_REL_ ADIMb_PHS SG_ 341 StgSysOtptStatV "Valid";
BA_REL_ "GenSigSuprvResp" BU_SG_REL_ ADIMb_PHS SG_ 341 StgSysOtptStatV 1;
BA_REL_ "GenSigTimeoutMsg" BU_SG_REL_ ADIMb_PHS SG_ 341 StgSysOtptStatV 341;
BA_REL_ "GenSigTimeoutTime" BU_SG_REL_ ADIMb_PHS SG_ 341 StgSysOtptStatV 25;
BA_REL_ "GenSigRxStartValue" BU_SG_REL_ EOCM2cp_K1_PHS SG_ 341 StgSysOtptStatV "Valid";
BA_REL_ "GenSigSuprvResp" BU_SG_REL_ EOCM2cp_K1_PHS SG_ 341 StgSysOtptStatV 1;
BA_REL_ "GenSigTimeoutMsg" BU_SG_REL_ EOCM2cp_K1_PHS SG_ 341 StgSysOtptStatV 341;
BA_REL_ "GenSigTimeoutTime" BU_SG_REL_ EOCM2cp_K1_PHS SG_ 341 StgSysOtptStatV 25;
BA_REL_ "GenSigRxStartValue" BU_SG_REL_ CMMb_PHS SG_ 341 StgSysOtptStat "Unknown";
BA_REL_ "GenSigSuprvResp" BU_SG_REL_ CMMb_PHS SG_ 341 StgSysOtptStat 1;
BA_REL_ "GenSigTimeoutMsg" BU_SG_REL_ CMMb_PHS SG_ 341 StgSysOtptStat 341;
BA_REL_ "GenSigTimeoutTime" BU_SG_REL_ CMMb_PHS SG_ 341 StgSysOtptStat 30;
BA_REL_ "GenSigRxStartValue" BU_SG_REL_ CMMa_PHS SG_ 341 StgSysOtptStat "Unknown";
BA_REL_ "GenSigSuprvResp" BU_SG_REL_ CMMa_PHS SG_ 341 StgSysOtptStat 1;
BA_REL_ "GenSigTimeoutMsg" BU_SG_REL_ CMMa_PHS SG_ 341 StgSysOtptStat 341;
BA_REL_ "GenSigTimeoutTime" BU_SG_REL_ CMMa_PHS SG_ 341 StgSysOtptStat 30;
BA_REL_ "GenSigRxStartValue" BU_SG_REL_ ADIMb_PHS SG_ 341 StgSysOtptStat "0";
BA_REL_ "GenSigSuprvResp" BU_SG_REL_ ADIMb_PHS SG_ 341 StgSysOtptStat 1;
BA_REL_ "GenSigTimeoutMsg" BU_SG_REL_ ADIMb_PHS SG_ 341 StgSysOtptStat 341;
BA_REL_ "GenSigTimeoutTime" BU_SG_REL_ ADIMb_PHS SG_ 341 StgSysOtptStat 25;
BA_REL_ "GenSigVBitResp" BU_SG_REL_ EOCM2cp_K1_PHS SG_ 341 StgSysOtptStat 1;
BA_REL_ "GenSigRxStartValue" BU_SG_REL_ EOCM2cp_K1_PHS SG_ 341 StgSysOtptStat "0";
BA_REL_ "GenSigSuprvResp" BU_SG_REL_ EOCM2cp_K1_PHS SG_ 341 StgSysOtptStat 1;
BA_REL_ "GenSigTimeoutMsg" BU_SG_REL_ EOCM2cp_K1_PHS SG_ 341 StgSysOtptStat 341;
BA_REL_ "GenSigTimeoutTime" BU_SG_REL_ EOCM2cp_K1_PHS SG_ 341 StgSysOtptStat 25;
BA_REL_ "GenSigRxStartValue" BU_SG_REL_ CMMb_PHS SG_ 341 StgOtptTempLmtgSte "Unknown";
BA_REL_ "GenSigSuprvResp" BU_SG_REL_ CMMb_PHS SG_ 341 StgOtptTempLmtgSte 1;
BA_REL_ "GenSigTimeoutMsg" BU_SG_REL_ CMMb_PHS SG_ 341 StgOtptTempLmtgSte 341;
BA_REL_ "GenSigTimeoutTime" BU_SG_REL_ CMMb_PHS SG_ 341 StgOtptTempLmtgSte 30;
BA_REL_ "GenSigRxStartValue" BU_SG_REL_ CMMa_PHS SG_ 341 StgOtptTempLmtgSte "Unknown";
BA_REL_ "GenSigSuprvResp" BU_SG_REL_ CMMa_PHS SG_ 341 StgOtptTempLmtgSte 1;
BA_REL_ "GenSigTimeoutMsg" BU_SG_REL_ CMMa_PHS SG_ 341 StgOtptTempLmtgSte 341;
BA_REL_ "GenSigTimeoutTime" BU_SG_REL_ CMMa_PHS SG_ 341 StgOtptTempLmtgSte 30;
BA_REL_ "GenSigRxStartValue" BU_SG_REL_ ADIMb_PHS SG_ 341 StgOtptTempLmtgSte "0";
BA_REL_ "GenSigSuprvResp" BU_SG_REL_ ADIMb_PHS SG_ 341 StgOtptTempLmtgSte 1;
BA_REL_ "GenSigTimeoutMsg" BU_SG_REL_ ADIMb_PHS SG_ 341 StgOtptTempLmtgSte 341;
BA_REL_ "GenSigTimeoutTime" BU_SG_REL_ ADIMb_PHS SG_ 341 StgOtptTempLmtgSte 25;
BA_REL_ "GenSigRxStartValue" BU_SG_REL_ EOCM2cp_K1_PHS SG_ 341 StgOtptTempLmtgSte "0";
BA_REL_ "GenSigSuprvResp" BU_SG_REL_ EOCM2cp_K1_PHS SG_ 341 StgOtptTempLmtgSte 1;
BA_REL_ "GenSigTimeoutMsg" BU_SG_REL_ EOCM2cp_K1_PHS SG_ 341 StgOtptTempLmtgSte 341;
BA_REL_ "GenSigTimeoutTime" BU_SG_REL_ EOCM2cp_K1_PHS SG_ 341 StgOtptTempLmtgSte 25;
BA_REL_ "GenSigRxStartValue" BU_SG_REL_ CMMb_PHS SG_ 341 StgAngRtLmtV "Valid";
BA_REL_ "GenSigRxStartValue" BU_SG_REL_ CMMa_PHS SG_ 341 StgAngRtLmtV "Valid";
BA_REL_ "GenSigRxStartValue" BU_SG_REL_ ADIMb_PHS SG_ 341 StgAngRtLmtV "Valid";
BA_REL_ "GenSigSuprvResp" BU_SG_REL_ ADIMb_PHS SG_ 341 StgAngRtLmtV 1;
BA_REL_ "GenSigTimeoutMsg" BU_SG_REL_ ADIMb_PHS SG_ 341 StgAngRtLmtV 341;
BA_REL_ "GenSigTimeoutTime" BU_SG_REL_ ADIMb_PHS SG_ 341 StgAngRtLmtV 25;
BA_REL_ "GenSigRxStartValue" BU_SG_REL_ EOCM2cp_K1_PHS SG_ 341 StgAngRtLmtV "Valid";
BA_REL_ "GenSigSuprvResp" BU_SG_REL_ EOCM2cp_K1_PHS SG_ 341 StgAngRtLmtV 1;
BA_REL_ "GenSigTimeoutMsg" BU_SG_REL_ EOCM2cp_K1_PHS SG_ 341 StgAngRtLmtV 341;
BA_REL_ "GenSigTimeoutTime" BU_SG_REL_ EOCM2cp_K1_PHS SG_ 341 StgAngRtLmtV 25;
BA_REL_ "GenSigRxStartValue" BU_SG_REL_ CMMb_PHS SG_ 341 StgAngRtLmt "0";
BA_REL_ "GenSigSuprvResp" BU_SG_REL_ CMMb_PHS SG_ 341 StgAngRtLmt 1;
BA_REL_ "GenSigTimeoutMsg" BU_SG_REL_ CMMb_PHS SG_ 341 StgAngRtLmt 341;
BA_REL_ "GenSigTimeoutTime" BU_SG_REL_ CMMb_PHS SG_ 341 StgAngRtLmt 30;
BA_REL_ "GenSigRxStartValue" BU_SG_REL_ CMMa_PHS SG_ 341 StgAngRtLmt "0";
BA_REL_ "GenSigSuprvResp" BU_SG_REL_ CMMa_PHS SG_ 341 StgAngRtLmt 1;
BA_REL_ "GenSigTimeoutMsg" BU_SG_REL_ CMMa_PHS SG_ 341 StgAngRtLmt 341;
BA_REL_ "GenSigTimeoutTime" BU_SG_REL_ CMMa_PHS SG_ 341 StgAngRtLmt 30;
BA_REL_ "GenSigRxStartValue" BU_SG_REL_ ADIMb_PHS SG_ 341 StgAngRtLmt "0";
BA_REL_ "GenSigSuprvResp" BU_SG_REL_ ADIMb_PHS SG_ 341 StgAngRtLmt 1;
BA_REL_ "GenSigTimeoutMsg" BU_SG_REL_ ADIMb_PHS SG_ 341 StgAngRtLmt 341;
BA_REL_ "GenSigTimeoutTime" BU_SG_REL_ ADIMb_PHS SG_ 341 StgAngRtLmt 25;
BA_REL_ "GenSigVBitResp" BU_SG_REL_ EOCM2cp_K1_PHS SG_ 341 StgAngRtLmt 1;
BA_REL_ "GenSigRxStartValue" BU_SG_REL_ EOCM2cp_K1_PHS SG_ 341 StgAngRtLmt "0";
BA_REL_ "GenSigSuprvResp" BU_SG_REL_ EOCM2cp_K1_PHS SG_ 341 StgAngRtLmt 1;
BA_REL_ "GenSigTimeoutMsg" BU_SG_REL_ EOCM2cp_K1_PHS SG_ 341 StgAngRtLmt 341;
BA_REL_ "GenSigTimeoutTime" BU_SG_REL_ EOCM2cp_K1_PHS SG_ 341 StgAngRtLmt 25;
BA_REL_ "GenSigRxStartValue" BU_SG_REL_ CMMb_PHS SG_ 341 AutoStrgCmndStat "Unknown";
BA_REL_ "GenSigSuprvResp" BU_SG_REL_ CMMb_PHS SG_ 341 AutoStrgCmndStat 1;
BA_REL_ "GenSigTimeoutMsg" BU_SG_REL_ CMMb_PHS SG_ 341 AutoStrgCmndStat 341;
BA_REL_ "GenSigTimeoutTime" BU_SG_REL_ CMMb_PHS SG_ 341 AutoStrgCmndStat 30;
BA_REL_ "GenSigRxStartValue" BU_SG_REL_ CMMa_PHS SG_ 341 AutoStrgCmndStat "Unknown";
BA_REL_ "GenSigSuprvResp" BU_SG_REL_ CMMa_PHS SG_ 341 AutoStrgCmndStat 1;
BA_REL_ "GenSigTimeoutMsg" BU_SG_REL_ CMMa_PHS SG_ 341 AutoStrgCmndStat 341;
BA_REL_ "GenSigTimeoutTime" BU_SG_REL_ CMMa_PHS SG_ 341 AutoStrgCmndStat 30;
BA_REL_ "GenSigRxStartValue" BU_SG_REL_ ADIMb_PHS SG_ 341 AutoStrgCmndStat "0";
BA_REL_ "GenSigSuprvResp" BU_SG_REL_ ADIMb_PHS SG_ 341 AutoStrgCmndStat 1;
BA_REL_ "GenSigTimeoutMsg" BU_SG_REL_ ADIMb_PHS SG_ 341 AutoStrgCmndStat 341;
BA_REL_ "GenSigTimeoutTime" BU_SG_REL_ ADIMb_PHS SG_ 341 AutoStrgCmndStat 25;
BA_REL_ "GenSigVBitResp" BU_SG_REL_ EOCM2cp_K1_PHS SG_ 341 AutoStrgCmndStat 1;
BA_REL_ "GenSigRxStartValue" BU_SG_REL_ EOCM2cp_K1_PHS SG_ 341 AutoStrgCmndStat "0";
BA_REL_ "GenSigSuprvResp" BU_SG_REL_ EOCM2cp_K1_PHS SG_ 341 AutoStrgCmndStat 1;
BA_REL_ "GenSigTimeoutMsg" BU_SG_REL_ EOCM2cp_K1_PHS SG_ 341 AutoStrgCmndStat 341;
BA_REL_ "GenSigTimeoutTime" BU_SG_REL_ EOCM2cp_K1_PHS SG_ 341 AutoStrgCmndStat 25;
BA_REL_ "GenSigRxStartValue" BU_SG_REL_ CMMb_PHS SG_ 341 AutoStgStatChksm "0";
BA_REL_ "GenSigRxStartValue" BU_SG_REL_ CMMa_PHS SG_ 341 AutoStgStatChksm "0";
BA_REL_ "GenSigRxStartValue" BU_SG_REL_ ADIMb_PHS SG_ 341 AutoStgStatChksm "0";
BA_REL_ "GenSigRxStartValue" BU_SG_REL_ EOCM2cp_K1_PHS SG_ 341 AutoStgStatChksm "0";
BA_REL_ "GenSigRxStartValue" BU_SG_REL_ CMMb_PHS SG_ 341 AutoStgStatARC "0";
BA_REL_ "GenSigRxStartValue" BU_SG_REL_ CMMa_PHS SG_ 341 AutoStgStatARC "0";
BA_REL_ "GenSigRxStartValue" BU_SG_REL_ ADIMb_PHS SG_ 341 AutoStgStatARC "0";
BA_REL_ "GenSigRxStartValue" BU_SG_REL_ EOCM2cp_K1_PHS SG_ 341 AutoStgStatARC "0";
BA_REL_ "GenSigRxStartValue" BU_SG_REL_ CMMb_PHS SG_ 341 StgOvrdDetn "Initialization";
BA_REL_ "GenSigSuprvResp" BU_SG_REL_ CMMb_PHS SG_ 341 StgOvrdDetn 1;
BA_REL_ "GenSigTimeoutMsg" BU_SG_REL_ CMMb_PHS SG_ 341 StgOvrdDetn 341;
BA_REL_ "GenSigTimeoutTime" BU_SG_REL_ CMMb_PHS SG_ 341 StgOvrdDetn 30;
BA_REL_ "GenSigRxStartValue" BU_SG_REL_ CMMa_PHS SG_ 341 StgOvrdDetn "Initialization";
BA_REL_ "GenSigSuprvResp" BU_SG_REL_ CMMa_PHS SG_ 341 StgOvrdDetn 1;
BA_REL_ "GenSigTimeoutMsg" BU_SG_REL_ CMMa_PHS SG_ 341 StgOvrdDetn 341;
BA_REL_ "GenSigTimeoutTime" BU_SG_REL_ CMMa_PHS SG_ 341 StgOvrdDetn 30;
BA_REL_ "GenSigRxStartValue" BU_SG_REL_ EOCM2cp_K1_PHS SG_ 341 StgOvrdDetn "Initialization";
BA_REL_ "GenSigSuprvResp" BU_SG_REL_ EOCM2cp_K1_PHS SG_ 341 StgOvrdDetn 1;
BA_REL_ "GenSigTimeoutMsg" BU_SG_REL_ EOCM2cp_K1_PHS SG_ 341 StgOvrdDetn 341;
BA_REL_ "GenSigTimeoutTime" BU_SG_REL_ EOCM2cp_K1_PHS SG_ 341 StgOvrdDetn 25;
BA_REL_ "GenSigRxStartValue" BU_SG_REL_ ADIMb_PHS SG_ 341 StgOvrdDetn "Initialization";
BA_REL_ "GenSigSuprvResp" BU_SG_REL_ ADIMb_PHS SG_ 341 StgOvrdDetn 1;
BA_REL_ "GenSigTimeoutMsg" BU_SG_REL_ ADIMb_PHS SG_ 341 StgOvrdDetn 341;
BA_REL_ "GenSigTimeoutTime" BU_SG_REL_ ADIMb_PHS SG_ 341 StgOvrdDetn 25;
BA_REL_ "GenSigRxStartValue" BU_SG_REL_ EBOOST_OBD_PHS SG_ 341 StgOvrdDetn "Initialization";
BA_REL_ "GenSigSuprvResp" BU_SG_REL_ EBOOST_OBD_PHS SG_ 341 StgOvrdDetn 1;
BA_REL_ "GenSigTimeoutMsg" BU_SG_REL_ EBOOST_OBD_PHS SG_ 341 StgOvrdDetn 341;
BA_REL_ "GenSigTimeoutTime" BU_SG_REL_ EBOOST_OBD_PHS SG_ 341 StgOvrdDetn 25;
BA_REL_ "GenSigRxStartValue" BU_SG_REL_ EBCM_PHS SG_ 341 StgOvrdDetn "Initialization";
BA_REL_ "GenSigSuprvResp" BU_SG_REL_ EBCM_PHS SG_ 341 StgOvrdDetn 1;
BA_REL_ "GenSigTimeoutMsg" BU_SG_REL_ EBCM_PHS SG_ 341 StgOvrdDetn 341;
BA_REL_ "GenSigTimeoutTime" BU_SG_REL_ EBCM_PHS SG_ 341 StgOvrdDetn 25;
BA_REL_ "GenSigVBitResp" BU_SG_REL_ EOCM2cp_IMX6_PHS SG_ 313 DrDoorOpenSwAct 1;
BA_REL_ "GenSigSuprvResp" BU_SG_REL_ EBCM_PHS SG_ 313 LnchCtrlWhlSlpReq 1;
BA_REL_ "GenSigTimeoutMsg" BU_SG_REL_ EBCM_PHS SG_ 313 LnchCtrlWhlSlpReq 313;
BA_REL_ "GenSigTimeoutTime" BU_SG_REL_ EBCM_PHS SG_ 313 LnchCtrlWhlSlpReq 250;
BA_REL_ "GenSigSuprvResp" BU_SG_REL_ EBCM_PHS SG_ 313 LnchCtrlMdReq 1;
BA_REL_ "GenSigTimeoutMsg" BU_SG_REL_ EBCM_PHS SG_ 313 LnchCtrlMdReq 313;
BA_REL_ "GenSigTimeoutTime" BU_SG_REL_ EBCM_PHS SG_ 313 LnchCtrlMdReq 250;
BA_REL_ "GenSigSuprvResp" BU_SG_REL_ EBCM_PHS SG_ 313 LnchCtrlEngRPMReq 1;
BA_REL_ "GenSigTimeoutMsg" BU_SG_REL_ EBCM_PHS SG_ 313 LnchCtrlEngRPMReq 313;
BA_REL_ "GenSigTimeoutTime" BU_SG_REL_ EBCM_PHS SG_ 313 LnchCtrlEngRPMReq 250;
BA_REL_ "GenSigSuprvResp" BU_SG_REL_ EBCM_PHS SG_ 313 ExtHlStrAssCsStRq 1;
BA_REL_ "GenSigTimeoutMsg" BU_SG_REL_ EBCM_PHS SG_ 313 ExtHlStrAssCsStRq 313;
BA_REL_ "GenSigTimeoutTime" BU_SG_REL_ EBCM_PHS SG_ 313 ExtHlStrAssCsStRq 250;
BA_REL_ "GenSigSuprvResp" BU_SG_REL_ EBCM_PHS SG_ 313 DrvStyPerfMdCsStReq 1;
BA_REL_ "GenSigTimeoutMsg" BU_SG_REL_ EBCM_PHS SG_ 313 DrvStyPerfMdCsStReq 313;
BA_REL_ "GenSigTimeoutTime" BU_SG_REL_ EBCM_PHS SG_ 313 DrvStyPerfMdCsStReq 250;
BA_REL_ "GenSigSuprvResp" BU_SG_REL_ EBCM_PHS SG_ 313 PsngStPerfMdCsStReq 1;
BA_REL_ "GenSigTimeoutMsg" BU_SG_REL_ EBCM_PHS SG_ 313 PsngStPerfMdCsStReq 313;
BA_REL_ "GenSigTimeoutTime" BU_SG_REL_ EBCM_PHS SG_ 313 PsngStPerfMdCsStReq 250;
BA_REL_ "GenSigSuprvResp" BU_SG_REL_ EBCM_PHS SG_ 313 DrvrStPerfMdCsStReq 1;
BA_REL_ "GenSigTimeoutMsg" BU_SG_REL_ EBCM_PHS SG_ 313 DrvrStPerfMdCsStReq 313;
BA_REL_ "GenSigTimeoutTime" BU_SG_REL_ EBCM_PHS SG_ 313 DrvrStPerfMdCsStReq 250;
BA_REL_ "GenSigSuprvResp" BU_SG_REL_ EBCM_PHS SG_ 313 ACCPerfMdCsStReq 1;
BA_REL_ "GenSigTimeoutMsg" BU_SG_REL_ EBCM_PHS SG_ 313 ACCPerfMdCsStReq 313;
BA_REL_ "GenSigTimeoutTime" BU_SG_REL_ EBCM_PHS SG_ 313 ACCPerfMdCsStReq 250;
BA_REL_ "GenSigSuprvResp" BU_SG_REL_ EBCM_PHS SG_ 313 SndPerfMdCsStRq 1;
BA_REL_ "GenSigTimeoutMsg" BU_SG_REL_ EBCM_PHS SG_ 313 SndPerfMdCsStRq 313;
BA_REL_ "GenSigTimeoutTime" BU_SG_REL_ EBCM_PHS SG_ 313 SndPerfMdCsStRq 250;
BA_REL_ "GenSigSuprvResp" BU_SG_REL_ EBCM_PHS SG_ 313 FCABrkPrflReq 1;
BA_REL_ "GenSigTimeoutMsg" BU_SG_REL_ EBCM_PHS SG_ 313 FCABrkPrflReq 313;
BA_REL_ "GenSigTimeoutTime" BU_SG_REL_ EBCM_PHS SG_ 313 FCABrkPrflReq 250;
BA_REL_ "GenSigSuprvResp" BU_SG_REL_ EBCM_PHS SG_ 313 DispPerfMdCsStRq 1;
BA_REL_ "GenSigTimeoutMsg" BU_SG_REL_ EBCM_PHS SG_ 313 DispPerfMdCsStRq 313;
BA_REL_ "GenSigTimeoutTime" BU_SG_REL_ EBCM_PHS SG_ 313 DispPerfMdCsStRq 250;
BA_REL_ "GenSigSuprvResp" BU_SG_REL_ EBCM_PHS SG_ 1275 EBrkAstStat 1;
BA_REL_ "GenSigTimeoutMsg" BU_SG_REL_ EBCM_PHS SG_ 1275 EBrkAstStat 1275;
BA_REL_ "GenSigTimeoutTime" BU_SG_REL_ EBCM_PHS SG_ 1275 EBrkAstStat 1250;
BA_REL_ "GenSigVBitResp" BU_SG_REL_ EOCM2cp_IMX6_PHS SG_ 381 ActVehAccel 1;
BA_REL_ "GenSigRxStartValue" BU_SG_REL_ CMMb_PHS SG_ 485 StrAngSnsChksm "0";
BA_REL_ "GenSigRxStartValue" BU_SG_REL_ CMMa_PHS SG_ 485 StrAngSnsChksm "0";
BA_REL_ "GenSigRxStartValue" BU_SG_REL_ CMMb_PHS SG_ 485 StrWhAngGrdV "Valid";
BA_REL_ "GenSigRxStartValue" BU_SG_REL_ CMMa_PHS SG_ 485 StrWhAngGrdV "Valid";
BA_REL_ "GenSigRxStartValue" BU_SG_REL_ CMMb_PHS SG_ 485 StrWhAngGrdMsk "Don't Use Data";
BA_REL_ "GenSigRxStartValue" BU_SG_REL_ CMMa_PHS SG_ 485 StrWhAngGrdMsk "Don't Use Data";
BA_REL_ "GenSigRxStartValue" BU_SG_REL_ CMMb_PHS SG_ 485 StrWhAngMsk "Don't Use Data";
BA_REL_ "GenSigRxStartValue" BU_SG_REL_ CMMa_PHS SG_ 485 StrWhAngMsk "Don't Use Data";
BA_REL_ "GenSigRxStartValue" BU_SG_REL_ CMMb_PHS SG_ 485 StrWhlAngSenTyp "Type 1";
BA_REL_ "GenSigSuprvResp" BU_SG_REL_ CMMb_PHS SG_ 485 StrWhlAngSenTyp 1;
BA_REL_ "GenSigTimeoutMsg" BU_SG_REL_ CMMb_PHS SG_ 485 StrWhlAngSenTyp 485;
BA_REL_ "GenSigTimeoutTime" BU_SG_REL_ CMMb_PHS SG_ 485 StrWhlAngSenTyp 30;
BA_REL_ "GenSigRxStartValue" BU_SG_REL_ CMMa_PHS SG_ 485 StrWhlAngSenTyp "Type 1";
BA_REL_ "GenSigSuprvResp" BU_SG_REL_ CMMa_PHS SG_ 485 StrWhlAngSenTyp 1;
BA_REL_ "GenSigTimeoutMsg" BU_SG_REL_ CMMa_PHS SG_ 485 StrWhlAngSenTyp 485;
BA_REL_ "GenSigTimeoutTime" BU_SG_REL_ CMMa_PHS SG_ 485 StrWhlAngSenTyp 30;
BA_REL_ "GenSigRxStartValue" BU_SG_REL_ CMMb_PHS SG_ 485 StrWhlAngSenCalStat "Unknown";
BA_REL_ "GenSigSuprvResp" BU_SG_REL_ CMMb_PHS SG_ 485 StrWhlAngSenCalStat 1;
BA_REL_ "GenSigTimeoutMsg" BU_SG_REL_ CMMb_PHS SG_ 485 StrWhlAngSenCalStat 485;
BA_REL_ "GenSigTimeoutTime" BU_SG_REL_ CMMb_PHS SG_ 485 StrWhlAngSenCalStat 30;
BA_REL_ "GenSigRxStartValue" BU_SG_REL_ CMMa_PHS SG_ 485 StrWhlAngSenCalStat "Unknown";
BA_REL_ "GenSigSuprvResp" BU_SG_REL_ CMMa_PHS SG_ 485 StrWhlAngSenCalStat 1;
BA_REL_ "GenSigTimeoutMsg" BU_SG_REL_ CMMa_PHS SG_ 485 StrWhlAngSenCalStat 485;
BA_REL_ "GenSigTimeoutTime" BU_SG_REL_ CMMa_PHS SG_ 485 StrWhlAngSenCalStat 30;
BA_REL_ "GenSigRxStartValue" BU_SG_REL_ CMMb_PHS SG_ 485 StrWhAngGrd "0";
BA_REL_ "GenSigSuprvResp" BU_SG_REL_ CMMb_PHS SG_ 485 StrWhAngGrd 1;
BA_REL_ "GenSigTimeoutMsg" BU_SG_REL_ CMMb_PHS SG_ 485 StrWhAngGrd 485;
BA_REL_ "GenSigTimeoutTime" BU_SG_REL_ CMMb_PHS SG_ 485 StrWhAngGrd 30;
BA_REL_ "GenSigRxStartValue" BU_SG_REL_ CMMa_PHS SG_ 485 StrWhAngGrd "0";
BA_REL_ "GenSigSuprvResp" BU_SG_REL_ CMMa_PHS SG_ 485 StrWhAngGrd 1;
BA_REL_ "GenSigTimeoutMsg" BU_SG_REL_ CMMa_PHS SG_ 485 StrWhAngGrd 485;
BA_REL_ "GenSigTimeoutTime" BU_SG_REL_ CMMa_PHS SG_ 485 StrWhAngGrd 30;
BA_REL_ "GenSigRxStartValue" BU_SG_REL_ CMMb_PHS SG_ 485 StWhlAngAliveRollCnt "0";
BA_REL_ "GenSigRxStartValue" BU_SG_REL_ CMMa_PHS SG_ 485 StWhlAngAliveRollCnt "0";
BA_REL_ "GenSigRxStartValue" BU_SG_REL_ CMMb_PHS SG_ 485 StrWhAngV "Valid";
BA_REL_ "GenSigRxStartValue" BU_SG_REL_ CMMa_PHS SG_ 485 StrWhAngV "Valid";
BA_REL_ "GenSigRxStartValue" BU_SG_REL_ CMMb_PHS SG_ 485 StrWhAng "0";
BA_REL_ "GenSigSuprvResp" BU_SG_REL_ CMMb_PHS SG_ 485 StrWhAng 1;
BA_REL_ "GenSigTimeoutMsg" BU_SG_REL_ CMMb_PHS SG_ 485 StrWhAng 485;
BA_REL_ "GenSigTimeoutTime" BU_SG_REL_ CMMb_PHS SG_ 485 StrWhAng 30;
BA_REL_ "GenSigRxStartValue" BU_SG_REL_ CMMa_PHS SG_ 485 StrWhAng "0";
BA_REL_ "GenSigSuprvResp" BU_SG_REL_ CMMa_PHS SG_ 485 StrWhAng 1;
BA_REL_ "GenSigTimeoutMsg" BU_SG_REL_ CMMa_PHS SG_ 485 StrWhAng 485;
BA_REL_ "GenSigTimeoutTime" BU_SG_REL_ CMMa_PHS SG_ 485 StrWhAng 30;
BA_REL_ "GenSigVBitResp" BU_SG_REL_ EBCM_PHS SG_ 485 StrWhAng 1;
BA_REL_ "GenSigSuprvResp" BU_SG_REL_ EBCM_PHS SG_ 485 StrWhAng 1;
BA_REL_ "GenSigTimeoutMsg" BU_SG_REL_ EBCM_PHS SG_ 485 StrWhAng 485;
BA_REL_ "GenSigTimeoutTime" BU_SG_REL_ EBCM_PHS SG_ 485 StrWhAng 100;
BA_REL_ "GenSigVBitResp" BU_SG_REL_ EOCM2cp_K1_PHS SG_ 489 VehDynOvrUndrStr 1;
BA_REL_ "GenSigRxStartValue" BU_SG_REL_ EPSb_PHS SG_ 489 VSELatAccV "Valid";
BA_REL_ "GenSigRxStartValue" BU_SG_REL_ EPSa_PHS SG_ 489 VSELatAccV "Valid";
BA_REL_ "GenSigVBitResp" BU_SG_REL_ EPSb_PHS SG_ 489 VSELatAcc 1;
BA_REL_ "GenSigRxStartValue" BU_SG_REL_ EPSb_PHS SG_ 489 VSELatAcc "0";
BA_REL_ "GenSigSuprvResp" BU_SG_REL_ EPSb_PHS SG_ 489 VSELatAcc 1;
BA_REL_ "GenSigTimeoutMsg" BU_SG_REL_ EPSb_PHS SG_ 489 VSELatAcc 489;
BA_REL_ "GenSigTimeoutTime" BU_SG_REL_ EPSb_PHS SG_ 489 VSELatAcc 50;
BA_REL_ "GenSigVBitResp" BU_SG_REL_ EPSa_PHS SG_ 489 VSELatAcc 1;
BA_REL_ "GenSigRxStartValue" BU_SG_REL_ EPSa_PHS SG_ 489 VSELatAcc "0";
BA_REL_ "GenSigSuprvResp" BU_SG_REL_ EPSa_PHS SG_ 489 VSELatAcc 1;
BA_REL_ "GenSigTimeoutMsg" BU_SG_REL_ EPSa_PHS SG_ 489 VSELatAcc 489;
BA_REL_ "GenSigTimeoutTime" BU_SG_REL_ EPSa_PHS SG_ 489 VSELatAcc 50;
BA_REL_ "GenSigVBitResp" BU_SG_REL_ EOCM2cp_K1_PHS SG_ 489 VSELatAcc 1;
BA_REL_ "GenSigVBitResp" BU_SG_REL_ EOCM2cp_K1_PHS SG_ 489 VehDynYawRate 1;
BA_REL_ "GenSigVBitResp" BU_SG_REL_ EOCM2cp_K1_PHS SG_ 489 BrkPdlDrvAppPrsDetcd 1;
BA_REL_ "GenSigRxStartValue" BU_SG_REL_ ADIMb_PHS SG_ 305 PriAutoArbBrkTrqReqRed "0";
BA_REL_ "GenSigSuprvResp" BU_SG_REL_ ADIMb_PHS SG_ 305 PriAutoArbBrkTrqReqRed 1;
BA_REL_ "GenSigTimeoutMsg" BU_SG_REL_ ADIMb_PHS SG_ 305 PriAutoArbBrkTrqReqRed 305;
BA_REL_ "GenSigTimeoutTime" BU_SG_REL_ ADIMb_PHS SG_ 305 PriAutoArbBrkTrqReqRed 25;
BA_REL_ "GenSigRxStartValue" BU_SG_REL_ ADIMb_PHS SG_ 305 PriBrkModStatRed "0";
BA_REL_ "GenSigSuprvResp" BU_SG_REL_ ADIMb_PHS SG_ 305 PriBrkModStatRed 1;
BA_REL_ "GenSigTimeoutMsg" BU_SG_REL_ ADIMb_PHS SG_ 305 PriBrkModStatRed 305;
BA_REL_ "GenSigTimeoutTime" BU_SG_REL_ ADIMb_PHS SG_ 305 PriBrkModStatRed 25;
BA_REL_ "GenSigRxStartValue" BU_SG_REL_ ADIMb_PHS SG_ 305 PriAutoEstBrkTrqAppStatRed "0";
BA_REL_ "GenSigSuprvResp" BU_SG_REL_ ADIMb_PHS SG_ 305 PriAutoEstBrkTrqAppStatRed 1;
BA_REL_ "GenSigTimeoutMsg" BU_SG_REL_ ADIMb_PHS SG_ 305 PriAutoEstBrkTrqAppStatRed 305;
BA_REL_ "GenSigTimeoutTime" BU_SG_REL_ ADIMb_PHS SG_ 305 PriAutoEstBrkTrqAppStatRed 25;
BA_REL_ "GenSigRxStartValue" BU_SG_REL_ ADIMb_PHS SG_ 305 PriAutoEstBrkTrqApdRed "0";
BA_REL_ "GenSigSuprvResp" BU_SG_REL_ ADIMb_PHS SG_ 305 PriAutoEstBrkTrqApdRed 1;
BA_REL_ "GenSigTimeoutMsg" BU_SG_REL_ ADIMb_PHS SG_ 305 PriAutoEstBrkTrqApdRed 305;
BA_REL_ "GenSigTimeoutTime" BU_SG_REL_ ADIMb_PHS SG_ 305 PriAutoEstBrkTrqApdRed 25;
BA_REL_ "GenSigRxStartValue" BU_SG_REL_ EBOOST_OBD_PHS SG_ 305 PriAutoBrkSysDrInfcStatRed "Unknown";
BA_REL_ "GenSigSuprvResp" BU_SG_REL_ EBOOST_OBD_PHS SG_ 305 PriAutoBrkSysDrInfcStatRed 1;
BA_REL_ "GenSigTimeoutMsg" BU_SG_REL_ EBOOST_OBD_PHS SG_ 305 PriAutoBrkSysDrInfcStatRed 305;
BA_REL_ "GenSigTimeoutTime" BU_SG_REL_ EBOOST_OBD_PHS SG_ 305 PriAutoBrkSysDrInfcStatRed 25;
BA_REL_ "GenSigRxStartValue" BU_SG_REL_ ADIMb_PHS SG_ 305 PriAutoBrkSysDrInfcStatRed "0";
BA_REL_ "GenSigSuprvResp" BU_SG_REL_ ADIMb_PHS SG_ 305 PriAutoBrkSysDrInfcStatRed 1;
BA_REL_ "GenSigTimeoutMsg" BU_SG_REL_ ADIMb_PHS SG_ 305 PriAutoBrkSysDrInfcStatRed 305;
BA_REL_ "GenSigTimeoutTime" BU_SG_REL_ ADIMb_PHS SG_ 305 PriAutoBrkSysDrInfcStatRed 25;
BA_REL_ "GenSigRxStartValue" BU_SG_REL_ ADIMb_PHS SG_ 305 PriAutoAxlTrqReqStatRedChksm "0";
BA_REL_ "GenSigSuprvResp" BU_SG_REL_ EBOOST_OBD_PHS SG_ 305 MstCylPrsCrct1Stat 1;
BA_REL_ "GenSigTimeoutMsg" BU_SG_REL_ EBOOST_OBD_PHS SG_ 305 MstCylPrsCrct1Stat 305;
BA_REL_ "GenSigTimeoutTime" BU_SG_REL_ EBOOST_OBD_PHS SG_ 305 MstCylPrsCrct1Stat 25;
BA_REL_ "GenSigSuprvResp" BU_SG_REL_ EBOOST_OBD_PHS SG_ 305 MstCylPrsCrct1 1;
BA_REL_ "GenSigTimeoutMsg" BU_SG_REL_ EBOOST_OBD_PHS SG_ 305 MstCylPrsCrct1 305;
BA_REL_ "GenSigTimeoutTime" BU_SG_REL_ EBOOST_OBD_PHS SG_ 305 MstCylPrsCrct1 25;
BA_REL_ "GenSigRxStartValue" BU_SG_REL_ ADIMb_PHS SG_ 305 PriAutoAxlTrqReqStatRedARC "0";
BA_REL_ "GenSigRxStartValue" BU_SG_REL_ ADIMb_PHS SG_ 305 PriSuffBrkTrqStdstlRed "False";
BA_REL_ "GenSigSuprvResp" BU_SG_REL_ ADIMb_PHS SG_ 305 PriSuffBrkTrqStdstlRed 1;
BA_REL_ "GenSigTimeoutMsg" BU_SG_REL_ ADIMb_PHS SG_ 305 PriSuffBrkTrqStdstlRed 305;
BA_REL_ "GenSigTimeoutTime" BU_SG_REL_ ADIMb_PHS SG_ 305 PriSuffBrkTrqStdstlRed 25;
BA_REL_ "GenSigVBitResp" BU_SG_REL_ EBCM_PHS SG_ 1020 EngInltSpcfcHmdty 1;
BA_REL_ "GenSigSuprvResp" BU_SG_REL_ EBCM_PHS SG_ 1020 EngInltSpcfcHmdty 1;
BA_REL_ "GenSigTimeoutMsg" BU_SG_REL_ EBCM_PHS SG_ 1020 EngInltSpcfcHmdty 1020;
BA_REL_ "GenSigTimeoutTime" BU_SG_REL_ EBCM_PHS SG_ 1020 EngInltSpcfcHmdty 625;
BA_REL_ "GenSigRxStartValue" BU_SG_REL_ EBOOST_OBD_PHS SG_ 338 CoPRVBAtv "False";
BA_REL_ "GenSigSuprvResp" BU_SG_REL_ EBOOST_OBD_PHS SG_ 338 CoPRVBAtv 1;
BA_REL_ "GenSigTimeoutMsg" BU_SG_REL_ EBOOST_OBD_PHS SG_ 338 CoPRVBAtv 338;
BA_REL_ "GenSigTimeoutTime" BU_SG_REL_ EBOOST_OBD_PHS SG_ 338 CoPRVBAtv 25;
BA_REL_ "GenSigRxStartValue" BU_SG_REL_ EBCM_PHS SG_ 338 CoPRVBAtv "False";
BA_REL_ "GenSigSuprvResp" BU_SG_REL_ EBCM_PHS SG_ 338 CoPRVBAtv 1;
BA_REL_ "GenSigTimeoutMsg" BU_SG_REL_ EBCM_PHS SG_ 338 CoPRVBAtv 338;
BA_REL_ "GenSigTimeoutTime" BU_SG_REL_ EBCM_PHS SG_ 338 CoPRVBAtv 25;
BA_REL_ "GenSigRxStartValue" BU_SG_REL_ EBOOST_OBD_PHS SG_ 338 CoPCIBAtv "False";
BA_REL_ "GenSigSuprvResp" BU_SG_REL_ EBOOST_OBD_PHS SG_ 338 CoPCIBAtv 1;
BA_REL_ "GenSigTimeoutMsg" BU_SG_REL_ EBOOST_OBD_PHS SG_ 338 CoPCIBAtv 338;
BA_REL_ "GenSigTimeoutTime" BU_SG_REL_ EBOOST_OBD_PHS SG_ 338 CoPCIBAtv 25;
BA_REL_ "GenSigRxStartValue" BU_SG_REL_ EBCM_PHS SG_ 338 CoPCIBAtv "False";
BA_REL_ "GenSigSuprvResp" BU_SG_REL_ EBCM_PHS SG_ 338 CoPCIBAtv 1;
BA_REL_ "GenSigTimeoutMsg" BU_SG_REL_ EBCM_PHS SG_ 338 CoPCIBAtv 338;
BA_REL_ "GenSigTimeoutTime" BU_SG_REL_ EBCM_PHS SG_ 338 CoPCIBAtv 25;
BA_REL_ "GenSigRxStartValue" BU_SG_REL_ EBOOST_OBD_PHS SG_ 338 CPEPSWAR_TrgtAng "0";
BA_REL_ "GenSigSuprvResp" BU_SG_REL_ EBOOST_OBD_PHS SG_ 338 CPEPSWAR_TrgtAng 1;
BA_REL_ "GenSigTimeoutMsg" BU_SG_REL_ EBOOST_OBD_PHS SG_ 338 CPEPSWAR_TrgtAng 338;
BA_REL_ "GenSigTimeoutTime" BU_SG_REL_ EBOOST_OBD_PHS SG_ 338 CPEPSWAR_TrgtAng 25;
BA_REL_ "GenSigRxStartValue" BU_SG_REL_ EBCM_PHS SG_ 338 CPEPSWAR_TrgtAng "0";
BA_REL_ "GenSigSuprvResp" BU_SG_REL_ EBCM_PHS SG_ 338 CPEPSWAR_TrgtAng 1;
BA_REL_ "GenSigTimeoutMsg" BU_SG_REL_ EBCM_PHS SG_ 338 CPEPSWAR_TrgtAng 338;
BA_REL_ "GenSigTimeoutTime" BU_SG_REL_ EBCM_PHS SG_ 338 CPEPSWAR_TrgtAng 25;
BA_REL_ "GenSigRxStartValue" BU_SG_REL_ EBOOST_OBD_PHS SG_ 338 CPEPSWAR_ReqdState "0";
BA_REL_ "GenSigSuprvResp" BU_SG_REL_ EBOOST_OBD_PHS SG_ 338 CPEPSWAR_ReqdState 1;
BA_REL_ "GenSigTimeoutMsg" BU_SG_REL_ EBOOST_OBD_PHS SG_ 338 CPEPSWAR_ReqdState 338;
BA_REL_ "GenSigTimeoutTime" BU_SG_REL_ EBOOST_OBD_PHS SG_ 338 CPEPSWAR_ReqdState 25;
BA_REL_ "GenSigRxStartValue" BU_SG_REL_ EBCM_PHS SG_ 338 CPEPSWAR_ReqdState "0";
BA_REL_ "GenSigSuprvResp" BU_SG_REL_ EBCM_PHS SG_ 338 CPEPSWAR_ReqdState 1;
BA_REL_ "GenSigTimeoutMsg" BU_SG_REL_ EBCM_PHS SG_ 338 CPEPSWAR_ReqdState 338;
BA_REL_ "GenSigTimeoutTime" BU_SG_REL_ EBCM_PHS SG_ 338 CPEPSWAR_ReqdState 25;
BA_REL_ "GenSigRxStartValue" BU_SG_REL_ EBOOST_OBD_PHS SG_ 338 CoPEPBReq "0";
BA_REL_ "GenSigSuprvResp" BU_SG_REL_ EBOOST_OBD_PHS SG_ 338 CoPEPBReq 1;
BA_REL_ "GenSigTimeoutMsg" BU_SG_REL_ EBOOST_OBD_PHS SG_ 338 CoPEPBReq 338;
BA_REL_ "GenSigTimeoutTime" BU_SG_REL_ EBOOST_OBD_PHS SG_ 338 CoPEPBReq 25;
BA_REL_ "GenSigRxStartValue" BU_SG_REL_ EBCM_PHS SG_ 338 CoPEPBReq "0";
BA_REL_ "GenSigSuprvResp" BU_SG_REL_ EBCM_PHS SG_ 338 CoPEPBReq 1;
BA_REL_ "GenSigTimeoutMsg" BU_SG_REL_ EBCM_PHS SG_ 338 CoPEPBReq 338;
BA_REL_ "GenSigTimeoutTime" BU_SG_REL_ EBCM_PHS SG_ 338 CoPEPBReq 25;
BA_REL_ "GenSigRxStartValue" BU_SG_REL_ EBOOST_OBD_PHS SG_ 338 CoPBaSChksm "0";
BA_REL_ "GenSigRxStartValue" BU_SG_REL_ EBCM_PHS SG_ 338 CoPBaSChksm "0";
BA_REL_ "GenSigRxStartValue" BU_SG_REL_ EBOOST_OBD_PHS SG_ 338 CoPBaSARC "0";
BA_REL_ "GenSigRxStartValue" BU_SG_REL_ EBCM_PHS SG_ 338 CoPBaSARC "0";
BA_REL_ "GenSigRxStartValue" BU_SG_REL_ EBOOST_OBD_PHS SG_ 338 CoPCntrlFail "False";
BA_REL_ "GenSigSuprvResp" BU_SG_REL_ EBOOST_OBD_PHS SG_ 338 CoPCntrlFail 1;
BA_REL_ "GenSigTimeoutMsg" BU_SG_REL_ EBOOST_OBD_PHS SG_ 338 CoPCntrlFail 338;
BA_REL_ "GenSigTimeoutTime" BU_SG_REL_ EBOOST_OBD_PHS SG_ 338 CoPCntrlFail 25;
BA_REL_ "GenSigRxStartValue" BU_SG_REL_ EBCM_PHS SG_ 338 CoPCntrlFail "False";
BA_REL_ "GenSigSuprvResp" BU_SG_REL_ EBCM_PHS SG_ 338 CoPCntrlFail 1;
BA_REL_ "GenSigTimeoutMsg" BU_SG_REL_ EBCM_PHS SG_ 338 CoPCntrlFail 338;
BA_REL_ "GenSigTimeoutTime" BU_SG_REL_ EBCM_PHS SG_ 338 CoPCntrlFail 25;
BA_REL_ "GenSigRxStartValue" BU_SG_REL_ EBOOST_OBD_PHS SG_ 338 CoPAutoBrkTrqReq "0";
BA_REL_ "GenSigSuprvResp" BU_SG_REL_ EBOOST_OBD_PHS SG_ 338 CoPAutoBrkTrqReq 1;
BA_REL_ "GenSigTimeoutMsg" BU_SG_REL_ EBOOST_OBD_PHS SG_ 338 CoPAutoBrkTrqReq 338;
BA_REL_ "GenSigTimeoutTime" BU_SG_REL_ EBOOST_OBD_PHS SG_ 338 CoPAutoBrkTrqReq 25;
BA_REL_ "GenSigRxStartValue" BU_SG_REL_ EBCM_PHS SG_ 338 CoPAutoBrkTrqReq "0";
BA_REL_ "GenSigSuprvResp" BU_SG_REL_ EBCM_PHS SG_ 338 CoPAutoBrkTrqReq 1;
BA_REL_ "GenSigTimeoutMsg" BU_SG_REL_ EBCM_PHS SG_ 338 CoPAutoBrkTrqReq 338;
BA_REL_ "GenSigTimeoutTime" BU_SG_REL_ EBCM_PHS SG_ 338 CoPAutoBrkTrqReq 25;
BA_REL_ "GenSigRxStartValue" BU_SG_REL_ EBOOST_OBD_PHS SG_ 338 CoPAutoBrkReqType "0";
BA_REL_ "GenSigSuprvResp" BU_SG_REL_ EBOOST_OBD_PHS SG_ 338 CoPAutoBrkReqType 1;
BA_REL_ "GenSigTimeoutMsg" BU_SG_REL_ EBOOST_OBD_PHS SG_ 338 CoPAutoBrkReqType 338;
BA_REL_ "GenSigTimeoutTime" BU_SG_REL_ EBOOST_OBD_PHS SG_ 338 CoPAutoBrkReqType 25;
BA_REL_ "GenSigRxStartValue" BU_SG_REL_ EBCM_PHS SG_ 338 CoPAutoBrkReqType "0";
BA_REL_ "GenSigSuprvResp" BU_SG_REL_ EBCM_PHS SG_ 338 CoPAutoBrkReqType 1;
BA_REL_ "GenSigTimeoutMsg" BU_SG_REL_ EBCM_PHS SG_ 338 CoPAutoBrkReqType 338;
BA_REL_ "GenSigTimeoutTime" BU_SG_REL_ EBCM_PHS SG_ 338 CoPAutoBrkReqType 25;
BA_REL_ "GenSigSuprvResp" BU_SG_REL_ EBCM_PHS SG_ 1217 LegPstDTCClrDrvCyCm 1;
BA_REL_ "GenSigTimeoutMsg" BU_SG_REL_ EBCM_PHS SG_ 1217 LegPstDTCClrDrvCyCm 1217;
BA_REL_ "GenSigTimeoutTime" BU_SG_REL_ EBCM_PHS SG_ 1217 LegPstDTCClrDrvCyCm 1250;
BA_REL_ "GenSigSuprvResp" BU_SG_REL_ EBOOST_OBD_PHS SG_ 1217 LegPstDTCClrDrvCyCm 1;
BA_REL_ "GenSigTimeoutMsg" BU_SG_REL_ EBOOST_OBD_PHS SG_ 1217 LegPstDTCClrDrvCyCm 1217;
BA_REL_ "GenSigTimeoutTime" BU_SG_REL_ EBOOST_OBD_PHS SG_ 1217 LegPstDTCClrDrvCyCm 1250;
BA_REL_ "GenSigSuprvResp" BU_SG_REL_ EBCM_PHS SG_ 1217 LegDiagColdStCndMet 1;
BA_REL_ "GenSigTimeoutMsg" BU_SG_REL_ EBCM_PHS SG_ 1217 LegDiagColdStCndMet 1217;
BA_REL_ "GenSigTimeoutTime" BU_SG_REL_ EBCM_PHS SG_ 1217 LegDiagColdStCndMet 1250;
BA_REL_ "GenSigSuprvResp" BU_SG_REL_ EBCM_PHS SG_ 1217 LegDiagColdStCndFltPr 1;
BA_REL_ "GenSigTimeoutMsg" BU_SG_REL_ EBCM_PHS SG_ 1217 LegDiagColdStCndFltPr 1217;
BA_REL_ "GenSigTimeoutTime" BU_SG_REL_ EBCM_PHS SG_ 1217 LegDiagColdStCndFltPr 1250;
BA_REL_ "GenSigSuprvResp" BU_SG_REL_ EBCM_PHS SG_ 1217 LegDiagStndCndMet 1;
BA_REL_ "GenSigTimeoutMsg" BU_SG_REL_ EBCM_PHS SG_ 1217 LegDiagStndCndMet 1217;
BA_REL_ "GenSigTimeoutTime" BU_SG_REL_ EBCM_PHS SG_ 1217 LegDiagStndCndMet 1250;
BA_REL_ "GenSigSuprvResp" BU_SG_REL_ EBCM_PHS SG_ 1217 LegDiagStndCndFltPr 1;
BA_REL_ "GenSigTimeoutMsg" BU_SG_REL_ EBCM_PHS SG_ 1217 LegDiagStndCndFltPr 1217;
BA_REL_ "GenSigTimeoutTime" BU_SG_REL_ EBCM_PHS SG_ 1217 LegDiagStndCndFltPr 1250;
BA_REL_ "GenSigSuprvResp" BU_SG_REL_ EBCM_PHS SG_ 1217 OAT_PT_Est 1;
BA_REL_ "GenSigTimeoutMsg" BU_SG_REL_ EBCM_PHS SG_ 1217 OAT_PT_Est 1217;
BA_REL_ "GenSigTimeoutTime" BU_SG_REL_ EBCM_PHS SG_ 1217 OAT_PT_Est 1250;
BA_REL_ "GenSigVBitResp" BU_SG_REL_ EBCM_PHS SG_ 1217 OAT_PT_Est 1;
BA_REL_ "GenSigSuprvResp" BU_SG_REL_ EBCM_PHS SG_ 1217 OAT_PT_Est 1;
BA_REL_ "GenSigTimeoutMsg" BU_SG_REL_ EBCM_PHS SG_ 1217 OAT_PT_Est 1217;
BA_REL_ "GenSigTimeoutTime" BU_SG_REL_ EBCM_PHS SG_ 1217 OAT_PT_Est 1250;
BA_REL_ "GenSigVBitResp" BU_SG_REL_ EBCM_PHS SG_ 1217 OAT_PT_Est 1;
BA_REL_ "GenSigSuprvResp" BU_SG_REL_ EBCM_PHS SG_ 1217 OAT_PT_Est 1;
BA_REL_ "GenSigTimeoutMsg" BU_SG_REL_ EBCM_PHS SG_ 1217 OAT_PT_Est 1217;
BA_REL_ "GenSigTimeoutTime" BU_SG_REL_ EBCM_PHS SG_ 1217 OAT_PT_Est 1250;
BA_REL_ "GenSigSuprvResp" BU_SG_REL_ EBOOST_OBD_PHS SG_ 1217 EngWrmUpAch 1;
BA_REL_ "GenSigTimeoutMsg" BU_SG_REL_ EBOOST_OBD_PHS SG_ 1217 EngWrmUpAch 1217;
BA_REL_ "GenSigTimeoutTime" BU_SG_REL_ EBOOST_OBD_PHS SG_ 1217 EngWrmUpAch 1250;
BA_REL_ "GenSigSuprvResp" BU_SG_REL_ EBCM_PHS SG_ 1217 EngWrmUpAch 1;
BA_REL_ "GenSigTimeoutMsg" BU_SG_REL_ EBCM_PHS SG_ 1217 EngWrmUpAch 1217;
BA_REL_ "GenSigTimeoutTime" BU_SG_REL_ EBCM_PHS SG_ 1217 EngWrmUpAch 1250;
BA_REL_ "GenSigVBitResp" BU_SG_REL_ EBCM_PHS SG_ 1217 EngIntAirTmp 1;
BA_REL_ "GenSigSuprvResp" BU_SG_REL_ EBCM_PHS SG_ 1217 EngIntAirTmp 1;
BA_REL_ "GenSigTimeoutMsg" BU_SG_REL_ EBCM_PHS SG_ 1217 EngIntAirTmp 4688;
BA_REL_ "GenSigVBitResp" BU_SG_REL_ EBCM_PHS SG_ 1217 EngCltTmp 1;
BA_REL_ "GenSigSuprvResp" BU_SG_REL_ EBCM_PHS SG_ 1217 EngCltTmp 1;
BA_REL_ "GenSigTimeoutMsg" BU_SG_REL_ EBCM_PHS SG_ 1217 EngCltTmp 1217;
BA_REL_ "GenSigTimeoutTime" BU_SG_REL_ EBCM_PHS SG_ 1217 EngCltTmp 1250;
BA_REL_ "GenSigVBitResp" BU_SG_REL_ EPSb_PHS SG_ 1217 EngCltTmp 1;
BA_REL_ "GenSigSuprvResp" BU_SG_REL_ EPSb_PHS SG_ 1217 EngCltTmp 1;
BA_REL_ "GenSigTimeoutMsg" BU_SG_REL_ EPSb_PHS SG_ 1217 EngCltTmp 1217;
BA_REL_ "GenSigTimeoutTime" BU_SG_REL_ EPSb_PHS SG_ 1217 EngCltTmp 1250;
BA_REL_ "GenSigVBitResp" BU_SG_REL_ EPSa_PHS SG_ 1217 EngCltTmp 1;
BA_REL_ "GenSigSuprvResp" BU_SG_REL_ EPSa_PHS SG_ 1217 EngCltTmp 1;
BA_REL_ "GenSigTimeoutMsg" BU_SG_REL_ EPSa_PHS SG_ 1217 EngCltTmp 1217;
BA_REL_ "GenSigTimeoutTime" BU_SG_REL_ EPSa_PHS SG_ 1217 EngCltTmp 1250;
BA_REL_ "GenSigVBitResp" BU_SG_REL_ EBCM_PHS SG_ 1217 BarPrsAbs 1;
BA_REL_ "GenSigSuprvResp" BU_SG_REL_ EBCM_PHS SG_ 1217 BarPrsAbs 1;
BA_REL_ "GenSigTimeoutMsg" BU_SG_REL_ EBCM_PHS SG_ 1217 BarPrsAbs 4688;
BA_REL_ "GenSigVBitResp" BU_SG_REL_ EOCM2cp_IMX6_PHS SG_ 309 Sec 1;
BA_REL_ "GenSigSuprvResp" BU_SG_REL_ EBCM_PHS SG_ 309 CldrYr 1;
BA_REL_ "GenSigTimeoutMsg" BU_SG_REL_ EBCM_PHS SG_ 309 CldrYr 309;
BA_REL_ "GenSigTimeoutTime" BU_SG_REL_ EBCM_PHS SG_ 309 CldrYr 500;
BA_REL_ "GenSigSuprvResp" BU_SG_REL_ EBCM_PHS SG_ 309 CldrYr 1;
BA_REL_ "GenSigTimeoutMsg" BU_SG_REL_ EBCM_PHS SG_ 309 CldrYr 309;
BA_REL_ "GenSigTimeoutTime" BU_SG_REL_ EBCM_PHS SG_ 309 CldrYr 250;
BA_REL_ "GenSigSuprvResp" BU_SG_REL_ EBCM_PHS SG_ 309 CldrMth 1;
BA_REL_ "GenSigTimeoutMsg" BU_SG_REL_ EBCM_PHS SG_ 309 CldrMth 309;
BA_REL_ "GenSigTimeoutTime" BU_SG_REL_ EBCM_PHS SG_ 309 CldrMth 500;
BA_REL_ "GenSigSuprvResp" BU_SG_REL_ EBCM_PHS SG_ 309 CldrDay 1;
BA_REL_ "GenSigTimeoutMsg" BU_SG_REL_ EBCM_PHS SG_ 309 CldrDay 309;
BA_REL_ "GenSigTimeoutTime" BU_SG_REL_ EBCM_PHS SG_ 309 CldrDay 500;
BA_REL_ "GenSigVBitResp" BU_SG_REL_ EBCM_PHS SG_ 309 TCSysDisSwAtv 1;
BA_REL_ "GenSigSuprvResp" BU_SG_REL_ EBCM_PHS SG_ 309 TCSysDisSwAtv 1;
BA_REL_ "GenSigTimeoutMsg" BU_SG_REL_ EBCM_PHS SG_ 309 TCSysDisSwAtv 309;
BA_REL_ "GenSigTimeoutTime" BU_SG_REL_ EBCM_PHS SG_ 309 TCSysDisSwAtv 500;
BA_REL_ "GenSigVBitResp" BU_SG_REL_ EOCM2cp_IMX6_PHS SG_ 309 TCSysDisSwAtv 1;
BA_REL_ "GenSigVBitResp" BU_SG_REL_ EBCM_PHS SG_ 309 HillDesCtrlMdSwAct 1;
BA_REL_ "GenSigSuprvResp" BU_SG_REL_ EBCM_PHS SG_ 309 HillDesCtrlMdSwAct 1;
BA_REL_ "GenSigTimeoutMsg" BU_SG_REL_ EBCM_PHS SG_ 309 HillDesCtrlMdSwAct 309;
BA_REL_ "GenSigTimeoutTime" BU_SG_REL_ EBCM_PHS SG_ 309 HillDesCtrlMdSwAct 500;
BA_REL_ "GenSigVBitResp" BU_SG_REL_ EOCM2cp_IMX6_PHS SG_ 309 HillDesCtrlMdSwAct 1;
BA_REL_ "GenSigVDAFailComment" BU_SG_REL_ EOCM2cp_IMX6_PHS SG_ 309 RrClosAjarSwAct "Rear Closure VDA";
BA_REL_ "GenSigVDAFailResp" BU_SG_REL_ EOCM2cp_IMX6_PHS SG_ 309 RrClosAjarSwAct 1;
BA_REL_ "GenSigSuprvResp" BU_SG_REL_ EBCM_PHS SG_ 309 WSWprAct 1;
BA_REL_ "GenSigTimeoutMsg" BU_SG_REL_ EBCM_PHS SG_ 309 WSWprAct 309;
BA_REL_ "GenSigTimeoutTime" BU_SG_REL_ EBCM_PHS SG_ 309 WSWprAct 500;
VAL_ 355 RdRghnsStatRed 1 "Failed" 0 "Normal" ;
VAL_ 355 PriTCSStatRed 3 "Failed" 2 "Active" 1 "Available" 0 "Unknown" ;
VAL_ 355 PriGrsHydLkDtctdRed 1 "true" 0 "false" ;
VAL_ 355 PriGrsHydCmpDtctdRed 1 "true" 0 "false" ;
VAL_ 355 PriGrsBrkIneffDtctdRed 1 "true" 0 "false" ;
VAL_ 355 PriESCStatRed 3 "Failed" 2 "Active" 1 "Available" 0 "Unknown" ;
VAL_ 355 PriDRPStatRed 3 "Failed" 2 "Active" 1 "Available" 0 "Unknown" ;
VAL_ 355 PriABSStatRed 3 "Failed" 2 "Active" 1 "Available" 0 "Unknown" ;
VAL_ 355 EstBrkRtrTempStatRed 1 "Failed" 0 "Normal" ;
VAL_ 355 EPBStatRed 3 "Failed" 2 "Reduced Performance" 1 "Normal" 0 "Unknown" ;
VAL_ 355 EPBApplStRed 3 "Applied" 2 "Transitioning" 1 "Released" 0 "Unknown" ;
VAL_ 355 BrkFldLvlIndStatRed 1 "Failed" 0 "Normal" ;
VAL_ 355 BrkFldLvILwFldDtctdRed 1 "true" 0 "false" ;
VAL_ 341 StrgCmndMsgStatV 1 "Invalid" 0 "Valid" ;
VAL_ 341 StrgCmndMsgStat 3 "Dual Communication Failure" 2 "Redundant Communication Failed" 1 "Primary Communication Failed" 0 "Communication Normal" ;
VAL_ 341 StrgCmndMsgUtlzdV 1 "Invalid" 0 "Valid" ;
VAL_ 341 StrgCmndMsgUtlzd 1 "Redundant Controller" 0 "Primary Controller" ;
VAL_ 341 AutoStrgCmndStatV 1 "Invalid" 0 "Valid" ;
VAL_ 341 StgTrqSnsrVStat 1 "Invalid" 0 "Valid" ;
VAL_ 341 StgSysOtptStatV 1 "Invalid" 0 "Valid" ;
VAL_ 341 StgSysOtptStat 3 "Failed" 2 "Single Controller" 1 "Fail Operational" 0 "Unknown" ;
VAL_ 341 StgOtptTempLmtgSte 4 "Voltage" 3 "Thermal" 2 "Safety Limit Exceeded" 1 "Normal" 0 "Unknown" 7 "ECU Fault Limited" 6 "Friction Limited" 5 "Lash Exceeded" ;
VAL_ 341 StgAngRtLmtV 1 "Invalid" 0 "Valid" ;
VAL_ 341 AutoStrgCmndStat 6 "Failed" 5 "Emergency Steering Profile" 4 "Temporarily Limited" 3 "Active" 2 "Ready" 1 "Temporarily Inhibited" 0 "Unknown" ;
VAL_ 341 StgOvrdDetn 3 "Disabled" 2 "False" 1 "True" 0 "Initialization" ;
VAL_ 313 LnchCtrlRelLnLockReqd 1 "true" 0 "false" ;
VAL_ 313 DrvrDrOpenSwVDA 1 "VirtualDeviceAvailable" 0 "VirtualDeviceUnavailable" ;
VAL_ 313 DrDoorOpenSwActV 1 "Invalid" 0 "Valid" ;
VAL_ 313 DrDoorOpenSwAct 1 "true" 0 "false" ;
VAL_ 313 LnchCtrlWhlSlpReq 31 "Unused and Reserved 10" 30 "Unused and Reserved 9" 29 "Unused and Reserved 8" 28 "Unused and Reserved 7" 27 "Unused and Reserved 6" 26 "Unused and Reserved 5" 25 "Unused and Reserved 4" 24 "Unused and Reserved 3" 23 "Unused and Reserved 2" 22 "Unused and Reserved 1" 21 "Fifteen Percent" 20 "Fourteen And A Half Percent" 19 "Fourteen Percent" 18 "Thirteen And A Half Percent" 17 "Thirteen Percent" 16 "Twelve And A Half Percent" 15 "Twelve Percent" 14 "Eleven And a Half Percent" 13 "Eleven Percent" 12 "Ten And A Half Percent" 11 "Ten Percent" 10 "Nine And A Half Percent" 9 "Nine Percent" 8 "Eight And A Half Percent" 7 "Eight Percent" 6 "Seven And A Half Percent" 5 "Seven Percent" 4 "Six And A Half Percent" 3 "Six Percent" 2 "Five And A Half Percent" 1 "Five Percent" 0 "No Action" ;
VAL_ 313 LnchCtrlMdReq 3 "Burn Out" 2 "Custom" 1 "Automatic" 0 "No Action" ;
VAL_ 313 LnchCtrlEngRPMReq 24 "3100" 23 "3000" 22 "2900" 21 "2800" 20 "2700" 19 "2600" 18 "2500" 17 "2400" 16 "2300" 15 "2200" 14 "2100" 13 "2000" 12 "1900" 11 "1800" 10 "1700" 9 "1600" 8 "1500" 7 "1400" 6 "1300" 5 "1200" 4 "1100" 3 "1000" 2 "900" 1 "800" 0 "No Action" 63 "Unused and Reserved 30" 62 "Unused and Reserved 29" 61 "Unused and Reserved 28" 60 "Unused and Reserved 27" 59 "Unused and Reserved 26" 58 "Unused and Reserved 25" 57 "Unused and Reserved 24" 56 "Unused and Reserved 23" 55 "Unused and Reserved 22" 54 "Unused and Reserved 21" 53 "Unused and Reserved 20" 52 "Unused and Reserved 19" 51 "Unused and Reserved 18" 50 "Unused and Reserved 17" 49 "Unused and Reserved 16" 48 "Unused and Reserved 15" 47 "Unused and Reserved 14" 46 "Unused and Reserved 13" 45 "Unused and Reserved 12" 44 "Unused and Reserved 11" 43 "Unused and Reserved 10" 42 "Unused and Reserved 9" 41 "Unused and Reserved 8" 40 "Unused and Reserved 7" 39 "Unused and Reserved 6" 38 "Unused and Reserved 5" 37 "Unused and Reserved 4" 36 "Unused and Reserved 3" 35 "Unused and Reserved 2" 34 "Unused and Reserved 1" 33 "4000" 32 "3900" 31 "3800" 30 "3700" 29 "3600" 28 "3500" 27 "3400" 26 "3300" 25 "3200" ;
VAL_ 313 ExtHlStrAssCsStRq 2 "Standard Hold" 1 "Extended Hold" 0 "No Action" ;
VAL_ 313 DrvStyPerfMdCsStReq 7 "Performance Mode 7" 6 "Performance Mode 6" 5 "Performance Mode 5" 4 "Performance Mode 4" 3 "Performance Mode 3" 2 "Performance Mode 2" 1 "Performance Mode 1" 0 "No Action" ;
VAL_ 313 PsngStPerfMdCsStReq 7 "Auto" 6 "Performance Mode 6" 5 "Performance Mode 5" 4 "Performance Mode 4" 3 "Performance Mode 3" 2 "Performance Mode 2" 1 "Performance Mode 1" 0 "No Action" ;
VAL_ 313 DrvrStPerfMdCsStReq 7 "Auto" 6 "Performance Mode 6" 5 "Performance Mode 5" 4 "Performance Mode 4" 3 "Performance Mode 3" 2 "Performance Mode 2" 1 "Performance Mode 1" 0 "No Action" ;
VAL_ 313 ACCPerfMdCsStReq 7 "Auto" 6 "Performance Mode 6" 5 "Performance Mode 5" 4 "Performance Mode 4" 3 "Performance Mode 3" 2 "Performance Mode 2" 1 "Performance Mode 1" 0 "No Action" ;
VAL_ 313 PrkAstAdvSysAct 1 "true" 0 "false" ;
VAL_ 313 SndPerfMdCsStRq 0 "No Action" 1 "Performance Mode 1" 2 "Performance Mode 2" 3 "Performance Mode 3" 4 "Performance Mode 4" 5 "Performance Mode 5" 6 "Performance Mode 6" 7 "Auto" ;
VAL_ 313 ACCSettingType 0 "Manual" 1 "Auto" ;
VAL_ 313 FCABrkPrflReq 1 "true" 0 "false" ;
VAL_ 313 ISA2CCC_ScndCdChr 0 "Unknown" 1 "A" 2 "B" 3 "C" 4 "D" 5 "E" 6 "F" 7 "G" 8 "H" 9 "I" 10 "J" 11 "K" 12 "L" 13 "M" 14 "N" 15 "O" 16 "P" 17 "Q" 18 "R" 19 "S" 20 "T" 21 "U" 22 "V" 23 "W" 24 "X" 25 "Y" 26 "Z" ;
VAL_ 313 ISA2CCC_FrstCdChr 0 "Unknown" 1 "A" 2 "B" 3 "C" 4 "D" 5 "E" 6 "F" 7 "G" 8 "H" 9 "I" 10 "J" 11 "K" 12 "L" 13 "M" 14 "N" 15 "O" 16 "P" 17 "Q" 18 "R" 19 "S" 20 "T" 21 "U" 22 "V" 23 "W" 24 "X" 25 "Y" 26 "Z" ;
VAL_ 313 DispPerfMdCsStRq 0 "No Action" 1 "Performance Mode 1" 2 "Performance Mode 2" 3 "Performance Mode 3" 4 "Performance Mode 4" 5 "Performance Mode 5" 6 "Performance Mode 6" 7 "Auto" ;
VAL_ 313 FwdClnAlrtCustStngReq 0 "No Action" 1 "Off" 2 "On" ;
VAL_ 313 GNCustStngReq 0 "No Action" 1 "Off" 2 "On" ;
VAL_ 1275 BrkSyCtl2EmsRldMlfAct 1 "true" 0 "false" ;
VAL_ 1275 BSC2ERDTC_SysDes 15 "U3-Network Codes Reserved" 14 "U2-Network Codes Reserved" 13 "U1-Network Codes MFG Controlled" 12 "U0-Network Codes SAE Controlled" 11 "B3-Body Codes Reserved" 10 "B2-Body Codes Reserved" 9 "B1-Body Codes MFG Controlled" 8 "B0-Body Codes SAE Controlled" 7 "C3-Chassis Codes Reserved" 6 "C2-Chassis Codes Reserved" 5 "C1-Chassis Codes MFG Controlled" 4 "C0-Chassis Codes SAE Controlled" 3 "P3-Powertrain Codes Reserved" 2 "P2-Powertrain Codes Reserved" 1 "P1-Powertrain Codes MFG Controlled" 0 "P0-Powertrain Codes SAE Controlled" ;
VAL_ 1275 EBrkAstStat 7 "Faulted" 6 "Temporarily Failed" 5 "Reduced" 4 "Standalone" 3 "PostRun Reduced" 2 "Normal" 1 "Initializing" 0 "Not Initialized" ;
VAL_ 381 HillDesCtrlRedVehSpIO 1 "true" 0 "false" ;
VAL_ 381 EBDFailed 1 "true" 0 "false" ;
VAL_ 381 StWhAnVDA 1 "VirtualDeviceAvailable" 0 "VirtualDeviceUnavailable" ;
VAL_ 381 TirePrsLowIO 1 "true" 0 "false" ;
VAL_ 381 VaccBoostFailure 1 "true" 0 "false" ;
VAL_ 381 VSESysPrs 1 "true" 0 "false" ;
VAL_ 381 HalfSysFail 1 "true" 0 "false" ;
VAL_ 381 ActVehAccelV 1 "Invalid" 0 "Valid" ;
VAL_ 381 BksOvht 1 "true" 0 "false" ;
VAL_ 381 TCSysPr 1 "true" 0 "false" ;
VAL_ 381 ABSPr 1 "true" 0 "false" ;
VAL_ 381 TreInfMonSysRstPrfmd 1 "true" 0 "false" ;
VAL_ 381 ABSIO 1 "true" 0 "false" ;
VAL_ 381 BrkPadWrnIO 1 "true" 0 "false" ;
VAL_ 381 VehStabEnhmntMd 2 "Competitive" 1 "Normal" 0 "Off" ;
VAL_ 381 VehStabEnhmntStat 4 "Not Ready" 3 "Warming Up" 2 "Fault" 1 "Active" 0 "Inactive" ;
VAL_ 381 TCSysOpMd 2 "Off Road" 1 "Normal" 0 "Off" ;
VAL_ 381 TCSysOpStat 2 "Fault" 1 "Active" 0 "Inactive" ;
VAL_ 381 BrkSysRedBrkTlltlReq 1 "true" 0 "false" ;
VAL_ 381 BrkSysBrkLtsReqd 1 "true" 0 "false" ;
VAL_ 485 StrWhAngGrdV 1 "Invalid" 0 "Valid" ;
VAL_ 485 StrWhAngGrdMsk 1 "Use Data" 0 "Don't Use Data" ;
VAL_ 485 StrWhAngMsk 1 "Use Data" 0 "Don't Use Data" ;
VAL_ 485 StrWhlAngSenTyp 0 "Type 1" 1 "Type 2" 2 "Type 3" 3 "Type 4" ;
VAL_ 485 StrWhlAngSenCalStat 2 "Calibrated" 1 "Estimated" 0 "Unknown" ;
VAL_ 485 StrWhAngV 1 "Invalid" 0 "Valid" ;
VAL_ 532 RedntVSEAct 1 "true" 0 "false" ;
VAL_ 532 HilRlbkCtrlActIO 1 "true" 0 "false" ;
VAL_ 532 VehHldDrvrDsblActvFlg 1 "true" 0 "false" ;
VAL_ 532 AutoBrkngAvlbl 1 "true" 0 "false" ;
VAL_ 532 ABSAutnmsBrkReq 1 "true" 0 "false" ;
VAL_ 532 HlStrAssActIO 1 "true" 0 "false" ;
VAL_ 532 BrkSysAutBrkFld 1 "true" 0 "false" ;
VAL_ 532 IntBrkAssPreFilReq 1 "true" 0 "false" ;
VAL_ 532 BrkSysMalFuncIndOn 1 "true" 0 "false" ;
VAL_ 532 BPDAPS_BkPDrvApPV 1 "Invalid" 0 "Valid" ;
VAL_ 532 BrkFldLvlLwV 1 "Invalid" 0 "Valid" ;
VAL_ 532 AutoBrkngAct 1 "true" 0 "false" ;
VAL_ 532 BrkFldLvlLw 1 "true" 0 "false" ;
VAL_ 532 ABSActvProt 1 "true" 0 "false" ;
VAL_ 489 EnhDrvMdSwChUseRq 1 "true" 0 "false" ;
VAL_ 489 IMUDataMsk 1 "true" 0 "false" ;
VAL_ 489 DrvIndpntBrkAppAct 1 "true" 0 "false" ;
VAL_ 489 WhlSlpSt 3 "Slip Detection Fault" 2 "Positive Slip Detected" 1 "Negative Slip Detected" 0 "No Slip Detected" ;
VAL_ 489 BSTGRReqdGear 10 "Tenth Gear" 9 "Ninth Gear" 8 "Eighth Gear" 7 "Seventh Gear" 6 "Sixth Gear" 5 "Fifth Gear" 4 "Fourth Gear" 3 "Third Gear" 2 "Second Gear" 1 "First Gear" 0 "No Action" ;
VAL_ 489 BSTGRReqType 1 "Max Gear Request" 0 "No Action" 3 "Hold Gear" 2 "Min Gear Request" ;
VAL_ 489 VSELatAccV 1 "Invalid" 0 "Valid" ;
VAL_ 489 VSEAct 1 "true" 0 "false" ;
VAL_ 489 VhDynCntlSysSt 7 "Driver Disabled" 6 "Enhanced Operation" 5 "Calibrating" 4 "Warming Up" 3 "Permanently Failed" 2 "Temporarily Inhibited" 1 "Reduced Function" 0 "Normal Operation" ;
VAL_ 489 VehDynYawRateV 1 "Invalid" 0 "Valid" ;
VAL_ 489 TrnsBrkSysCltchRelRqd 1 "true" 0 "false" ;
VAL_ 489 TracCntrlSysDrIntnt 1 "Enabled" 0 "Disabled" ;
VAL_ 489 VehDynOvrUndrStrV 1 "Invalid" 0 "Valid" ;
VAL_ 489 TCSysEnbld 1 "true" 0 "false" ;
VAL_ 489 TCSysAtv 1 "true" 0 "false" ;
VAL_ 489 BrkPdlDrvAppPrsDetcdV 1 "Invalid" 0 "Valid" ;
VAL_ 489 BrkPdlDrvAppPrsDetcd 1 "true" 0 "false" ;
VAL_ 489 ACCBrkngAct 1 "true" 0 "false" ;
VAL_ 489 ABSFld 1 "true" 0 "false" ;
VAL_ 489 ABSAtv 1 "true" 0 "false" ;
VAL_ 305 PriBrkModStatRed 3 "Failed" 2 "Active" 1 "Available" 0 "Not Available" ;
VAL_ 305 PriAutoEstBrkTrqAppStatRed 2 "Valid" 1 "Reduced Accuracy" 0 "Invalid" ;
VAL_ 305 PriAutoBrkSysDrInfcStatRed 3 "Failed" 2 "Driver Intervention Not Detected" 1 "Driver Intervention Detected" 0 "Unknown" ;
VAL_ 305 MstCylPrsCrct1Stat 2 "Faulted" 1 "Normal" 0 "Unknown" ;
VAL_ 305 PriSuffBrkTrqStdstlRed 1 "true" 0 "false" ;
VAL_ 1020 OtsAirTmpEmsnsRelV 1 "Invalid" 0 "Valid" ;
VAL_ 1020 OATEmsnsRelCrValV 1 "Invalid" 0 "Valid" ;
VAL_ 1020 OATEmsnsRelCrValM 1 "Use Data" 0 "Don't Use Data" ;
VAL_ 1020 CatlystOutGasTempEstV 1 "Invalid" 0 "Valid" ;
VAL_ 1020 OtsAirTmpCrValMsk 1 "Use Data" 0 "Don't Use Data" ;
VAL_ 1020 OtsAirTmpV 1 "Invalid" 0 "Valid" ;
VAL_ 1020 OtsAirTmpCrValV 1 "Invalid" 0 "Valid" ;
VAL_ 1020 EngInltSpcfcHmdtyV 1 "Invalid" 0 "Valid" ;
VAL_ 1020 EngInltSpcfcHmdtyM 1 "Use Data" 0 "Don't Use Data" ;
VAL_ 338 CoPRVBAtv 1 "true" 0 "false" ;
VAL_ 338 CoPCIBAtv 1 "true" 0 "false" ;
VAL_ 338 CPEPSWAR_ReqdState 2 "Active" 1 "Inactive" 0 "No Action" ;
VAL_ 338 CoPEPBReq 2 "Request Release" 1 "Request Apply" 0 "No Request" ;
VAL_ 338 CoPCntrlFail 1 "true" 0 "false" ;
VAL_ 338 CoPAutoBrkReqType 2 "Standstill Hold Request" 1 "Brake Torque Request" 0 "No Request" 3 "Brake Prefill" ;
VAL_ 835 TmSyncMstrTmClkV 1 "Invalid" 0 "Valid" ;
VAL_ 835 RTXCorrctnEnbl 1 "Enabled" 0 "Disabled" ;
VAL_ 753 EBCMDS5_DTCStatus 0 "Not Supported" 1 "Critically Disabled" 2 "No Status to Report" 3 "Diagnostic Passed" 4 "Diagnostic Failed" ;
VAL_ 753 EBCMDS4_DTCStatus 0 "Not Supported" 1 "Critically Disabled" 2 "No Status to Report" 3 "Diagnostic Passed" 4 "Diagnostic Failed" ;
VAL_ 753 EBCMDS3_DTCStatus 0 "Not Supported" 1 "Critically Disabled" 2 "No Status to Report" 3 "Diagnostic Passed" 4 "Diagnostic Failed" ;
VAL_ 753 EBCMDS2_DTCStatus 0 "Not Supported" 1 "Critically Disabled" 2 "No Status to Report" 3 "Diagnostic Passed" 4 "Diagnostic Failed" ;
VAL_ 753 EBCMDS1_DTCStatus 0 "Not Supported" 1 "Critically Disabled" 2 "No Status to Report" 3 "Diagnostic Passed" 4 "Diagnostic Failed" ;
VAL_ 869 TnDrvGapAdjUnbIO 1 "true" 0 "false" ;
VAL_ 869 CPSCA_Resrv3Avail 1 "true" 0 "false" ;
VAL_ 869 CPSCA_Resrv2Avail 1 "true" 0 "false" ;
VAL_ 869 CPSCA_Resrv1Avail 1 "true" 0 "false" ;
VAL_ 869 CPSCA_AlrtBrkStrAvail 1 "true" 0 "false" ;
VAL_ 869 CPSCA_AlrtBrkAvail 1 "true" 0 "false" ;
VAL_ 869 CPSCA_AlrtAvail 1 "true" 0 "false" ;
VAL_ 869 CPSCA_OffAvail 1 "true" 0 "false" ;
VAL_ 869 FwdClnMtgnBrkReqAct 1 "true" 0 "false" ;
VAL_ 869 FCACustStngAvlbl 1 "true" 0 "false" ;
VAL_ 869 FwdClnAlrtCustCrntSetngVal 0 "No Action" 1 "Off" 2 "On" ;
VAL_ 869 GNCustSetngAvlbl 1 "true" 0 "false" ;
VAL_ 869 CPSUnblIO 1 "true" 0 "false" ;
VAL_ 869 ColPrSysStngAvl 1 "true" 0 "false" ;
VAL_ 869 CPSOffIO 1 "true" 0 "false" ;
VAL_ 869 CPSFldIO 1 "true" 0 "false" ;
VAL_ 869 ColPrSysCrntStng 4 "Alert and Brake and Steer" 0 "No Action" 1 "Off" 2 "Alert" 3 "Alert and Brake" ;
VAL_ 869 CPSAlrtOnlIO 1 "true" 0 "false" ;
VAL_ 869 GNCustCrntStngVal 0 "No Action" 1 "Off" 2 "On" ;
VAL_ 869 CoPilotWndShldWashReqAct 1 "true" 0 "false" ;
VAL_ 1217 LDMinEngCltTmpRchd 1 "true" 0 "false" ;
VAL_ 1217 LegPstDTCClrDrvCyCm 1 "true" 0 "false" ;
VAL_ 1217 LegDiagColdStCndMet 1 "true" 0 "false" ;
VAL_ 1217 LegDiagColdStCndFltPr 1 "true" 0 "false" ;
VAL_ 1217 EngEconMdCmnd 1 "true" 0 "false" ;
VAL_ 1217 DslExhFldRmngDstHRsV 1 "Invalid" 0 "Valid" ;
VAL_ 1217 EngOilHotIO 1 "true" 0 "false" ;
VAL_ 1217 OAT_PT_EstV 1 "Invalid" 0 "Valid" ;
VAL_ 1217 LegDiagStndCndMet 1 "true" 0 "false" ;
VAL_ 1217 LegDiagStndCndFltPr 1 "true" 0 "false" ;
VAL_ 1217 OAT_PT_EstM 1 "Use Data" 0 "Don't Use Data" ;
VAL_ 1217 EngWrmUpAch 1 "true" 0 "false" ;
VAL_ 1217 EngIntAirTmpV 1 "Invalid" 0 "Valid" ;
VAL_ 1217 EngCltTmpV 1 "Invalid" 0 "Valid" ;
VAL_ 1217 BarPrsAbsV 1 "Invalid" 0 "Valid" ;
VAL_ 328 StrngAsstRdcdIO 1 "true" 0 "false" ;
VAL_ 328 PwrStrIO 1 "true" 0 "false" ;
VAL_ 309 PedFrndlyAlrtSndMnAct 1 "true" 0 "false" ;
VAL_ 309 ColPrSysCustReq 1 "Off" 2 "Alert" 3 "Alert and Brake" 4 "Alert and Brake and Steer" 0 "No Action" ;
VAL_ 309 SecV 1 "Invalid" 0 "Valid" ;
VAL_ 309 CldrMth_154 12 "December" 11 "November" 10 "October" 9 "September" 8 "August" 7 "July" 6 "June" 5 "May" 4 "April" 3 "March" 2 "February" 1 "January" 0 "Unknown" ;
VAL_ 309 CldrMth 12 "December" 11 "November" 10 "October" 9 "September" 8 "August" 7 "July" 6 "June" 5 "May" 4 "April" 3 "March" 2 "February" 1 "January" 0 "Unknown" ;
VAL_ 309 AutoHiBmVDA 1 "VirtualDeviceAvailable" 0 "VirtualDeviceUnavailable" ;
VAL_ 309 CtLghtDet 1 "true" 0 "false" ;
VAL_ 309 RrClosVDA 1 "VirtualDeviceAvailable" 0 "VirtualDeviceUnavailable" ;
VAL_ 309 TCSysDisSwAtv 1 "true" 0 "false" ;
VAL_ 309 VehMovState 4 "Invalid" 3 "Reverse" 2 "Forward" 1 "Neutral" 0 "Parked" ;
VAL_ 309 TCSysDisSwAtvV 1 "Invalid" 0 "Valid" ;
VAL_ 309 HillDesCtrlMdSwActV 1 "Invalid" 0 "Valid" ;
VAL_ 309 WSWshSwAtv 1 "true" 0 "false" ;
VAL_ 309 HillDesCtrlMdSwAct 1 "true" 0 "false" ;
VAL_ 309 RrClosAjarSwAct 1 "true" 0 "false" ;
VAL_ 309 WSWprAct 1 "true" 0 "false" ;
VAL_ 1905 DTCI_DTCFaultType_771 3 "Type C" 2 "Type B" 1 "Type A" 0 "Not Supported" ;
VAL_ 1905 DTCI_CodeSupported_771 1 "true" 0 "false" ;
VAL_ 1905 DTCI_CurrentStatus_771 1 "true" 0 "false" ;
VAL_ 1905 DTCI_TstNPsdCdClrdSt_771 1 "true" 0 "false" ;
VAL_ 1905 DTCI_TstFldCdClrdStat_771 1 "true" 0 "false" ;
VAL_ 1905 DTCI_HistStat_771 1 "true" 0 "false" ;
VAL_ 1905 DTCI_TstNPsdPwrUpSt_771 1 "true" 0 "false" ;
VAL_ 1905 DTCI_TstFldPwrUpSt_771 1 "true" 0 "false" ;
VAL_ 1905 DTCI_WrnIndRqdSt_771 1 "true" 0 "false" ;
VAL_ 1905 DTCI_DTCTriggered_771 1 "true" 0 "false" ;
VAL_ 1905 DTCIUnused7_771 1 "true" 0 "false" ;
VAL_ 1905 DTCIUnused6_771 1 "true" 0 "false" ;
VAL_ 1905 DTCIUnused5_771 1 "true" 0 "false" ;
VAL_ 1905 DTCIUnused4_771 1 "true" 0 "false" ;
VAL_ 1905 DTCIUnused3_771 1 "true" 0 "false" ;
VAL_ 1905 DTCIUnused2_771 1 "true" 0 "false" ;
VAL_ 1905 DTCIUnused1_771 1 "true" 0 "false" ;
VAL_ 1930 DTCI_CodeSupported_78A 1 "true" 0 "false" ;
VAL_ 1930 DTCI_CurrentStatus_78A 1 "true" 0 "false" ;
VAL_ 1930 DTCI_DTCFaultType_78A 3 "Type C" 2 "Type B" 1 "Type A" 0 "Not Supported" ;
VAL_ 1930 DTCI_DTCTriggered_78A 1 "true" 0 "false" ;
VAL_ 1930 DTCI_HistStat_78A 1 "true" 0 "false" ;
VAL_ 1930 DTCI_TstFldCdClrdStat_78A 1 "true" 0 "false" ;
VAL_ 1930 DTCI_TstFldPwrUpSt_78A 1 "true" 0 "false" ;
VAL_ 1930 DTCI_TstNPsdCdClrdSt_78A 1 "true" 0 "false" ;
VAL_ 1930 DTCI_TstNPsdPwrUpSt_78A 1 "true" 0 "false" ;
VAL_ 1930 DTCIUnused1_78A 1 "true" 0 "false" ;
VAL_ 1930 DTCIUnused2_78A 1 "true" 0 "false" ;
VAL_ 1930 DTCIUnused3_78A 1 "true" 0 "false" ;
VAL_ 1930 DTCIUnused4_78A 1 "true" 0 "false" ;
VAL_ 1930 DTCIUnused5_78A 1 "true" 0 "false" ;
VAL_ 1930 DTCIUnused6_78A 1 "true" 0 "false" ;
VAL_ 1930 DTCIUnused7_78A 1 "true" 0 "false" ;
VAL_ 1930 DTCI_WrnIndRqdSt_78A 1 "true" 0 "false" ;
SIG_GROUP_ 313 IntlStdAlph2CddCntryCd 1 : ISA2CCC_ScndCdChr ISA2CCC_FrstCdChr;
SIG_GROUP_ 1275 BrkSysCtl2EmnsRelDTC 1 : BSC2ERDTC_CdNum BSC2ERDTC_SysDes;
SIG_GROUP_ 532 BrkPdDrvAppPrsStat 1 : BPDAPS_BkPDrvApPV BPDAPS_BkPDrvApP;
SIG_GROUP_ 489 BrkSysTransGearReq 1 : BSTGRReqdGear BSTGRReqType;
SIG_GROUP_ 338 CoPEPSWhlAngReq 1 : CPEPSWAR_TrgtAng CPEPSWAR_ReqdState;
SIG_GROUP_ 753 ElecBrkCntlMdlDiagSt5 1 : EBCMDS5_DTCStatus EBCMDS5_DTCIndex;
SIG_GROUP_ 753 ElecBrkCntlMdlDiagSt4 1 : EBCMDS4_DTCStatus EBCMDS4_DTCIndex;
SIG_GROUP_ 753 ElecBrkCntlMdlDiagSt3 1 : EBCMDS3_DTCStatus EBCMDS3_DTCIndex;
SIG_GROUP_ 753 ElecBrkCntlMdlDiagSt2 1 : EBCMDS2_DTCStatus EBCMDS2_DTCIndex;
SIG_GROUP_ 753 ElecBrkCntlMdlDiagSt1 1 : EBCMDS1_DTCStatus EBCMDS1_DTCIndex;
SIG_GROUP_ 869 ColPrepSysCustAvail 1 : CPSCA_Resrv3Avail CPSCA_Resrv2Avail CPSCA_Resrv1Avail CPSCA_AlrtBrkStrAvail CPSCA_AlrtBrkAvail CPSCA_AlrtAvail CPSCA_OffAvail;
SIG_GROUP_ 1905 DTCInfo_771 1 : DTCI_DTCFaultType_771 DTCI_CodeSupported_771 DTCI_CurrentStatus_771 DTCI_TstNPsdCdClrdSt_771 DTCI_TstFldCdClrdStat_771 DTCI_HistStat_771 DTCI_TstNPsdPwrUpSt_771 DTCI_TstFldPwrUpSt_771 DTCI_WrnIndRqdSt_771 DTCI_DTCFailType_771 DTCI_DTCNumber_771 DTCI_DTCSource_771 DTCI_DTCTriggered_771 DTCIUnused7_771 DTCIUnused6_771 DTCIUnused5_771 DTCIUnused4_771 DTCIUnused3_771 DTCIUnused2_771 DTCIUnused1_771;
SIG_GROUP_ 1930 DTCInfo_78A 1 : DTCI_CodeSupported_78A DTCI_CurrentStatus_78A DTCI_DTCFailType_78A DTCI_DTCFaultType_78A DTCI_DTCNumber_78A DTCI_DTCSource_78A DTCI_DTCTriggered_78A DTCI_HistStat_78A DTCI_TstFldCdClrdStat_78A DTCI_TstFldPwrUpSt_78A DTCI_TstNPsdCdClrdSt_78A DTCI_TstNPsdPwrUpSt_78A DTCIUnused1_78A DTCIUnused2_78A DTCIUnused3_78A DTCIUnused4_78A DTCIUnused5_78A DTCIUnused6_78A DTCIUnused7_78A DTCI_WrnIndRqdSt_78A;
